VERSION "dbc-export 1 2026.26.6.5"

NS_ :

BS_:

BU_: APP APS BMS CC CMP CMPD CP DAS DI DIF DIR EPBL EPBR EVSE FC GTW HCML HCMR HVP ICR PCS PCS2 PLG PM PMF PMR PTC SCCM SCM SCS SDCR TAS UMC V2G VC VCBATT VCBATT0 VCBATT1 VCBATT2 VCFRONT VCFRONT1 VCFRONT2 VCLEFT VCRIGHT VCSEAT2L VCSEAT2R VCSEC

BO_ 1351 VCFRONT2_alertLog: 8 VCFRONT2
 SG_ VCFRONT2_alertID M : 0|10@1+ (1,0) [0|1023] "" Vector__XXX
 SG_ VCFRONT2_alertState : 15|1@1+ (1,0) [0|1] "" Vector__XXX
 SG_ VCFRONT2_a001_InternalWatchdog m1 : 16|1@1+ (1,0) [0|1] "" Vector__XXX
 SG_ VCFRONT2_a015_NVMMMemOverflow m15 : 16|1@1+ (1,0) [0|1] "" Vector__XXX
 SG_ VCFRONT2_a015_NVMMFilesystemErro m15 : 17|1@1+ (1,0) [0|1] "" Vector__XXX
 SG_ VCFRONT2_a015_NVMMRecordIDError m15 : 18|1@1+ (1,0) [0|1] "" Vector__XXX
 SG_ VCFRONT2_a059_voltageDrop m59 : 16|12@1+ (0.005443676,0) [0|22.29185322] "V" Vector__XXX
 SG_ VCFRONT2_a059_resistanceEstimate m59 : 28|12@1+ (0.00244,0) [0|9.9918] "Ohms" Vector__XXX
 SG_ VCFRONT2_a059_current m59 : 40|12@1+ (0.05,0) [0|204.75] "A" Vector__XXX
 SG_ VCFRONT2_a063_switchChannel m63 : 16|8@1+ (1,0) [0|255] "" Vector__XXX
 SG_ VCFRONT2_a063_switchType m63 : 24|8@1+ (1,0) [0|255] "" Vector__XXX
 SG_ VCFRONT2_a063_ADCVoltage m63 : 32|8@1+ (0.025,0) [0|6.375] "V" Vector__XXX
 SG_ VCFRONT2_a063_disconnected m63 : 40|1@1+ (1,0) [0|1] "" Vector__XXX
 SG_ VCFRONT2_a063_indeterminate m63 : 41|1@1+ (1,0) [0|1] "" Vector__XXX
 SG_ VCFRONT2_a063_stuckActive m63 : 42|1@1+ (1,0) [0|1] "" Vector__XXX
 SG_ VCFRONT2_a063_faulted m63 : 43|1@1+ (1,0) [0|1] "" Vector__XXX
 SG_ VCFRONT2_a091_FRONTIPC_faultsAnd m91 : 16|1@1+ (1,0) [0|1] "" Vector__XXX
 SG_ VCFRONT2_a091_FRONTIPC_state m91 : 17|1@1+ (1,0) [0|1] "" Vector__XXX
 SG_ VCFRONT2_a096_FRONTIPC_status m96 : 16|1@1+ (1,0) [0|1] "" Vector__XXX
 SG_ VCFRONT2_a098_FRONTIPC_temperatu m98 : 16|1@1+ (1,0) [0|1] "" Vector__XXX
 SG_ VCFRONT2_a098_FRONTIPC_thermalCo m98 : 17|1@1+ (1,0) [0|1] "" Vector__XXX
 SG_ VCFRONT2_a106_BATTIPC_dcdcRailSt m106 : 16|1@1+ (1,0) [0|1] "" Vector__XXX
 SG_ VCFRONT2_a106_BATTIPC_dcdcStatus m106 : 17|1@1+ (1,0) [0|1] "" Vector__XXX
 SG_ VCFRONT2_a106_VEH_dcdcStatus m106 : 18|1@1+ (1,0) [0|1] "" Vector__XXX
 SG_ VCFRONT2_a106_VEH_thermalControl m106 : 19|1@1+ (1,0) [0|1] "" Vector__XXX
 SG_ VCFRONT2_a106_VEH_dcdcRailStatus m106 : 20|1@1+ (1,0) [0|1] "" Vector__XXX
 SG_ VCFRONT2_a106_CH_dcdcRailStatus m106 : 21|1@1+ (1,0) [0|1] "" Vector__XXX
 SG_ VCFRONT2_a106_CH_alertMatrix m106 : 22|1@1+ (1,0) [0|1] "" Vector__XXX
 SG_ VCFRONT2_a106_FRONTIPC_thermalCo m106 : 23|1@1+ (1,0) [0|1] "" Vector__XXX
 SG_ VCFRONT2_a106_FRONTIPC_dcdcRailS m106 : 24|1@1+ (1,0) [0|1] "" Vector__XXX
 SG_ VCFRONT2_a106_FRONTIPC_dcdcStatu m106 : 25|1@1+ (1,0) [0|1] "" Vector__XXX
 SG_ VCFRONT2_a108_FRONTIPC_status m108 : 16|1@1+ (1,0) [0|1] "" Vector__XXX
 SG_ VCFRONT2_a108_FRONTIPC_temperatu m108 : 17|1@1+ (1,0) [0|1] "" Vector__XXX
 SG_ VCFRONT2_a108_FRONTIPC_thermalCo m108 : 18|1@1+ (1,0) [0|1] "" Vector__XXX
 SG_ VCFRONT2_a108_FRONTIPC_motorStat m108 : 19|1@1+ (1,0) [0|1] "" Vector__XXX
 SG_ VCFRONT2_a120_BATTIPC_speed m120 : 16|1@1+ (1,0) [0|1] "" Vector__XXX
 SG_ VCFRONT2_a120_FRONTIPC_speed m120 : 17|1@1+ (1,0) [0|1] "" Vector__XXX
 SG_ VCFRONT2_a120_FRONTIPC_systemSta m120 : 18|1@1+ (1,0) [0|1] "" Vector__XXX
 SG_ VCFRONT2_a120_BATTIPC_systemStat m120 : 19|1@1+ (1,0) [0|1] "" Vector__XXX
 SG_ VCFRONT2_a120_FRONTIPC_systemPow m120 : 20|1@1+ (1,0) [0|1] "" Vector__XXX
 SG_ VCFRONT2_a120_FRONTIPC_autonomyH m120 : 21|1@1+ (1,0) [0|1] "" Vector__XXX
 SG_ VCFRONT2_a120_BATTIPC_chassisCon m120 : 22|1@1+ (1,0) [0|1] "" Vector__XXX
 SG_ VCFRONT2_a120_FRONTIPC_chassisCo m120 : 23|1@1+ (1,0) [0|1] "" Vector__XXX
 SG_ VCFRONT2_a120_FRONTIPC_odometerS m120 : 24|1@1+ (1,0) [0|1] "" Vector__XXX
 SG_ VCFRONT2_a124_FRONTIPC_status m124 : 16|1@1+ (1,0) [0|1] "" Vector__XXX
 SG_ VCFRONT2_a124_BATTIPC_status m124 : 17|1@1+ (1,0) [0|1] "" Vector__XXX
 SG_ VCFRONT2_a125_FRONTIPC_leftStalk m125 : 16|1@1+ (1,0) [0|1] "" Vector__XXX
 SG_ VCFRONT2_a125_FRONTIPC_steerAngl m125 : 17|1@1+ (1,0) [0|1] "" Vector__XXX
 SG_ VCFRONT2_a125_FRONTIPC_info m125 : 18|1@1+ (1,0) [0|1] "" Vector__XXX
 SG_ VCFRONT2_a126_FRONTIPC_sysStatus m126 : 16|1@1+ (1,0) [0|1] "" Vector__XXX
 SG_ VCFRONT2_a126_BATTIPC_sysStatus m126 : 17|1@1+ (1,0) [0|1] "" Vector__XXX
 SG_ VCFRONT2_a126_FRONTIPC_status m126 : 18|1@1+ (1,0) [0|1] "" Vector__XXX
 SG_ VCFRONT2_a126_BATTIPC_status m126 : 19|1@1+ (1,0) [0|1] "" Vector__XXX
 SG_ VCFRONT2_a131_FRONTIPC_power m131 : 16|1@1+ (1,0) [0|1] "" Vector__XXX
 SG_ VCFRONT2_a131_BATTIPC_power m131 : 17|1@1+ (1,0) [0|1] "" Vector__XXX
 SG_ VCFRONT2_a133_BATTIPC_primaryAct m133 : 16|1@1+ (1,0) [0|1] "" Vector__XXX
 SG_ VCFRONT2_a133_FRONTIPC_secondary m133 : 17|1@1+ (1,0) [0|1] "" Vector__XXX
 SG_ VCFRONT2_a142_driverState m142 : 16|4@1+ (1,0) [0|15] "" Vector__XXX
 SG_ VCFRONT2_a142_driverThermWarn m142 : 20|1@1+ (1,0) [0|1] "" Vector__XXX
 SG_ VCFRONT2_a142_driverThermShutdow m142 : 21|1@1+ (1,0) [0|1] "" Vector__XXX
 SG_ VCFRONT2_a142_undervoltage m142 : 22|1@1+ (1,0) [0|1] "" Vector__XXX
 SG_ VCFRONT2_a142_chargePumpUndervol m142 : 23|1@1+ (1,0) [0|1] "" Vector__XXX
 SG_ VCFRONT2_a142_isCoilOpenX m142 : 24|1@1+ (1,0) [0|1] "" Vector__XXX
 SG_ VCFRONT2_a142_isCoilOpenY m142 : 25|1@1+ (1,0) [0|1] "" Vector__XXX
 SG_ VCFRONT2_a142_isCoilShortXPGnd m142 : 26|1@1+ (1,0) [0|1] "" Vector__XXX
 SG_ VCFRONT2_a142_isCoilShortXPVbb m142 : 27|1@1+ (1,0) [0|1] "" Vector__XXX
 SG_ VCFRONT2_a142_isCoilShortXNGnd m142 : 28|1@1+ (1,0) [0|1] "" Vector__XXX
 SG_ VCFRONT2_a142_isCoilShortXNVbb m142 : 29|1@1+ (1,0) [0|1] "" Vector__XXX
 SG_ VCFRONT2_a142_isCoilShortYPGnd m142 : 30|1@1+ (1,0) [0|1] "" Vector__XXX
 SG_ VCFRONT2_a142_isCoilShortYPVbb m142 : 31|1@1+ (1,0) [0|1] "" Vector__XXX
 SG_ VCFRONT2_a142_isCoilShortYNGnd m142 : 32|1@1+ (1,0) [0|1] "" Vector__XXX
 SG_ VCFRONT2_a142_isCoilShortYNVbb m142 : 33|1@1+ (1,0) [0|1] "" Vector__XXX
 SG_ VCFRONT2_a142_driverHasCommError m142 : 34|1@1+ (1,0) [0|1] "" Vector__XXX
 SG_ VCFRONT2_a144_FRONTIPC_status m144 : 16|1@1+ (1,0) [0|1] "" Vector__XXX
 SG_ VCFRONT2_a144_BATTIPC_status m144 : 17|1@1+ (1,0) [0|1] "" Vector__XXX
 SG_ VCFRONT2_a150_RPMActual m150 : 16|10@1+ (10,0) [0|10230] "RPM" Vector__XXX
 SG_ VCFRONT2_a150_RPMTarget m150 : 26|10@1+ (10,0) [0|10230] "RPM" Vector__XXX
 SG_ VCFRONT2_a159_stall m159 : 16|1@1+ (1,0) [0|1] "" Vector__XXX
 SG_ VCFRONT2_a159_angleActual m159 : 17|10@1+ (0.25,-70) [-70|185.75] "deg" Vector__XXX
 SG_ VCFRONT2_a159_angleTarget m159 : 27|10@1+ (0.25,-10) [-10|245.75] "deg" Vector__XXX
 SG_ VCFRONT2_a171_VCFRONT m171 : 16|1@1+ (1,0) [0|1] "" Vector__XXX
 SG_ VCFRONT2_a171_VCRIGHT m171 : 17|1@1+ (1,0) [0|1] "" Vector__XXX
 SG_ VCFRONT2_a171_VCLEFT m171 : 18|1@1+ (1,0) [0|1] "" Vector__XXX
 SG_ VCFRONT2_a171_VCBATT m171 : 19|1@1+ (1,0) [0|1] "" Vector__XXX
 SG_ VCFRONT2_a171_BMS m171 : 20|1@1+ (1,0) [0|1] "" Vector__XXX
 SG_ VCFRONT2_a171_HVP m171 : 21|1@1+ (1,0) [0|1] "" Vector__XXX
 SG_ VCFRONT2_a171_GTW m171 : 22|1@1+ (1,0) [0|1] "" Vector__XXX
 SG_ VCFRONT2_a171_CP m171 : 23|1@1+ (1,0) [0|1] "" Vector__XXX
 SG_ VCFRONT2_a171_PCS m171 : 24|1@1+ (1,0) [0|1] "" Vector__XXX
 SG_ VCFRONT2_a171_PCSCPU2 m171 : 25|1@1+ (1,0) [0|1] "" Vector__XXX
 SG_ VCFRONT2_a171_DI m171 : 26|1@1+ (1,0) [0|1] "" Vector__XXX
 SG_ VCFRONT2_a171_DIS m171 : 27|1@1+ (1,0) [0|1] "" Vector__XXX
 SG_ VCFRONT2_a171_PM m171 : 28|1@1+ (1,0) [0|1] "" Vector__XXX
 SG_ VCFRONT2_a171_PMS m171 : 29|1@1+ (1,0) [0|1] "" Vector__XXX
 SG_ VCFRONT2_a171_EPBR m171 : 30|1@1+ (1,0) [0|1] "" Vector__XXX
 SG_ VCFRONT2_a171_EPBL m171 : 31|1@1+ (1,0) [0|1] "" Vector__XXX
 SG_ VCFRONT2_a171_IBST m171 : 32|1@1+ (1,0) [0|1] "" Vector__XXX
 SG_ VCFRONT2_a171_IBSTCAL m171 : 33|1@1+ (1,0) [0|1] "" Vector__XXX
 SG_ VCFRONT2_a171_ESP m171 : 34|1@1+ (1,0) [0|1] "" Vector__XXX
 SG_ VCFRONT2_a171_ESPCAL m171 : 35|1@1+ (1,0) [0|1] "" Vector__XXX
 SG_ VCFRONT2_a171_OPC m171 : 36|1@1+ (1,0) [0|1] "" Vector__XXX
 SG_ VCFRONT2_a171_OPCS m171 : 37|1@1+ (1,0) [0|1] "" Vector__XXX
 SG_ VCFRONT2_a171_SCCM m171 : 38|1@1+ (1,0) [0|1] "" Vector__XXX
 SG_ VCFRONT2_a171_LVBMS m171 : 39|1@1+ (1,0) [0|1] "" Vector__XXX
 SG_ VCFRONT2_a171_IDB m171 : 40|1@1+ (1,0) [0|1] "" Vector__XXX
 SG_ VCFRONT2_a171_IDB1 m171 : 41|1@1+ (1,0) [0|1] "" Vector__XXX
 SG_ VCFRONT2_a171_IDBCAL m171 : 42|1@1+ (1,0) [0|1] "" Vector__XXX
 SG_ VCFRONT2_a171_RCU m171 : 43|1@1+ (1,0) [0|1] "" Vector__XXX
 SG_ VCFRONT2_a171_RCUCAL m171 : 44|1@1+ (1,0) [0|1] "" Vector__XXX
 SG_ VCFRONT2_a171_DPB m171 : 45|1@1+ (1,0) [0|1] "" Vector__XXX
 SG_ VCFRONT2_a171_DPBCAL m171 : 46|1@1+ (1,0) [0|1] "" Vector__XXX
 SG_ VCFRONT2_a171_serviceMode m171 : 47|1@1+ (1,0) [0|1] "" Vector__XXX
 SG_ VCFRONT2_a172_ECUMismatchBits m172 : 16|47@1+ (1,0) [0|140737488355327] "" Vector__XXX
 SG_ VCFRONT2_a172_serviceMode m172 : 63|1@1+ (1,0) [0|1] "" Vector__XXX
 SG_ VCFRONT2_a173_ECUMismatchBits m173 : 16|47@1+ (1,0) [0|140737488355327] "" Vector__XXX
 SG_ VCFRONT2_a173_serviceMode m173 : 63|1@1+ (1,0) [0|1] "" Vector__XXX
 SG_ VCFRONT2_a176_vehicleState m176 : 16|5@1+ (1,0) [0|31] "" Vector__XXX
 SG_ VCFRONT2_a186_noDriveChgCableCon m186 : 16|1@1+ (1,0) [0|1] "" Vector__XXX
 SG_ VCFRONT2_a187_vehBusRetryCount m187 : 16|9@1+ (1,0) [0|511] "" Vector__XXX
 SG_ VCFRONT2_a187_partyBusRetryCount m187 : 25|9@1+ (1,0) [0|511] "" Vector__XXX
 SG_ VCFRONT2_a187_hvsBusRetryCount m187 : 34|9@1+ (1,0) [0|511] "" Vector__XXX
 SG_ VCFRONT2_a187_ethBusRetryCount m187 : 43|9@1+ (1,0) [0|511] "" Vector__XXX
 SG_ VCFRONT2_a187_chBusRetryCount m187 : 52|9@1+ (1,0) [0|511] "" Vector__XXX
 SG_ VCFRONT2_a195_LVVoltage m195 : 16|12@1+ (0.005443676,0) [0|22.29185322] "V" Vector__XXX
 SG_ VCFRONT2_a195_serviceMode m195 : 28|1@1+ (1,0) [0|1] "" Vector__XXX
 SG_ VCFRONT2_a195_frunkOpen m195 : 29|1@1+ (1,0) [0|1] "" Vector__XXX
 SG_ VCFRONT2_a210_valveUnderTravel m210 : 16|1@1+ (1,0) [0|1] "" Vector__XXX
 SG_ VCFRONT2_a210_valveOverTravel m210 : 17|1@1+ (1,0) [0|1] "" Vector__XXX
 SG_ VCFRONT2_a210_valveNoTravel m210 : 18|1@1+ (1,0) [0|1] "" Vector__XXX
 SG_ VCFRONT2_a214_motorFaulted m214 : 16|1@1+ (1,0) [0|1] "" Vector__XXX
 SG_ VCFRONT2_a214_motorLocked m214 : 17|1@1+ (1,0) [0|1] "" Vector__XXX
 SG_ VCFRONT2_a214_ecuReset m214 : 18|1@1+ (1,0) [0|1] "" Vector__XXX
 SG_ VCFRONT2_a214_fetTempIrrational m214 : 19|1@1+ (1,0) [0|1] "" Vector__XXX
 SG_ VCFRONT2_a214_motorControlError m214 : 20|1@1+ (1,0) [0|1] "" Vector__XXX
 SG_ VCFRONT2_a214_underVoltage m214 : 21|1@1+ (1,0) [0|1] "" Vector__XXX
 SG_ VCFRONT2_a214_overVoltage m214 : 22|1@1+ (1,0) [0|1] "" Vector__XXX
 SG_ VCFRONT2_a214_hardwareOvercurren m214 : 23|1@1+ (1,0) [0|1] "" Vector__XXX
 SG_ VCFRONT2_a214_motorOpenPhase m214 : 24|1@1+ (1,0) [0|1] "" Vector__XXX
 SG_ VCFRONT2_a214_motorSoftOpenPhase m214 : 25|1@1+ (1,0) [0|1] "" Vector__XXX
 SG_ VCFRONT2_a214_motorOvertemp m214 : 26|1@1+ (1,0) [0|1] "" Vector__XXX
 SG_ VCFRONT2_a214_dcOvercurrent m214 : 27|1@1+ (1,0) [0|1] "" Vector__XXX
 SG_ VCFRONT2_a214_motorStalled m214 : 28|1@1+ (1,0) [0|1] "" Vector__XXX
 SG_ VCFRONT2_a214_selfTestFailed m214 : 29|1@1+ (1,0) [0|1] "" Vector__XXX
 SG_ VCFRONT2_a214_selfTestResult m214 : 32|3@1+ (1,0) [0|7] "" Vector__XXX
 SG_ VCFRONT2_a214_linChecksumError m214 : 35|1@1+ (1,0) [0|1] "" Vector__XXX
 SG_ VCFRONT2_a214_linFramingError m214 : 36|1@1+ (1,0) [0|1] "" Vector__XXX
 SG_ VCFRONT2_a214_phaseShorted m214 : 37|1@1+ (1,0) [0|1] "" Vector__XXX
 SG_ VCFRONT2_a214_busVoltageIrration m214 : 38|1@1+ (1,0) [0|1] "" Vector__XXX
 SG_ VCFRONT2_a214_dcCurrentIrrationa m214 : 39|1@1+ (1,0) [0|1] "" Vector__XXX
 SG_ VCFRONT2_a214_motorSpeedIrration m214 : 40|1@1+ (1,0) [0|1] "" Vector__XXX
 SG_ VCFRONT2_a214_supplyVoltageIrrat m214 : 41|1@1+ (1,0) [0|1] "" Vector__XXX
 SG_ VCFRONT2_a214_motorPhaseCurrentI m214 : 42|1@1+ (1,0) [0|1] "" Vector__XXX
 SG_ VCFRONT2_a214_chipOvertemp m214 : 43|1@1+ (1,0) [0|1] "" Vector__XXX
 SG_ VCFRONT2_a214_motorSpeedTooHigh m214 : 44|1@1+ (1,0) [0|1] "" Vector__XXX
 SG_ VCFRONT2_a214_phaseOvercurrent m214 : 45|1@1+ (1,0) [0|1] "" Vector__XXX
 SG_ VCFRONT2_a214_vddaOvercurrent m214 : 46|1@1+ (1,0) [0|1] "" Vector__XXX
 SG_ VCFRONT2_a214_busVoltageUnhealth m214 : 47|1@1+ (1,0) [0|1] "" Vector__XXX
 SG_ VCFRONT2_a214_hsVdsOvervoltage m214 : 48|1@1+ (1,0) [0|1] "" Vector__XXX
 SG_ VCFRONT2_a214_hsVdsOvervoltageMa m214 : 49|3@1+ (1,0) [0|7] "" Vector__XXX
 SG_ VCFRONT2_a214_lsVdsOvervoltage m214 : 52|1@1+ (1,0) [0|1] "" Vector__XXX
 SG_ VCFRONT2_a214_lsVdsOvervoltageMa m214 : 53|3@1+ (1,0) [0|7] "" Vector__XXX
 SG_ VCFRONT2_a214_payloadBitsNotSet m214 : 56|1@1+ (1,0) [0|1] "" Vector__XXX
 SG_ VCFRONT2_a217_motorFaulted m217 : 16|1@1+ (1,0) [0|1] "" Vector__XXX
 SG_ VCFRONT2_a217_motorLocked m217 : 17|1@1+ (1,0) [0|1] "" Vector__XXX
 SG_ VCFRONT2_a217_ecuReset m217 : 18|1@1+ (1,0) [0|1] "" Vector__XXX
 SG_ VCFRONT2_a217_fetTempIrrational m217 : 19|1@1+ (1,0) [0|1] "" Vector__XXX
 SG_ VCFRONT2_a217_motorControlError m217 : 20|1@1+ (1,0) [0|1] "" Vector__XXX
 SG_ VCFRONT2_a217_underVoltage m217 : 21|1@1+ (1,0) [0|1] "" Vector__XXX
 SG_ VCFRONT2_a217_overVoltage m217 : 22|1@1+ (1,0) [0|1] "" Vector__XXX
 SG_ VCFRONT2_a217_hardwareOvercurren m217 : 23|1@1+ (1,0) [0|1] "" Vector__XXX
 SG_ VCFRONT2_a217_motorOpenPhase m217 : 24|1@1+ (1,0) [0|1] "" Vector__XXX
 SG_ VCFRONT2_a217_motorSoftOpenPhase m217 : 25|1@1+ (1,0) [0|1] "" Vector__XXX
 SG_ VCFRONT2_a217_motorOvertemp m217 : 26|1@1+ (1,0) [0|1] "" Vector__XXX
 SG_ VCFRONT2_a217_dcOvercurrent m217 : 27|1@1+ (1,0) [0|1] "" Vector__XXX
 SG_ VCFRONT2_a217_motorStalled m217 : 28|1@1+ (1,0) [0|1] "" Vector__XXX
 SG_ VCFRONT2_a217_selfTestFailed m217 : 29|1@1+ (1,0) [0|1] "" Vector__XXX
 SG_ VCFRONT2_a217_selfTestResult m217 : 32|3@1+ (1,0) [0|7] "" Vector__XXX
 SG_ VCFRONT2_a217_linChecksumError m217 : 35|1@1+ (1,0) [0|1] "" Vector__XXX
 SG_ VCFRONT2_a217_linFramingError m217 : 36|1@1+ (1,0) [0|1] "" Vector__XXX
 SG_ VCFRONT2_a217_phaseShorted m217 : 37|1@1+ (1,0) [0|1] "" Vector__XXX
 SG_ VCFRONT2_a217_busVoltageIrration m217 : 38|1@1+ (1,0) [0|1] "" Vector__XXX
 SG_ VCFRONT2_a217_dcCurrentIrrationa m217 : 39|1@1+ (1,0) [0|1] "" Vector__XXX
 SG_ VCFRONT2_a217_motorSpeedIrration m217 : 40|1@1+ (1,0) [0|1] "" Vector__XXX
 SG_ VCFRONT2_a217_supplyVoltageIrrat m217 : 41|1@1+ (1,0) [0|1] "" Vector__XXX
 SG_ VCFRONT2_a217_motorPhaseCurrentI m217 : 42|1@1+ (1,0) [0|1] "" Vector__XXX
 SG_ VCFRONT2_a217_chipOvertemp m217 : 43|1@1+ (1,0) [0|1] "" Vector__XXX
 SG_ VCFRONT2_a217_motorSpeedTooHigh m217 : 44|1@1+ (1,0) [0|1] "" Vector__XXX
 SG_ VCFRONT2_a217_phaseOvercurrent m217 : 45|1@1+ (1,0) [0|1] "" Vector__XXX
 SG_ VCFRONT2_a217_vddaOvercurrent m217 : 46|1@1+ (1,0) [0|1] "" Vector__XXX
 SG_ VCFRONT2_a217_busVoltageUnhealth m217 : 47|1@1+ (1,0) [0|1] "" Vector__XXX
 SG_ VCFRONT2_a217_hsVdsOvervoltage m217 : 48|1@1+ (1,0) [0|1] "" Vector__XXX
 SG_ VCFRONT2_a217_hsVdsOvervoltageMa m217 : 49|3@1+ (1,0) [0|7] "" Vector__XXX
 SG_ VCFRONT2_a217_lsVdsOvervoltage m217 : 52|1@1+ (1,0) [0|1] "" Vector__XXX
 SG_ VCFRONT2_a217_lsVdsOvervoltageMa m217 : 53|3@1+ (1,0) [0|7] "" Vector__XXX
 SG_ VCFRONT2_a217_payloadBitsNotSet m217 : 56|1@1+ (1,0) [0|1] "" Vector__XXX
 SG_ VCFRONT2_a235_ptSensorTemp m235 : 16|11@1+ (0.125,-40) [-40|215.875] "degC" Vector__XXX
 SG_ VCFRONT2_a236_batSensorTemp m236 : 16|11@1+ (0.125,-40) [-40|215.875] "degC" Vector__XXX
 SG_ VCFRONT2_a247_solenoidISense m247 : 16|8@1- (0.01,0) [-1.28|1.27] "A" Vector__XXX
 SG_ VCFRONT2_a249_tempCoolantBatInle m249 : 16|10@1+ (0.125,-40) [-40|87.875] "degC" Vector__XXX
 SG_ VCFRONT2_a249_tempCoolantPTInlet m249 : 26|11@1+ (0.125,-40) [-40|215.875] "degC" Vector__XXX
 SG_ VCFRONT2_a254_RPMActual m254 : 16|10@1+ (10,0) [0|10230] "RPM" Vector__XXX
 SG_ VCFRONT2_a254_RPMTarget m254 : 26|10@1+ (10,0) [0|10230] "RPM" Vector__XXX
 SG_ VCFRONT2_a283_thmlFanDisabled m283 : 16|1@1+ (1,0) [0|1] "" Vector__XXX
 SG_ VCFRONT2_a283_thmlFanLimited m283 : 17|1@1+ (1,0) [0|1] "" Vector__XXX
 SG_ VCFRONT2_a283_thmlFanDemand m283 : 24|7@1+ (1,0) [0|127] "%" Vector__XXX
 SG_ VCFRONT2_a283_thmlFanDemandLimit m283 : 32|7@1+ (1,0) [0|127] "%" Vector__XXX
 SG_ VCFRONT2_a283_thmlFanPhaseI m283 : 40|7@1+ (0.25,5) [5|36.75] "A" Vector__XXX
 SG_ VCFRONT2_a283_thmlFanPhaseILimit m283 : 48|7@1+ (0.25,5) [5|36.75] "A" Vector__XXX
 SG_ VCFRONT2_a284_driverState m284 : 16|4@1+ (1,0) [0|15] "" Vector__XXX
 SG_ VCFRONT2_a284_driverThermWarn m284 : 20|1@1+ (1,0) [0|1] "" Vector__XXX
 SG_ VCFRONT2_a284_driverThermShutdow m284 : 21|1@1+ (1,0) [0|1] "" Vector__XXX
 SG_ VCFRONT2_a284_undervoltage m284 : 22|1@1+ (1,0) [0|1] "" Vector__XXX
 SG_ VCFRONT2_a284_chargePumpUndervol m284 : 23|1@1+ (1,0) [0|1] "" Vector__XXX
 SG_ VCFRONT2_a284_isCoilOpenX m284 : 24|1@1+ (1,0) [0|1] "" Vector__XXX
 SG_ VCFRONT2_a284_isCoilOpenY m284 : 25|1@1+ (1,0) [0|1] "" Vector__XXX
 SG_ VCFRONT2_a284_isCoilShortXPGnd m284 : 26|1@1+ (1,0) [0|1] "" Vector__XXX
 SG_ VCFRONT2_a284_isCoilShortXPVbb m284 : 27|1@1+ (1,0) [0|1] "" Vector__XXX
 SG_ VCFRONT2_a284_isCoilShortXNGnd m284 : 28|1@1+ (1,0) [0|1] "" Vector__XXX
 SG_ VCFRONT2_a284_isCoilShortXNVbb m284 : 29|1@1+ (1,0) [0|1] "" Vector__XXX
 SG_ VCFRONT2_a284_isCoilShortYPGnd m284 : 30|1@1+ (1,0) [0|1] "" Vector__XXX
 SG_ VCFRONT2_a284_isCoilShortYPVbb m284 : 31|1@1+ (1,0) [0|1] "" Vector__XXX
 SG_ VCFRONT2_a284_isCoilShortYNGnd m284 : 32|1@1+ (1,0) [0|1] "" Vector__XXX
 SG_ VCFRONT2_a284_isCoilShortYNVbb m284 : 33|1@1+ (1,0) [0|1] "" Vector__XXX
 SG_ VCFRONT2_a284_driverHasCommError m284 : 34|1@1+ (1,0) [0|1] "" Vector__XXX
 SG_ VCFRONT2_a285_driverState m285 : 16|4@1+ (1,0) [0|15] "" Vector__XXX
 SG_ VCFRONT2_a285_driverThermWarn m285 : 20|1@1+ (1,0) [0|1] "" Vector__XXX
 SG_ VCFRONT2_a285_driverThermShutdow m285 : 21|1@1+ (1,0) [0|1] "" Vector__XXX
 SG_ VCFRONT2_a285_undervoltage m285 : 22|1@1+ (1,0) [0|1] "" Vector__XXX
 SG_ VCFRONT2_a285_chargePumpUndervol m285 : 23|1@1+ (1,0) [0|1] "" Vector__XXX
 SG_ VCFRONT2_a285_isCoilOpenX m285 : 24|1@1+ (1,0) [0|1] "" Vector__XXX
 SG_ VCFRONT2_a285_isCoilOpenY m285 : 25|1@1+ (1,0) [0|1] "" Vector__XXX
 SG_ VCFRONT2_a285_isCoilShortXPGnd m285 : 26|1@1+ (1,0) [0|1] "" Vector__XXX
 SG_ VCFRONT2_a285_isCoilShortXPVbb m285 : 27|1@1+ (1,0) [0|1] "" Vector__XXX
 SG_ VCFRONT2_a285_isCoilShortXNGnd m285 : 28|1@1+ (1,0) [0|1] "" Vector__XXX
 SG_ VCFRONT2_a285_isCoilShortXNVbb m285 : 29|1@1+ (1,0) [0|1] "" Vector__XXX
 SG_ VCFRONT2_a285_isCoilShortYPGnd m285 : 30|1@1+ (1,0) [0|1] "" Vector__XXX
 SG_ VCFRONT2_a285_isCoilShortYPVbb m285 : 31|1@1+ (1,0) [0|1] "" Vector__XXX
 SG_ VCFRONT2_a285_isCoilShortYNGnd m285 : 32|1@1+ (1,0) [0|1] "" Vector__XXX
 SG_ VCFRONT2_a285_isCoilShortYNVbb m285 : 33|1@1+ (1,0) [0|1] "" Vector__XXX
 SG_ VCFRONT2_a285_driverHasCommError m285 : 34|1@1+ (1,0) [0|1] "" Vector__XXX
 SG_ VCFRONT2_a286_driverState m286 : 16|4@1+ (1,0) [0|15] "" Vector__XXX
 SG_ VCFRONT2_a286_driverThermWarn m286 : 20|1@1+ (1,0) [0|1] "" Vector__XXX
 SG_ VCFRONT2_a286_driverThermShutdow m286 : 21|1@1+ (1,0) [0|1] "" Vector__XXX
 SG_ VCFRONT2_a286_undervoltage m286 : 22|1@1+ (1,0) [0|1] "" Vector__XXX
 SG_ VCFRONT2_a286_chargePumpUndervol m286 : 23|1@1+ (1,0) [0|1] "" Vector__XXX
 SG_ VCFRONT2_a286_isCoilOpenX m286 : 24|1@1+ (1,0) [0|1] "" Vector__XXX
 SG_ VCFRONT2_a286_isCoilOpenY m286 : 25|1@1+ (1,0) [0|1] "" Vector__XXX
 SG_ VCFRONT2_a286_isCoilShortXPGnd m286 : 26|1@1+ (1,0) [0|1] "" Vector__XXX
 SG_ VCFRONT2_a286_isCoilShortXPVbb m286 : 27|1@1+ (1,0) [0|1] "" Vector__XXX
 SG_ VCFRONT2_a286_isCoilShortXNGnd m286 : 28|1@1+ (1,0) [0|1] "" Vector__XXX
 SG_ VCFRONT2_a286_isCoilShortXNVbb m286 : 29|1@1+ (1,0) [0|1] "" Vector__XXX
 SG_ VCFRONT2_a286_isCoilShortYPGnd m286 : 30|1@1+ (1,0) [0|1] "" Vector__XXX
 SG_ VCFRONT2_a286_isCoilShortYPVbb m286 : 31|1@1+ (1,0) [0|1] "" Vector__XXX
 SG_ VCFRONT2_a286_isCoilShortYNGnd m286 : 32|1@1+ (1,0) [0|1] "" Vector__XXX
 SG_ VCFRONT2_a286_isCoilShortYNVbb m286 : 33|1@1+ (1,0) [0|1] "" Vector__XXX
 SG_ VCFRONT2_a286_driverHasCommError m286 : 34|1@1+ (1,0) [0|1] "" Vector__XXX
 SG_ VCFRONT2_a287_driverState m287 : 16|4@1+ (1,0) [0|15] "" Vector__XXX
 SG_ VCFRONT2_a287_driverThermWarn m287 : 20|1@1+ (1,0) [0|1] "" Vector__XXX
 SG_ VCFRONT2_a287_driverThermShutdow m287 : 21|1@1+ (1,0) [0|1] "" Vector__XXX
 SG_ VCFRONT2_a287_undervoltage m287 : 22|1@1+ (1,0) [0|1] "" Vector__XXX
 SG_ VCFRONT2_a287_chargePumpUndervol m287 : 23|1@1+ (1,0) [0|1] "" Vector__XXX
 SG_ VCFRONT2_a287_isCoilOpenX m287 : 24|1@1+ (1,0) [0|1] "" Vector__XXX
 SG_ VCFRONT2_a287_isCoilOpenY m287 : 25|1@1+ (1,0) [0|1] "" Vector__XXX
 SG_ VCFRONT2_a287_isCoilShortXPGnd m287 : 26|1@1+ (1,0) [0|1] "" Vector__XXX
 SG_ VCFRONT2_a287_isCoilShortXPVbb m287 : 27|1@1+ (1,0) [0|1] "" Vector__XXX
 SG_ VCFRONT2_a287_isCoilShortXNGnd m287 : 28|1@1+ (1,0) [0|1] "" Vector__XXX
 SG_ VCFRONT2_a287_isCoilShortXNVbb m287 : 29|1@1+ (1,0) [0|1] "" Vector__XXX
 SG_ VCFRONT2_a287_isCoilShortYPGnd m287 : 30|1@1+ (1,0) [0|1] "" Vector__XXX
 SG_ VCFRONT2_a287_isCoilShortYPVbb m287 : 31|1@1+ (1,0) [0|1] "" Vector__XXX
 SG_ VCFRONT2_a287_isCoilShortYNGnd m287 : 32|1@1+ (1,0) [0|1] "" Vector__XXX
 SG_ VCFRONT2_a287_isCoilShortYNVbb m287 : 33|1@1+ (1,0) [0|1] "" Vector__XXX
 SG_ VCFRONT2_a287_driverHasCommError m287 : 34|1@1+ (1,0) [0|1] "" Vector__XXX
 SG_ VCFRONT2_a288_driverState m288 : 16|4@1+ (1,0) [0|15] "" Vector__XXX
 SG_ VCFRONT2_a288_driverThermWarn m288 : 20|1@1+ (1,0) [0|1] "" Vector__XXX
 SG_ VCFRONT2_a288_driverThermShutdow m288 : 21|1@1+ (1,0) [0|1] "" Vector__XXX
 SG_ VCFRONT2_a288_undervoltage m288 : 22|1@1+ (1,0) [0|1] "" Vector__XXX
 SG_ VCFRONT2_a288_chargePumpUndervol m288 : 23|1@1+ (1,0) [0|1] "" Vector__XXX
 SG_ VCFRONT2_a288_isCoilOpenX m288 : 24|1@1+ (1,0) [0|1] "" Vector__XXX
 SG_ VCFRONT2_a288_isCoilOpenY m288 : 25|1@1+ (1,0) [0|1] "" Vector__XXX
 SG_ VCFRONT2_a288_isCoilShortXPGnd m288 : 26|1@1+ (1,0) [0|1] "" Vector__XXX
 SG_ VCFRONT2_a288_isCoilShortXPVbb m288 : 27|1@1+ (1,0) [0|1] "" Vector__XXX
 SG_ VCFRONT2_a288_isCoilShortXNGnd m288 : 28|1@1+ (1,0) [0|1] "" Vector__XXX
 SG_ VCFRONT2_a288_isCoilShortXNVbb m288 : 29|1@1+ (1,0) [0|1] "" Vector__XXX
 SG_ VCFRONT2_a288_isCoilShortYPGnd m288 : 30|1@1+ (1,0) [0|1] "" Vector__XXX
 SG_ VCFRONT2_a288_isCoilShortYPVbb m288 : 31|1@1+ (1,0) [0|1] "" Vector__XXX
 SG_ VCFRONT2_a288_isCoilShortYNGnd m288 : 32|1@1+ (1,0) [0|1] "" Vector__XXX
 SG_ VCFRONT2_a288_isCoilShortYNVbb m288 : 33|1@1+ (1,0) [0|1] "" Vector__XXX
 SG_ VCFRONT2_a288_driverHasCommError m288 : 34|1@1+ (1,0) [0|1] "" Vector__XXX
 SG_ VCFRONT2_a289_driverState m289 : 16|4@1+ (1,0) [0|15] "" Vector__XXX
 SG_ VCFRONT2_a289_driverThermWarn m289 : 20|1@1+ (1,0) [0|1] "" Vector__XXX
 SG_ VCFRONT2_a289_driverThermShutdow m289 : 21|1@1+ (1,0) [0|1] "" Vector__XXX
 SG_ VCFRONT2_a289_undervoltage m289 : 22|1@1+ (1,0) [0|1] "" Vector__XXX
 SG_ VCFRONT2_a289_chargePumpUndervol m289 : 23|1@1+ (1,0) [0|1] "" Vector__XXX
 SG_ VCFRONT2_a289_isCoilOpenX m289 : 24|1@1+ (1,0) [0|1] "" Vector__XXX
 SG_ VCFRONT2_a289_isCoilOpenY m289 : 25|1@1+ (1,0) [0|1] "" Vector__XXX
 SG_ VCFRONT2_a289_isCoilShortXPGnd m289 : 26|1@1+ (1,0) [0|1] "" Vector__XXX
 SG_ VCFRONT2_a289_isCoilShortXPVbb m289 : 27|1@1+ (1,0) [0|1] "" Vector__XXX
 SG_ VCFRONT2_a289_isCoilShortXNGnd m289 : 28|1@1+ (1,0) [0|1] "" Vector__XXX
 SG_ VCFRONT2_a289_isCoilShortXNVbb m289 : 29|1@1+ (1,0) [0|1] "" Vector__XXX
 SG_ VCFRONT2_a289_isCoilShortYPGnd m289 : 30|1@1+ (1,0) [0|1] "" Vector__XXX
 SG_ VCFRONT2_a289_isCoilShortYPVbb m289 : 31|1@1+ (1,0) [0|1] "" Vector__XXX
 SG_ VCFRONT2_a289_isCoilShortYNGnd m289 : 32|1@1+ (1,0) [0|1] "" Vector__XXX
 SG_ VCFRONT2_a289_isCoilShortYNVbb m289 : 33|1@1+ (1,0) [0|1] "" Vector__XXX
 SG_ VCFRONT2_a289_driverHasCommError m289 : 34|1@1+ (1,0) [0|1] "" Vector__XXX
 SG_ VCFRONT2_a302_LINFrameStatus m302 : 16|3@1+ (1,0) [0|7] "" Vector__XXX
 SG_ VCFRONT2_a355_fluidNotFilled m355 : 16|1@1+ (1,0) [0|1] "" Vector__XXX
 SG_ VCFRONT2_a355_systemNotCommissio m355 : 17|1@1+ (1,0) [0|1] "" Vector__XXX
 SG_ VCFRONT2_a355_serviceLockout m355 : 18|1@1+ (1,0) [0|1] "" Vector__XXX
 SG_ VCFRONT2_a355_factoryGated m355 : 19|1@1+ (1,0) [0|1] "" Vector__XXX
 SG_ VCFRONT2_a356_fluidNotFilled m356 : 16|1@1+ (1,0) [0|1] "" Vector__XXX
 SG_ VCFRONT2_a356_systemNotCommissio m356 : 17|1@1+ (1,0) [0|1] "" Vector__XXX
 SG_ VCFRONT2_a356_serviceLockout m356 : 18|1@1+ (1,0) [0|1] "" Vector__XXX
 SG_ VCFRONT2_a356_factoryGated m356 : 19|1@1+ (1,0) [0|1] "" Vector__XXX
 SG_ VCFRONT2_a356_refCommissionStatu m356 : 20|1@1+ (1,0) [0|1] "" Vector__XXX
 SG_ VCFRONT2_a360_vehicleLoadShedAct m360 : 16|1@1+ (1,0) [0|1] "" Vector__XXX
 SG_ VCFRONT2_a360_notEnoughPowerForS m360 : 17|1@1+ (1,0) [0|1] "" Vector__XXX
 SG_ VCFRONT2_a367_bmsSoc m367 : 16|8@1+ (0.5,0) [0|127.5] "%" Vector__XXX
 SG_ VCFRONT2_a368_bmsRequestRemoved m368 : 16|1@1+ (1,0) [0|1] "" Vector__XXX
 SG_ VCFRONT2_a368_enteringState m368 : 17|3@1+ (1,0) [0|7] "" Vector__XXX
 SG_ VCFRONT2_a368_exitingState m368 : 20|3@1+ (1,0) [0|7] "" Vector__XXX
 SG_ VCFRONT2_a368_bmsSoc m368 : 24|8@1+ (0.5,0) [0|127.5] "%" Vector__XXX
 SG_ VCFRONT2_a368_systemFaulted m368 : 32|1@1+ (1,0) [0|1] "" Vector__XXX
 SG_ VCFRONT2_a368_coolantTempSensors m368 : 33|1@1+ (1,0) [0|1] "" Vector__XXX
 SG_ VCFRONT2_a368_coolantValveFaulte m368 : 34|1@1+ (1,0) [0|1] "" Vector__XXX
 SG_ VCFRONT2_a368_louverFaulted m368 : 35|1@1+ (1,0) [0|1] "" Vector__XXX
 SG_ VCFRONT2_a368_fansFaulted m368 : 36|1@1+ (1,0) [0|1] "" Vector__XXX
 SG_ VCFRONT2_a368_coolantNotFilled m368 : 37|1@1+ (1,0) [0|1] "" Vector__XXX
 SG_ VCFRONT2_a368_coolantPumpsFaulte m368 : 38|1@1+ (1,0) [0|1] "" Vector__XXX
 SG_ VCFRONT2_a368_preconditionsNotMe m368 : 39|1@1+ (1,0) [0|1] "" Vector__XXX
 SG_ VCFRONT2_a368_belowSocMin m368 : 40|1@1+ (1,0) [0|1] "" Vector__XXX
 SG_ VCFRONT2_a369_powerGenerationLim m369 : 16|1@1+ (1,0) [0|1] "" Vector__XXX
 SG_ VCFRONT2_a369_heatRejectionLimit m369 : 17|1@1+ (1,0) [0|1] "" Vector__XXX
 SG_ VCFRONT2_a369_bmsSoc m369 : 24|8@1+ (0.5,0) [0|127.5] "%" Vector__XXX
 SG_ VCFRONT2_a369_wasteHeatPower m369 : 32|7@1+ (100,0) [0|12700] "W" Vector__XXX
 SG_ VCFRONT2_a374_lccInletSolenoidIS m374 : 16|8@1- (0.01,0) [-1.28|1.27] "A" Vector__XXX
 SG_ VCFRONT2_a377_wiperStuckOutOfPar m377 : 16|1@1+ (1,0) [0|1] "" Vector__XXX
 SG_ VCFRONT2_a377_wiperStuckInPark m377 : 17|1@1+ (1,0) [0|1] "" Vector__XXX
 SG_ VCFRONT2_a397_discharge m397 : 16|1@1+ (1,0) [0|1] "" Vector__XXX
 SG_ VCFRONT2_a397_suction m397 : 17|1@1+ (1,0) [0|1] "" Vector__XXX
 SG_ VCFRONT2_a397_liquid m397 : 18|1@1+ (1,0) [0|1] "" Vector__XXX
 SG_ VCFRONT2_a397_offsetError m397 : 19|10@1- (0.2,0) [-102.4|102.2] "C" Vector__XXX
 SG_ VCFRONT2_a397_runTimeOffSetDetec m397 : 29|1@1+ (1,0) [0|1] "" Vector__XXX
 SG_ VCFRONT2_a409_brushlessMotorConf m409 : 16|1@1+ (1,0) [0|1] "" Vector__XXX
 SG_ VCFRONT2_a446_compFaultRefrigera m446 : 16|1@1+ (1,0) [0|1] "" Vector__XXX
 SG_ VCFRONT2_a446_compFaultTdHigh m446 : 17|1@1+ (1,0) [0|1] "" Vector__XXX
 SG_ VCFRONT2_a446_compFaultPdLow m446 : 18|1@1+ (1,0) [0|1] "" Vector__XXX
 SG_ VCFRONT2_a446_compFaultPdHigh m446 : 19|1@1+ (1,0) [0|1] "" Vector__XXX
 SG_ VCFRONT2_a446_compFaultPsLow m446 : 20|1@1+ (1,0) [0|1] "" Vector__XXX
 SG_ VCFRONT2_a446_compStandbyLowAmbi m446 : 21|1@1+ (1,0) [0|1] "" Vector__XXX
 SG_ VCFRONT2_a446_compStandbyLowDisc m446 : 22|1@1+ (1,0) [0|1] "" Vector__XXX
 SG_ VCFRONT2_a446_compStandbyHVNotRe m446 : 23|1@1+ (1,0) [0|1] "" Vector__XXX
 SG_ VCFRONT2_a446_compStandbyCommuni m446 : 24|1@1+ (1,0) [0|1] "" Vector__XXX
 SG_ VCFRONT2_a446_compStandbySelfNot m446 : 25|1@1+ (1,0) [0|1] "" Vector__XXX
 SG_ VCFRONT2_a446_compStandbyRefrigN m446 : 26|1@1+ (1,0) [0|1] "" Vector__XXX
 SG_ VCFRONT2_a446_compStandbyCoastDo m446 : 27|1@1+ (1,0) [0|1] "" Vector__XXX
 SG_ VCFRONT2_a446_compStandbyMultipl m446 : 28|1@1+ (1,0) [0|1] "" Vector__XXX
 SG_ VCFRONT2_a446_compStandbyShowroo m446 : 29|1@1+ (1,0) [0|1] "" Vector__XXX
 SG_ VCFRONT2_a446_compStandbyMu_0001 m446 : 30|1@1+ (1,0) [0|1] "" Vector__XXX
 SG_ VCFRONT2_a446_hpCabinLoadType m446 : 31|2@1+ (1,0) [0|3] "" Vector__XXX
 SG_ VCFRONT2_a446_hpBatteryLoadType m446 : 33|2@1+ (1,0) [0|3] "" Vector__XXX
 SG_ VCFRONT2_a446_usingModeledPs m446 : 35|1@1+ (1,0) [0|1] "" Vector__XXX
 SG_ VCFRONT2_a446_usingModeledPd m446 : 36|1@1+ (1,0) [0|1] "" Vector__XXX
 SG_ VCFRONT2_a446_usingModeledPl m446 : 37|1@1+ (1,0) [0|1] "" Vector__XXX
 SG_ VCFRONT2_a446_usingModeledTs m446 : 38|1@1+ (1,0) [0|1] "" Vector__XXX
 SG_ VCFRONT2_a446_usingModeledTd m446 : 39|1@1+ (1,0) [0|1] "" Vector__XXX
 SG_ VCFRONT2_a446_usingModeledTl m446 : 40|1@1+ (1,0) [0|1] "" Vector__XXX
 SG_ VCFRONT2_a446_sensorHasOffsetTd m446 : 41|1@1+ (1,0) [0|1] "" Vector__XXX
 SG_ VCFRONT2_a446_sensorHasOffsetPd m446 : 42|1@1+ (1,0) [0|1] "" Vector__XXX
 SG_ VCFRONT2_a446_sensorDroopPd m446 : 43|1@1+ (1,0) [0|1] "" Vector__XXX
 SG_ VCFRONT2_a446_sensorHasOffsetTl m446 : 44|1@1+ (1,0) [0|1] "" Vector__XXX
 SG_ VCFRONT2_a446_sensorIntermi_0002 m446 : 45|1@1+ (1,0) [0|1] "" Vector__XXX
 SG_ VCFRONT2_a446_sensorIntermittent m446 : 46|1@1+ (1,0) [0|1] "" Vector__XXX
 SG_ VCFRONT2_a446_sensorIntermi_0001 m446 : 47|1@1+ (1,0) [0|1] "" Vector__XXX
 SG_ VCFRONT2_a446_sensorIntermi_0005 m446 : 48|1@1+ (1,0) [0|1] "" Vector__XXX
 SG_ VCFRONT2_a446_sensorIntermi_0003 m446 : 49|1@1+ (1,0) [0|1] "" Vector__XXX
 SG_ VCFRONT2_a446_sensorIntermi_0004 m446 : 50|1@1+ (1,0) [0|1] "" Vector__XXX
 SG_ VCFRONT2_a446_highSuctionSuperhe m446 : 51|1@1+ (1,0) [0|1] "" Vector__XXX
 SG_ VCFRONT2_a446_evapLowPsCutout m446 : 52|1@1+ (1,0) [0|1] "" Vector__XXX
 SG_ VCFRONT2_a446_batteryOverTemp m446 : 53|1@1+ (1,0) [0|1] "" Vector__XXX
 SG_ VCFRONT2_a446_hvacSystemFault m446 : 54|1@1+ (1,0) [0|1] "" Vector__XXX
 SG_ VCFRONT2_a446_coolantSysLockedOu m446 : 55|1@1+ (1,0) [0|1] "" Vector__XXX
 SG_ VCFRONT2_a446_refSysLockedOut m446 : 56|1@1+ (1,0) [0|1] "" Vector__XXX
 SG_ VCFRONT2_a446_chillerEXVNotReady m446 : 57|1@1+ (1,0) [0|1] "" Vector__XXX
 SG_ VCFRONT2_a446_CCLEXVNotReady m446 : 58|1@1+ (1,0) [0|1] "" Vector__XXX
 SG_ VCFRONT2_a446_CCREXVNotReady m446 : 59|1@1+ (1,0) [0|1] "" Vector__XXX
 SG_ VCFRONT2_a446_LCCEXVNotReady m446 : 60|1@1+ (1,0) [0|1] "" Vector__XXX
 SG_ VCFRONT2_a446_evapEXVNotReady m446 : 61|1@1+ (1,0) [0|1] "" Vector__XXX
 SG_ VCFRONT2_a446_recircEXVNotReady m446 : 62|1@1+ (1,0) [0|1] "" Vector__XXX
 SG_ VCFRONT2_a446_checkA447Alert m446 : 63|1@1+ (1,0) [0|1] "" Vector__XXX
 SG_ VCFRONT2_a447_caseHVACUnavailabl m447 : 16|1@1+ (1,0) [0|1] "" Vector__XXX
 SG_ VCFRONT2_a447_heatPumpHVACUnavai m447 : 17|1@1+ (1,0) [0|1] "" Vector__XXX
 SG_ VCFRONT2_a447_activeLouverCompro m447 : 18|1@1+ (1,0) [0|1] "" Vector__XXX
 SG_ VCFRONT2_a447_coolantValveCompro m447 : 19|1@1+ (1,0) [0|1] "" Vector__XXX
 SG_ VCFRONT2_a447_ambientSourcingCom m447 : 20|1@1+ (1,0) [0|1] "" Vector__XXX
 SG_ VCFRONT2_a447_scavengeLoopCompro m447 : 21|1@1+ (1,0) [0|1] "" Vector__XXX
 SG_ VCFRONT2_a447_coolantSystemCompr m447 : 22|1@1+ (1,0) [0|1] "" Vector__XXX
 SG_ VCFRONT2_a447_hvBattActiveDischg m447 : 23|1@1+ (1,0) [0|1] "" Vector__XXX
 SG_ VCFRONT2_a447_hvBatteryDischargi m447 : 24|1@1+ (1,0) [0|1] "" Vector__XXX
 SG_ VCFRONT2_a447_lccSolenoidComprom m447 : 25|1@1+ (1,0) [0|1] "" Vector__XXX
 SG_ VCFRONT2_a447_refrigerantSystemC m447 : 26|1@1+ (1,0) [0|1] "" Vector__XXX
 SG_ VCFRONT2_a447_powertrainThermalF m447 : 27|1@1+ (1,0) [0|1] "" Vector__XXX
 SG_ VCFRONT2_a447_refrigDischargePre m447 : 28|1@1+ (1,0) [0|1] "" Vector__XXX
 SG_ VCFRONT2_a447_refrigeDischargeTe m447 : 29|1@1+ (1,0) [0|1] "" Vector__XXX
 SG_ VCFRONT2_a447_refrigSuctionPress m447 : 30|1@1+ (1,0) [0|1] "" Vector__XXX
 SG_ VCFRONT2_a447_refrigSuctionTempC m447 : 31|1@1+ (1,0) [0|1] "" Vector__XXX
 SG_ VCFRONT2_a447_refrigLiquidPressC m447 : 32|1@1+ (1,0) [0|1] "" Vector__XXX
 SG_ VCFRONT2_a447_refrigLiquidTempCo m447 : 33|1@1+ (1,0) [0|1] "" Vector__XXX
 SG_ VCFRONT2_a459_coolantFillActive m459 : 16|1@1+ (1,0) [0|1] "" Vector__XXX
 SG_ VCFRONT2_a459_refrigerantFillAct m459 : 17|1@1+ (1,0) [0|1] "" Vector__XXX
 SG_ VCFRONT2_a464_flowIndex m464 : 16|8@1+ (1,0) [0|255] "-" Vector__XXX
 SG_ VCFRONT2_a464_flowIndexFiltered m464 : 24|8@1+ (1,0) [0|255] "-" Vector__XXX
 SG_ VCFRONT2_a464_subcool m464 : 32|7@1+ (0.4,-10) [-10|40.8] "degC" Vector__XXX
 SG_ VCFRONT2_a464_subcoolFiltered m464 : 40|7@1+ (0.4,-10) [-10|40.8] "degC" Vector__XXX
 SG_ VCFRONT2_a465_flowIndex m465 : 16|8@1+ (1,0) [0|255] "-" Vector__XXX
 SG_ VCFRONT2_a465_flowIndexFiltered m465 : 24|8@1+ (1,0) [0|255] "-" Vector__XXX
 SG_ VCFRONT2_a465_subcool m465 : 32|7@1+ (0.4,-10) [-10|40.8] "degC" Vector__XXX
 SG_ VCFRONT2_a465_subcoolFiltered m465 : 40|7@1+ (0.4,-10) [-10|40.8] "degC" Vector__XXX
 SG_ VCFRONT2_a465_flaggedAtSteadySta m465 : 47|1@1+ (1,0) [0|1] "" Vector__XXX
 SG_ VCFRONT2_a465_flaggedAtUnsteadyS m465 : 48|1@1+ (1,0) [0|1] "" Vector__XXX
 SG_ VCFRONT2_a466_flowIndex m466 : 16|8@1+ (1,0) [0|255] "-" Vector__XXX
 SG_ VCFRONT2_a466_flowIndexFiltered m466 : 24|8@1+ (1,0) [0|255] "-" Vector__XXX
 SG_ VCFRONT2_a466_subcool m466 : 32|7@1+ (0.4,-10) [-10|40.8] "degC" Vector__XXX
 SG_ VCFRONT2_a466_subcoolFiltered m466 : 40|7@1+ (0.4,-10) [-10|40.8] "degC" Vector__XXX
 SG_ VCFRONT2_a467_powerIndexFiltered m467 : 16|7@1+ (1,0) [0|127] "-" Vector__XXX
 SG_ VCFRONT2_a470_pressureLiquid m470 : 16|8@1+ (0.2,0) [0|51] "bar" Vector__XXX
 SG_ VCFRONT2_a470_pressureDischarge m470 : 24|8@1+ (0.2,0) [0|51] "bar" Vector__XXX
 SG_ VCFRONT2_a490_coolantPumpType m490 : 16|3@1+ (1,0) [0|7] "" Vector__XXX
 SG_ VCFRONT2_a511_PCSEFuseCurrent m511 : 16|16@1- (0.1,0) [-3276.8|3276.7] "A" Vector__XXX
 SG_ VCFRONT2_a511_DCDCMaxOutputCurre m511 : 32|16@1- (0.1,0) [-3276.8|3276.7] "A" Vector__XXX
 SG_ VCFRONT2_a511_hvState m511 : 48|3@1+ (1,0) [0|7] "" Vector__XXX
 SG_ VCFRONT2_a511_DCDCOutputIsLimite m511 : 51|1@1+ (1,0) [0|1] "" Vector__XXX
 SG_ VCFRONT2_a511_PCSSignalsAreValid m511 : 52|1@1+ (1,0) [0|1] "" Vector__XXX
 SG_ VCFRONT2_a511_factoryGated m511 : 53|1@1+ (1,0) [0|1] "" Vector__XXX
 SG_ VCFRONT2_a511_vehicleIsUpdating m511 : 54|1@1+ (1,0) [0|1] "" Vector__XXX
 SG_ VCFRONT2_a511_serviceMode m511 : 55|1@1+ (1,0) [0|1] "" Vector__XXX
 SG_ VCFRONT2_a511_frunkOpen m511 : 56|1@1+ (1,0) [0|1] "" Vector__XXX
 SG_ VCFRONT2_a531_powerIndexFiltered m531 : 16|7@1+ (1,0) [0|127] "-" Vector__XXX
 SG_ VCFRONT2_a560_highSHCOP1 m560 : 16|1@1+ (1,0) [0|1] "" Vector__XXX
 SG_ VCFRONT2_a560_highSHBattConditio m560 : 17|1@1+ (1,0) [0|1] "" Vector__XXX
 SG_ VCFRONT2_a560_highSHCabinReheatC m560 : 18|1@1+ (1,0) [0|1] "" Vector__XXX
 SG_ VCFRONT2_a560_highSHCabinReheatH m560 : 19|1@1+ (1,0) [0|1] "" Vector__XXX
 SG_ VCFRONT2_a560_highSHCabinCooling m560 : 20|1@1+ (1,0) [0|1] "" Vector__XXX
 SG_ VCFRONT2_a560_highSHCabinHeating m560 : 21|1@1+ (1,0) [0|1] "" Vector__XXX
 SG_ VCFRONT2_a560_highSHCatchAll m560 : 22|1@1+ (1,0) [0|1] "" Vector__XXX
 SG_ VCFRONT2_a615_FRONTIPC_switchSta m615 : 16|1@1+ (1,0) [0|1] "" Vector__XXX
 SG_ VCFRONT2_a616_FRONTIPC_switchSta m616 : 16|1@1+ (1,0) [0|1] "" Vector__XXX
 SG_ VCFRONT2_a667_hcmRegionAndSide m667 : 16|3@1+ (1,0) [1|7] "" Vector__XXX
 SG_ VCFRONT2_a667_country m667 : 24|16@1+ (1,0) [0|65535] "" Vector__XXX
 SG_ VCFRONT2_a667_homologationRegion m667 : 40|2@1+ (1,0) [0|3] "" Vector__XXX
 SG_ VCFRONT2_a667_isRightHandDrive m667 : 42|1@1+ (1,0) [0|1] "" Vector__XXX
 SG_ VCFRONT2_a697_isGlobalHeadlamps m697 : 16|1@1+ (1,0) [0|1] "" Vector__XXX
 SG_ VCFRONT2_a697_isVirtualPitchSens m697 : 17|1@1+ (1,0) [0|1] "" Vector__XXX
 SG_ VCFRONT2_a697_calibratedVertical m697 : 18|10@1+ (1,0) [0|1022] "Steps" Vector__XXX
 SG_ VCFRONT2_a697_calibratedHorizont m697 : 28|10@1+ (1,0) [0|1022] "Steps" Vector__XXX

BO_ 834 VCFRONT2_alertMatrix: 8 VCFRONT2
 SG_ VCFRONT2_matrixIndex M : 0|4@1+ (1,0) [0|15] "" Vector__XXX
 SG_ VCFRONT2_a001_WatchdogReset m0 : 4|1@1+ (1,0) [0|1] "" Vector__XXX
 SG_ VCFRONT2_a002_PowerLossReset m0 : 5|1@1+ (1,0) [0|1] "" Vector__XXX
 SG_ VCFRONT2_a003_SWAssertion m0 : 6|1@1+ (1,0) [0|1] "" Vector__XXX
 SG_ VCFRONT2_a004_adaptiveHeadlights m0 : 7|1@1+ (1,0) [0|1] "" Vector__XXX
 SG_ VCFRONT2_a005_CANTXError m0 : 8|1@1+ (1,0) [0|1] "" Vector__XXX
 SG_ VCFRONT2_a006_CANTX_cyclicError m0 : 9|1@1+ (1,0) [0|1] "" Vector__XXX
 SG_ VCFRONT2_a008_adaptiveHeadlights m0 : 11|1@1+ (1,0) [0|1] "" Vector__XXX
 SG_ VCFRONT2_a009_LCCPurgeAttempted m0 : 12|1@1+ (1,0) [0|1] "" Vector__XXX
 SG_ VCFRONT2_a012_CPUReset m0 : 15|1@1+ (1,0) [0|1] "" Vector__XXX
 SG_ VCFRONT2_a013_AlertManagerFault m0 : 16|1@1+ (1,0) [0|1] "" Vector__XXX
 SG_ VCFRONT2_a015_NVMMError m0 : 18|1@1+ (1,0) [0|1] "" Vector__XXX
 SG_ VCFRONT2_a016_NVMMRecordError m0 : 19|1@1+ (1,0) [0|1] "" Vector__XXX
 SG_ VCFRONT2_a017_NVMMStatusDbg m0 : 20|1@1+ (1,0) [0|1] "" Vector__XXX
 SG_ VCFRONT2_a018_HardFault m0 : 21|1@1+ (1,0) [0|1] "" Vector__XXX
 SG_ VCFRONT2_a019_BusFault m0 : 22|1@1+ (1,0) [0|1] "" Vector__XXX
 SG_ VCFRONT2_a021_TaskSchedulerError m0 : 24|1@1+ (1,0) [0|1] "" Vector__XXX
 SG_ VCFRONT2_a022_TaskInitError m0 : 25|1@1+ (1,0) [0|1] "" Vector__XXX
 SG_ VCFRONT2_a028_UsageFault m0 : 31|1@1+ (1,0) [0|1] "" Vector__XXX
 SG_ VCFRONT2_a029_CoreDump m0 : 32|1@1+ (1,0) [0|1] "" Vector__XXX
 SG_ VCFRONT2_a030_ECULogUploadReques m0 : 33|1@1+ (1,0) [0|1] "" Vector__XXX
 SG_ VCFRONT2_a031_UDSActive m0 : 34|1@1+ (1,0) [0|1] "" Vector__XXX
 SG_ VCFRONT2_a036_UnknownIrq m0 : 39|1@1+ (1,0) [0|1] "" Vector__XXX
 SG_ VCFRONT2_a037_MemManageFault m0 : 40|1@1+ (1,0) [0|1] "" Vector__XXX
 SG_ VCFRONT2_a038_ProtFaultInfo m0 : 41|1@1+ (1,0) [0|1] "" Vector__XXX
 SG_ VCFRONT2_a039_ProtFaultAddress m0 : 42|1@1+ (1,0) [0|1] "" Vector__XXX
 SG_ VCFRONT2_a040_Backtrace m0 : 43|1@1+ (1,0) [0|1] "" Vector__XXX
 SG_ VCFRONT2_a041_HighCPULoad m0 : 44|1@1+ (1,0) [0|1] "" Vector__XXX
 SG_ VCFRONT2_a042_HighStackUsage m0 : 45|1@1+ (1,0) [0|1] "" Vector__XXX
 SG_ VCFRONT2_a043_Task1msError m0 : 46|1@1+ (1,0) [0|1] "" Vector__XXX
 SG_ VCFRONT2_a044_Task10msError m0 : 47|1@1+ (1,0) [0|1] "" Vector__XXX
 SG_ VCFRONT2_a045_Task100msError m0 : 48|1@1+ (1,0) [0|1] "" Vector__XXX
 SG_ VCFRONT2_a046_Task1000msError m0 : 49|1@1+ (1,0) [0|1] "" Vector__XXX
 SG_ VCFRONT2_a053_wiperCommErrorUser m0 : 56|1@1+ (1,0) [0|1] "" Vector__XXX
 SG_ VCFRONT2_a054_compressorLowFlowU m0 : 57|1@1+ (1,0) [0|1] "" Vector__XXX
 SG_ VCFRONT2_a058_inputRHighSyncDebu m0 : 61|1@1+ (1,0) [0|1] "" Vector__XXX
 SG_ VCFRONT2_a059_inputResistanceHig m0 : 62|1@1+ (1,0) [0|1] "" Vector__XXX
 SG_ VCFRONT2_a060_engineeringBuild m0 : 63|1@1+ (1,0) [0|1] "" Vector__XXX
 SG_ VCFRONT2_a061_XCPConnected m1 : 4|1@1+ (1,0) [0|1] "" Vector__XXX
 SG_ VCFRONT2_a062_XCPWasConnected m1 : 5|1@1+ (1,0) [0|1] "" Vector__XXX
 SG_ VCFRONT2_a063_SwitchFault m1 : 6|1@1+ (1,0) [0|1] "" Vector__XXX
 SG_ VCFRONT2_a064_busSleepReqTimeout m1 : 7|1@1+ (1,0) [0|1] "" Vector__XXX
 SG_ VCFRONT2_a077_VCBATT0_MIA m1 : 20|1@1+ (1,0) [0|1] "" Vector__XXX
 SG_ VCFRONT2_a078_VCBATT1_MIA m1 : 21|1@1+ (1,0) [0|1] "" Vector__XXX
 SG_ VCFRONT2_a079_VCBATT2_MIA m1 : 22|1@1+ (1,0) [0|1] "" Vector__XXX
 SG_ VCFRONT2_a080_VCFRONT0_MIA m1 : 23|1@1+ (1,0) [0|1] "" Vector__XXX
 SG_ VCFRONT2_a081_VCFRONT1_MIA m1 : 24|1@1+ (1,0) [0|1] "" Vector__XXX
 SG_ VCFRONT2_a082_VCFRONT2_MIA m1 : 25|1@1+ (1,0) [0|1] "" Vector__XXX
 SG_ VCFRONT2_a086_VCBATT_MIA m1 : 29|1@1+ (1,0) [0|1] "" Vector__XXX
 SG_ VCFRONT2_a090_APS_MIA m1 : 33|1@1+ (1,0) [0|1] "" Vector__XXX
 SG_ VCFRONT2_a091_CMPD_MIA m1 : 34|1@1+ (1,0) [0|1] "" Vector__XXX
 SG_ VCFRONT2_a096_OCS1P_MIA m1 : 39|1@1+ (1,0) [0|1] "" Vector__XXX
 SG_ VCFRONT2_a098_DIR_MIA m1 : 41|1@1+ (1,0) [0|1] "" Vector__XXX
 SG_ VCFRONT2_a100_CANbus_MIA m1 : 43|1@1+ (1,0) [0|1] "" Vector__XXX
 SG_ VCFRONT2_a103_CP_MIA m1 : 46|1@1+ (1,0) [0|1] "" Vector__XXX
 SG_ VCFRONT2_a104_DAS_MIA m1 : 47|1@1+ (1,0) [0|1] "" Vector__XXX
 SG_ VCFRONT2_a105_TAS_MIA m1 : 48|1@1+ (1,0) [0|1] "" Vector__XXX
 SG_ VCFRONT2_a106_PCS_MIA m1 : 49|1@1+ (1,0) [0|1] "" Vector__XXX
 SG_ VCFRONT2_a107_BMS_MIA m1 : 50|1@1+ (1,0) [0|1] "" Vector__XXX
 SG_ VCFRONT2_a108_DIF_MIA m1 : 51|1@1+ (1,0) [0|1] "" Vector__XXX
 SG_ VCFRONT2_a109_RCM_MIA m1 : 52|1@1+ (1,0) [0|1] "" Vector__XXX
 SG_ VCFRONT2_a110_GTW_MIA m1 : 53|1@1+ (1,0) [0|1] "" Vector__XXX
 SG_ VCFRONT2_a111_EPBR_MIA m1 : 54|1@1+ (1,0) [0|1] "" Vector__XXX
 SG_ VCFRONT2_a112_EPBL_MIA m1 : 55|1@1+ (1,0) [0|1] "" Vector__XXX
 SG_ VCFRONT2_a113_UI_MIA m1 : 56|1@1+ (1,0) [0|1] "" Vector__XXX
 SG_ VCFRONT2_a114_ESP_MIA m1 : 57|1@1+ (1,0) [0|1] "" Vector__XXX
 SG_ VCFRONT2_a115_VCSEC_MIA m1 : 58|1@1+ (1,0) [0|1] "" Vector__XXX
 SG_ VCFRONT2_a116_VCRIGHT_MIA m1 : 59|1@1+ (1,0) [0|1] "" Vector__XXX
 SG_ VCFRONT2_a117_VCLEFT_MIA m1 : 60|1@1+ (1,0) [0|1] "" Vector__XXX
 SG_ VCFRONT2_a118_VCFRONT_MIA m1 : 61|1@1+ (1,0) [0|1] "" Vector__XXX
 SG_ VCFRONT2_a119_SCCM_MIA m1 : 62|1@1+ (1,0) [0|1] "" Vector__XXX
 SG_ VCFRONT2_a120_DI_DRIVE_MIA m1 : 63|1@1+ (1,0) [0|1] "" Vector__XXX
 SG_ VCFRONT2_a122_ICR_MIA m2 : 5|1@1+ (1,0) [0|1] "" Vector__XXX
 SG_ VCFRONT2_a123_VC_SECONDARY_LIGHT m2 : 6|1@1+ (1,0) [0|1] "" Vector__XXX
 SG_ VCFRONT2_a124_BB_MIA m2 : 7|1@1+ (1,0) [0|1] "" Vector__XXX
 SG_ VCFRONT2_a125_SCCM_MIA m2 : 8|1@1+ (1,0) [0|1] "" Vector__XXX
 SG_ VCFRONT2_a126_EPAS3P_MIA m2 : 9|1@1+ (1,0) [0|1] "" Vector__XXX
 SG_ VCFRONT2_a131_PCSCOMMON_MIA m2 : 14|1@1+ (1,0) [0|1] "" Vector__XXX
 SG_ VCFRONT2_a133_BRAKE_MIA m2 : 16|1@1+ (1,0) [0|1] "" Vector__XXX
 SG_ VCFRONT2_a135_coolantLevelLow m2 : 18|1@1+ (1,0) [0|1] "" Vector__XXX
 SG_ VCFRONT2_a136_refrigDischTempSns m2 : 19|1@1+ (1,0) [0|1] "" Vector__XXX
 SG_ VCFRONT2_a137_refrigDischPresSns m2 : 20|1@1+ (1,0) [0|1] "" Vector__XXX
 SG_ VCFRONT2_a138_refrigSuctTempSns m2 : 21|1@1+ (1,0) [0|1] "" Vector__XXX
 SG_ VCFRONT2_a139_refrigSuctPresSns m2 : 22|1@1+ (1,0) [0|1] "" Vector__XXX
 SG_ VCFRONT2_a140_coolantTempPtSns m2 : 23|1@1+ (1,0) [0|1] "" Vector__XXX
 SG_ VCFRONT2_a141_coolantTempBatSns m2 : 24|1@1+ (1,0) [0|1] "" Vector__XXX
 SG_ VCFRONT2_a142_exvMotorFault m2 : 25|1@1+ (1,0) [0|1] "" Vector__XXX
 SG_ VCFRONT2_a143_powerLossDuringSle m2 : 26|1@1+ (1,0) [0|1] "" Vector__XXX
 SG_ VCFRONT2_a144_EPAS3S_MIA m2 : 27|1@1+ (1,0) [0|1] "" Vector__XXX
 SG_ VCFRONT2_a150_pumpBatLowRPMCBang m2 : 33|1@1+ (1,0) [0|1] "" Vector__XXX
 SG_ VCFRONT2_a153_userPresenceDispla m2 : 36|1@1+ (1,0) [0|1] "" Vector__XXX
 SG_ VCFRONT2_a155_autopilotDriveNotA m2 : 38|1@1+ (1,0) [0|1] "" Vector__XXX
 SG_ VCFRONT2_a159_coolantValveFault m2 : 42|1@1+ (1,0) [0|1] "" Vector__XXX
 SG_ VCFRONT2_a160_compressorInhibite m2 : 43|1@1+ (1,0) [0|1] "" Vector__XXX
 SG_ VCFRONT2_a161_compressorSelfFaul m2 : 44|1@1+ (1,0) [0|1] "" Vector__XXX
 SG_ VCFRONT2_a162_compressorInhibite m2 : 45|1@1+ (1,0) [0|1] "" Vector__XXX
 SG_ VCFRONT2_a163_compressorDisabled m2 : 46|1@1+ (1,0) [0|1] "" Vector__XXX
 SG_ VCFRONT2_a167_leftHCMMIA m2 : 50|1@1+ (1,0) [0|1] "" Vector__XXX
 SG_ VCFRONT2_a171_driveBlckdByMsmtch m2 : 54|1@1+ (1,0) [0|1] "" Vector__XXX
 SG_ VCFRONT2_a172_wsteHtBlckdByMsmtc m2 : 55|1@1+ (1,0) [0|1] "" Vector__XXX
 SG_ VCFRONT2_a173_HVBlckdByMsmtch m2 : 56|1@1+ (1,0) [0|1] "" Vector__XXX
 SG_ VCFRONT2_a174_driveNotAuthed m2 : 57|1@1+ (1,0) [0|1] "" Vector__XXX
 SG_ VCFRONT2_a176_vehicleInSelfTest m2 : 59|1@1+ (1,0) [0|1] "" Vector__XXX
 SG_ VCFRONT2_a178_compLiquidPumpOut m2 : 61|1@1+ (1,0) [0|1] "" Vector__XXX
 SG_ VCFRONT2_a184_cabinCoolingPerfor m3 : 7|1@1+ (1,0) [0|1] "" Vector__XXX
 SG_ VCFRONT2_a186_noDriveChgCableCon m3 : 9|1@1+ (1,0) [0|1] "" Vector__XXX
 SG_ VCFRONT2_a187_busesNotSleeping m3 : 10|1@1+ (1,0) [0|1] "" Vector__XXX
 SG_ VCFRONT2_a188_sleepFailed m3 : 11|1@1+ (1,0) [0|1] "" Vector__XXX
 SG_ VCFRONT2_a195_drveBlckdVltgeTooH m3 : 18|1@1+ (1,0) [0|1] "" Vector__XXX
 SG_ VCFRONT2_a210_coolantValveCalib m3 : 33|1@1+ (1,0) [0|1] "" Vector__XXX
 SG_ VCFRONT2_a214_ptPumpCompromised m3 : 37|1@1+ (1,0) [0|1] "" Vector__XXX
 SG_ VCFRONT2_a215_ptPumpMIA m3 : 38|1@1+ (1,0) [0|1] "" Vector__XXX
 SG_ VCFRONT2_a217_battPumpCompromise m3 : 40|1@1+ (1,0) [0|1] "" Vector__XXX
 SG_ VCFRONT2_a218_socMonitorDetected m3 : 41|1@1+ (1,0) [0|1] "" Vector__XXX
 SG_ VCFRONT2_a225_driveBlckdByShowro m3 : 48|1@1+ (1,0) [0|1] "" Vector__XXX
 SG_ VCFRONT2_a226_battPumpMIA m3 : 49|1@1+ (1,0) [0|1] "" Vector__XXX
 SG_ VCFRONT2_a232_lowSideControllerH m3 : 55|1@1+ (1,0) [0|1] "" Vector__XXX
 SG_ VCFRONT2_a235_ptTempSnsIrrationa m3 : 58|1@1+ (1,0) [0|1] "" Vector__XXX
 SG_ VCFRONT2_a236_batTempSnsIrration m3 : 59|1@1+ (1,0) [0|1] "" Vector__XXX
 SG_ VCFRONT2_a240_lowSideCompromised m3 : 63|1@1+ (1,0) [0|1] "" Vector__XXX
 SG_ VCFRONT2_a247_evapSolenoidFault m4 : 10|1@1+ (1,0) [0|1] "" Vector__XXX
 SG_ VCFRONT2_a249_coolantValveBadMod m4 : 12|1@1+ (1,0) [0|1] "" Vector__XXX
 SG_ VCFRONT2_a250_headlampsNotAimed m4 : 13|1@1+ (1,0) [0|1] "" Vector__XXX
 SG_ VCFRONT2_a251_UIWakeupTrigger m4 : 14|1@1+ (1,0) [0|1] "" Vector__XXX
 SG_ VCFRONT2_a254_pumpBatStopped m4 : 17|1@1+ (1,0) [0|1] "" Vector__XXX
 SG_ VCFRONT2_a273_wiperFrictionModel m4 : 36|1@1+ (1,0) [0|1] "" Vector__XXX
 SG_ VCFRONT2_a279_refrigLiquidTempSn m4 : 42|1@1+ (1,0) [0|1] "" Vector__XXX
 SG_ VCFRONT2_a280_refrigLiquidPresSn m4 : 43|1@1+ (1,0) [0|1] "" Vector__XXX
 SG_ VCFRONT2_a281_alcoholInterlockBl m4 : 44|1@1+ (1,0) [0|1] "" Vector__XXX
 SG_ VCFRONT2_a282_coolantLevelSensor m4 : 45|1@1+ (1,0) [0|1] "" Vector__XXX
 SG_ VCFRONT2_a283_thmlFanLimitedByCu m4 : 46|1@1+ (1,0) [0|1] "" Vector__XXX
 SG_ VCFRONT2_a284_chillerExvFault m4 : 47|1@1+ (1,0) [0|1] "" Vector__XXX
 SG_ VCFRONT2_a285_evaporatorExvFault m4 : 48|1@1+ (1,0) [0|1] "" Vector__XXX
 SG_ VCFRONT2_a286_recircExvFault m4 : 49|1@1+ (1,0) [0|1] "" Vector__XXX
 SG_ VCFRONT2_a287_lccExvFault m4 : 50|1@1+ (1,0) [0|1] "" Vector__XXX
 SG_ VCFRONT2_a288_ccLeftExvFault m4 : 51|1@1+ (1,0) [0|1] "" Vector__XXX
 SG_ VCFRONT2_a289_ccRightExvFault m4 : 52|1@1+ (1,0) [0|1] "" Vector__XXX
 SG_ VCFRONT2_a294_leftSideRepeaterLi m4 : 57|1@1+ (1,0) [0|1] "" Vector__XXX
 SG_ VCFRONT2_a298_radiatorLowAirFlow m4 : 61|1@1+ (1,0) [0|1] "" Vector__XXX
 SG_ VCFRONT2_a301_wipersFactoryDisab m5 : 4|1@1+ (1,0) [0|1] "" Vector__XXX
 SG_ VCFRONT2_a302_wiperCommError m5 : 5|1@1+ (1,0) [0|1] "" Vector__XXX
 SG_ VCFRONT2_a355_coolantSysLockout m5 : 58|1@1+ (1,0) [0|1] "" Vector__XXX
 SG_ VCFRONT2_a356_refrigSysLockout m5 : 59|1@1+ (1,0) [0|1] "" Vector__XXX
 SG_ VCFRONT2_a360_ungracefulAccPlusE m5 : 63|1@1+ (1,0) [0|1] "" Vector__XXX
 SG_ VCFRONT2_a365_burnInRoutineEnter m6 : 8|1@1+ (1,0) [0|1] "" Vector__XXX
 SG_ VCFRONT2_a366_burnInRoutineExite m6 : 9|1@1+ (1,0) [0|1] "" Vector__XXX
 SG_ VCFRONT2_a367_dischargeRoutineEn m6 : 10|1@1+ (1,0) [0|1] "" Vector__XXX
 SG_ VCFRONT2_a368_dischargeRoutineEx m6 : 11|1@1+ (1,0) [0|1] "" Vector__XXX
 SG_ VCFRONT2_a369_reducedPowerDischa m6 : 12|1@1+ (1,0) [0|1] "" Vector__XXX
 SG_ VCFRONT2_a374_lccInletSolenoidFa m6 : 17|1@1+ (1,0) [0|1] "" Vector__XXX
 SG_ VCFRONT2_a377_wiperParkFault m6 : 20|1@1+ (1,0) [0|1] "" Vector__XXX
 SG_ VCFRONT2_a378_wiperECUDebug m6 : 21|1@1+ (1,0) [0|1] "" Vector__XXX
 SG_ VCFRONT2_a380_chillerExvWarning m6 : 23|1@1+ (1,0) [0|1] "" Vector__XXX
 SG_ VCFRONT2_a381_evaporatorExvWarni m6 : 24|1@1+ (1,0) [0|1] "" Vector__XXX
 SG_ VCFRONT2_a382_recircExvWarning m6 : 25|1@1+ (1,0) [0|1] "" Vector__XXX
 SG_ VCFRONT2_a383_lccExvWarning m6 : 26|1@1+ (1,0) [0|1] "" Vector__XXX
 SG_ VCFRONT2_a384_ccLeftExvWarning m6 : 27|1@1+ (1,0) [0|1] "" Vector__XXX
 SG_ VCFRONT2_a385_ccRightExvWarning m6 : 28|1@1+ (1,0) [0|1] "" Vector__XXX
 SG_ VCFRONT2_a386_exvMotorWarning m6 : 29|1@1+ (1,0) [0|1] "" Vector__XXX
 SG_ VCFRONT2_a393_ambientTempNetwork m6 : 36|1@1+ (1,0) [0|1] "" Vector__XXX
 SG_ VCFRONT2_a394_pressureSensorChec m6 : 37|1@1+ (1,0) [0|1] "" Vector__XXX
 SG_ VCFRONT2_a395_pressureSensorChec m6 : 38|1@1+ (1,0) [0|1] "" Vector__XXX
 SG_ VCFRONT2_a396_coolantLevelLowUse m6 : 39|1@1+ (1,0) [0|1] "" Vector__XXX
 SG_ VCFRONT2_a397_temperatureSensorC m6 : 40|1@1+ (1,0) [0|1] "" Vector__XXX
 SG_ VCFRONT2_a398_tempSensorCheckInc m6 : 41|1@1+ (1,0) [0|1] "" Vector__XXX
 SG_ VCFRONT2_a409_invalidConfigurati m6 : 52|1@1+ (1,0) [0|1] "" Vector__XXX
 SG_ VCFRONT2_a420_holidayParty m6 : 63|1@1+ (1,0) [0|1] "" Vector__XXX
 SG_ VCFRONT2_a421_leftHeadlampUartCo m7 : 4|1@1+ (1,0) [0|1] "" Vector__XXX
 SG_ VCFRONT2_a423_rtosSleepFailed m7 : 6|1@1+ (1,0) [0|1] "" Vector__XXX
 SG_ VCFRONT2_a446_cabinHVACUnavailab m7 : 29|1@1+ (1,0) [0|1] "" Vector__XXX
 SG_ VCFRONT2_a447_cabinHVACUnavailab m7 : 30|1@1+ (1,0) [0|1] "" Vector__XXX
 SG_ VCFRONT2_a451_refrigerantNotComm m7 : 34|1@1+ (1,0) [0|1] "" Vector__XXX
 SG_ VCFRONT2_a452_dischargePresSensI m7 : 35|1@1+ (1,0) [0|1] "" Vector__XXX
 SG_ VCFRONT2_a453_dischargeTempSensI m7 : 36|1@1+ (1,0) [0|1] "" Vector__XXX
 SG_ VCFRONT2_a454_suctionPresSensInt m7 : 37|1@1+ (1,0) [0|1] "" Vector__XXX
 SG_ VCFRONT2_a455_suctionTempSensInt m7 : 38|1@1+ (1,0) [0|1] "" Vector__XXX
 SG_ VCFRONT2_a456_liquidPresSensInte m7 : 39|1@1+ (1,0) [0|1] "" Vector__XXX
 SG_ VCFRONT2_a457_liquidTempSensInte m7 : 40|1@1+ (1,0) [0|1] "" Vector__XXX
 SG_ VCFRONT2_a458_grosslyLowRefriger m7 : 41|1@1+ (1,0) [0|1] "" Vector__XXX
 SG_ VCFRONT2_a459_thermalFillAndDriv m7 : 42|1@1+ (1,0) [0|1] "" Vector__XXX
 SG_ VCFRONT2_a460_hardIsentropicTdFa m7 : 43|1@1+ (1,0) [0|1] "" Vector__XXX
 SG_ VCFRONT2_a464_highFlowIndexHighS m7 : 47|1@1+ (1,0) [0|1] "" Vector__XXX
 SG_ VCFRONT2_a465_lowFlowIndexHighSu m7 : 48|1@1+ (1,0) [0|1] "" Vector__XXX
 SG_ VCFRONT2_a466_highFlowIndexLowSu m7 : 49|1@1+ (1,0) [0|1] "" Vector__XXX
 SG_ VCFRONT2_a467_lowPowerIndexFlagg m7 : 50|1@1+ (1,0) [0|1] "" Vector__XXX
 SG_ VCFRONT2_a468_highPowerIndexFlag m7 : 51|1@1+ (1,0) [0|1] "" Vector__XXX
 SG_ VCFRONT2_a469_prvPopDetected m7 : 52|1@1+ (1,0) [0|1] "" Vector__XXX
 SG_ VCFRONT2_a470_implausiblePdPlDet m7 : 53|1@1+ (1,0) [0|1] "" Vector__XXX
 SG_ VCFRONT2_a471_hcm5Debug m7 : 54|1@1+ (1,0) [0|1] "" Vector__XXX
 SG_ VCFRONT2_a474_leftHeadlampIntern m7 : 57|1@1+ (1,0) [0|1] "" Vector__XXX
 SG_ VCFRONT2_a489_ValveStuckFlagged m8 : 12|1@1+ (1,0) [0|1] "" Vector__XXX
 SG_ VCFRONT2_a490_coolantPumpsNotIde m8 : 13|1@1+ (1,0) [0|1] "" Vector__XXX
 SG_ VCFRONT2_a499_loadShedPumpFlowRe m8 : 22|1@1+ (1,0) [0|1] "" Vector__XXX
 SG_ VCFRONT2_a504_airInRefrigerantDe m8 : 27|1@1+ (1,0) [0|1] "" Vector__XXX
 SG_ VCFRONT2_a506_invalidRefrigerant m8 : 29|1@1+ (1,0) [0|1] "" Vector__XXX
 SG_ VCFRONT2_a507_leftHeadlampAiming m8 : 30|1@1+ (1,0) [0|1] "" Vector__XXX
 SG_ VCFRONT2_a511_DCDCSaturationLoad m8 : 34|1@1+ (1,0) [0|1] "" Vector__XXX
 SG_ VCFRONT2_a519_leftHeadlampIntern m8 : 42|1@1+ (1,0) [0|1] "" Vector__XXX
 SG_ VCFRONT2_a531_lowPowerIndexFlagg m8 : 54|1@1+ (1,0) [0|1] "" Vector__XXX
 SG_ VCFRONT2_a534_chillerExvCalibIni m8 : 57|1@1+ (1,0) [0|1] "" Vector__XXX
 SG_ VCFRONT2_a535_evapExvCalibInitDe m8 : 58|1@1+ (1,0) [0|1] "" Vector__XXX
 SG_ VCFRONT2_a536_recircExvCalibInit m8 : 59|1@1+ (1,0) [0|1] "" Vector__XXX
 SG_ VCFRONT2_a537_lccExvCalibInitDeb m8 : 60|1@1+ (1,0) [0|1] "" Vector__XXX
 SG_ VCFRONT2_a538_cclExvCalibInitDeb m8 : 61|1@1+ (1,0) [0|1] "" Vector__XXX
 SG_ VCFRONT2_a539_ccrExvCalibInitDeb m8 : 62|1@1+ (1,0) [0|1] "" Vector__XXX
 SG_ VCFRONT2_a540_radiatorSteamDetec m8 : 63|1@1+ (1,0) [0|1] "" Vector__XXX
 SG_ VCFRONT2_a542_refrigerantReclaim m9 : 5|1@1+ (1,0) [0|1] "" Vector__XXX
 SG_ VCFRONT2_a543_compressorLowFlowD m9 : 6|1@1+ (1,0) [0|1] "" Vector__XXX
 SG_ VCFRONT2_a546_leftLowOrHighBeamL m9 : 9|1@1+ (1,0) [0|1] "" Vector__XXX
 SG_ VCFRONT2_a549_leftHeadlampIntern m9 : 12|1@1+ (1,0) [0|1] "" Vector__XXX
 SG_ VCFRONT2_a560_compressorHighSupe m9 : 23|1@1+ (1,0) [0|1] "" Vector__XXX
 SG_ VCFRONT2_a563_chargePortDoorOpen m9 : 26|1@1+ (1,0) [0|1] "" Vector__XXX
 SG_ VCFRONT2_a564_leftHeadlampAiming m9 : 27|1@1+ (1,0) [0|1] "" Vector__XXX
 SG_ VCFRONT2_a565_userPresenceDispla m9 : 28|1@1+ (1,0) [0|1] "" Vector__XXX
 SG_ VCFRONT2_a566_leftFrontTurnLight m9 : 29|1@1+ (1,0) [0|1] "" Vector__XXX
 SG_ VCFRONT2_a568_leftDaytimeRunning m9 : 31|1@1+ (1,0) [0|1] "" Vector__XXX
 SG_ VCFRONT2_a570_headlampsAdaptedTo m9 : 33|1@1+ (1,0) [0|1] "" Vector__XXX
 SG_ VCFRONT2_a571_headlampsAdaptedTo m9 : 34|1@1+ (1,0) [0|1] "" Vector__XXX
 SG_ VCFRONT2_a572_hvacCompressorEFus m9 : 35|1@1+ (1,0) [0|1] "" Vector__XXX
 SG_ VCFRONT2_a578_vbusFusedLowCurren m9 : 41|1@1+ (1,0) [0|1] "" Vector__XXX
 SG_ VCFRONT2_a585_bothHeadlampsInter m9 : 48|1@1+ (1,0) [0|1] "" Vector__XXX
 SG_ VCFRONT2_a601_autopilotAirPurgeL m10 : 4|1@1+ (1,0) [0|1] "" Vector__XXX
 SG_ VCFRONT2_a602_unknownTurnIndicat m10 : 5|1@1+ (1,0) [0|1] "" Vector__XXX
 SG_ VCFRONT2_a603_unexpectedTurnIndi m10 : 6|1@1+ (1,0) [0|1] "" Vector__XXX
 SG_ VCFRONT2_a604_turnIndicatorConfi m10 : 7|1@1+ (1,0) [0|1] "" Vector__XXX
 SG_ VCFRONT2_a606_chillerBattHeating m10 : 9|1@1+ (1,0) [0|1] "" Vector__XXX
 SG_ VCFRONT2_a610_driveEntryDelayed m10 : 13|1@1+ (1,0) [0|1] "" Vector__XXX
 SG_ VCFRONT2_a611_poorRadiatorHeatRe m10 : 14|1@1+ (1,0) [0|1] "" Vector__XXX
 SG_ VCFRONT2_a612_selfTestsBlockingD m10 : 15|1@1+ (1,0) [0|1] "" Vector__XXX
 SG_ VCFRONT2_a614_coolantSysDriverle m10 : 17|1@1+ (1,0) [0|1] "" Vector__XXX
 SG_ VCFRONT2_a615_VCSEAT2L_MIA m10 : 18|1@1+ (1,0) [0|1] "" Vector__XXX
 SG_ VCFRONT2_a616_VCSEAT2R_MIA m10 : 19|1@1+ (1,0) [0|1] "" Vector__XXX
 SG_ VCFRONT2_a617_APP_MIA m10 : 20|1@1+ (1,0) [0|1] "" Vector__XXX
 SG_ VCFRONT2_a618_cabinCoolingCapaci m10 : 21|1@1+ (1,0) [0|1] "" Vector__XXX
 SG_ VCFRONT2_a620_pumpAirLock m10 : 23|1@1+ (1,0) [0|1] "" Vector__XXX
 SG_ VCFRONT2_a621_coolantAirPurgeInc m10 : 24|1@1+ (1,0) [0|1] "" Vector__XXX
 SG_ VCFRONT2_a622_pumpDetectsLowCool m10 : 25|1@1+ (1,0) [0|1] "" Vector__XXX
 SG_ VCFRONT2_a625_leftHeadlampIntern m10 : 28|1@1+ (1,0) [0|1] "" Vector__XXX
 SG_ VCFRONT2_a630_leftHeadlampFactor m10 : 33|1@1+ (1,0) [0|1] "" Vector__XXX
 SG_ VCFRONT2_d636_ptCoolantPumpDetec m10 : 39|1@1+ (1,0) [0|1] "" Vector__XXX
 SG_ VCFRONT2_d637_battCoolantPumpDet m10 : 40|1@1+ (1,0) [0|1] "" Vector__XXX
 SG_ VCFRONT2_d638_ptCoolantTempSenso m10 : 41|1@1+ (1,0) [0|1] "" Vector__XXX
 SG_ VCFRONT2_d639_batteryCoolantTemp m10 : 42|1@1+ (1,0) [0|1] "" Vector__XXX
 SG_ VCFRONT2_d640_firmwareVersionMis m10 : 43|1@1+ (1,0) [0|1] "" Vector__XXX
 SG_ VCFRONT2_d641_ptCoolantPumpCircu m10 : 44|1@1+ (1,0) [0|1] "" Vector__XXX
 SG_ VCFRONT2_d642_batteryCoolantPump m10 : 45|1@1+ (1,0) [0|1] "" Vector__XXX
 SG_ VCFRONT2_d647_louverCommLost m10 : 50|1@1+ (1,0) [0|1] "" Vector__XXX
 SG_ VCFRONT2_d648_louverBlocked m10 : 51|1@1+ (1,0) [0|1] "" Vector__XXX
 SG_ VCFRONT2_d650_lowCoolantLevel m10 : 53|1@1+ (1,0) [0|1] "" Vector__XXX
 SG_ VCFRONT2_d651_ptCoolantPumpStall m10 : 54|1@1+ (1,0) [0|1] "" Vector__XXX
 SG_ VCFRONT2_d652_ptCoolantPumpCircu m10 : 55|1@1+ (1,0) [0|1] "" Vector__XXX
 SG_ VCFRONT2_d653_ptCoolantPumpCommL m10 : 56|1@1+ (1,0) [0|1] "" Vector__XXX
 SG_ VCFRONT2_d654_batteryCoolantPump m10 : 57|1@1+ (1,0) [0|1] "" Vector__XXX
 SG_ VCFRONT2_d655_batteryCoolantPump m10 : 58|1@1+ (1,0) [0|1] "" Vector__XXX
 SG_ VCFRONT2_d656_batteryCoolantPump m10 : 59|1@1+ (1,0) [0|1] "" Vector__XXX
 SG_ VCFRONT2_d657_radiatorFanOperati m10 : 60|1@1+ (1,0) [0|1] "" Vector__XXX
 SG_ VCFRONT2_d658_radiatorFanCircuit m10 : 61|1@1+ (1,0) [0|1] "" Vector__XXX
 SG_ VCFRONT2_d659_radiatorFanCommLos m10 : 62|1@1+ (1,0) [0|1] "" Vector__XXX
 SG_ VCFRONT2_d660_coolantValveCircui m10 : 63|1@1+ (1,0) [0|1] "" Vector__XXX
 SG_ VCFRONT2_a661_mculessLeftHeadlam m11 : 4|1@1+ (1,0) [0|1] "" Vector__XXX
 SG_ VCFRONT2_a662_driveExitBlockedIn m11 : 5|1@1+ (1,0) [0|1] "" Vector__XXX
 SG_ VCFRONT2_a663_leftHeadlampUartWa m11 : 6|1@1+ (1,0) [0|1] "" Vector__XXX
 SG_ VCFRONT2_a665_leftHeadlampRetryI m11 : 8|1@1+ (1,0) [0|1] "" Vector__XXX
 SG_ VCFRONT2_a667_leftHeadlampRegion m11 : 10|1@1+ (1,0) [0|1] "" Vector__XXX
 SG_ VCFRONT2_a669_thermalHVPowerBudg m11 : 12|1@1+ (1,0) [0|1] "" Vector__XXX
 SG_ VCFRONT2_a697_leftHeadlampNotAim m11 : 40|1@1+ (1,0) [0|1] "" Vector__XXX
 SG_ VCFRONT2_a702_dynamicHeadlightLe m11 : 45|1@1+ (1,0) [0|1] "" Vector__XXX

BO_ 1583 VCFRONT2_udsResponse: 8 VCFRONT2
 SG_ VCFRONT2_udsResponseData : 7|64@0+ (1,0) [0|1.84467440737e+19] "" Vector__XXX

BO_ 609 VCFRONT_12VBatteryStatus: 8 VCFRONT
 SG_ VCFRONT_12VBatteryStatusIndex M : 0|3@1+ (1,0) [0|7] "" Vector__XXX
 SG_ VCFRONT_good12VforUpdate : 46|1@1+ (1,0) [0|1] "" Vector__XXX
 SG_ VCFRONT_LVLoadRequest : 47|1@1+ (1,0) [0|1] "" Vector__XXX
 SG_ VCFRONT_12VBatteryStatusCounter : 52|4@1+ (1,0) [0|15] "" Vector__XXX
 SG_ VCFRONT_12VBatteryStatusChecksum : 56|8@1+ (1,0) [0|255] "" Vector__XXX
 SG_ VCFRONT_batterySupportRequest m1 : 3|1@1+ (1,0) [0|1] "" Vector__XXX
 SG_ VCFRONT_batterySMState m1 : 4|4@1+ (1,0) [0|15] "" Vector__XXX
 SG_ VCFRONT_eFuseRecoveryStateDBG m1 : 8|3@1+ (1,0) [0|7] "" Vector__XXX
 SG_ VCFRONT_batteryLINScheduleDBG m1 : 11|3@1+ (1,0) [0|6] "" Vector__XXX
 SG_ VCFRONT_resistanceEstimationTest m1 : 14|2@1+ (1,0) [0|3] "" Vector__XXX
 SG_ VCFRONT_IBSCurrent m1 : 16|16@1- (0.005,0) [-163.84|163.835] "A" Vector__XXX
 SG_ VCFRONT_IBSVoltage m1 : 32|14@1+ (0.005443676,0) [0|65.535] "V" Vector__XXX
 SG_ VCFRONT_reverseBatteryFault m1 : 48|1@1+ (1,0) [0|1] "" Vector__XXX
 SG_ VCFRONT_LVBatterySupported m1 : 49|1@1+ (1,0) [0|1] "" Vector__XXX
 SG_ VCFRONT_LVBatteryCannotSupportVe m1 : 50|1@1+ (1,0) [0|1] "" Vector__XXX
 SG_ VCFRONT_goodTemp12VforUpdate m1 : 51|1@1+ (1,0) [0|1] "" Vector__XXX
 SG_ VCFRONT_12VBatteryTargetVoltage m2 : 3|13@1+ (0.01,0) [0|65.535] "V" Vector__XXX
 SG_ VCFRONT_IBSTemperature m2 : 16|11@1+ (0.1,-24) [-24|124] "degC" Vector__XXX
 SG_ VCFRONT_currentSensorMismatchLea m2 : 27|7@1+ (2,0) [0|254] "PCT" Vector__XXX
 SG_ VCFRONT_LVBatteryEnergyRemaining m2 : 37|7@1+ (1,0) [0|127] "%" Vector__XXX
 SG_ VCFRONT_LVBatteryStatusForDrive m2 : 44|2@1+ (1,0) [0|3] "" Vector__XXX
 SG_ VCFRONT_LVBatteryType m2 : 48|3@1+ (1,0) [0|7] "" Vector__XXX
 SG_ VCFRONT_resistanceEstimationNeed m2 : 51|1@1+ (1,0) [0|1] "" Vector__XXX
 SG_ VCFRONT_IBSVoltageFiltered m3 : 3|14@1+ (0.005443676,0) [0|65.535] "V" Vector__XXX
 SG_ VCFRONT_LVBMS_LVBusVoltageSource m3 : 17|2@1+ (1,0) [0|3] "" Vector__XXX
 SG_ VCFRONT_LVBMS_LVPackCurrentSourc m3 : 19|2@1+ (1,0) [0|3] "" Vector__XXX
 SG_ VCFRONT_LVBatterySupportRqrdTrig m3 : 24|14@1+ (1,0) [0|16383] "" Vector__XXX
 SG_ VCFRONT_goodForPCSPowerCycleLeak m3 : 40|5@1+ (0.0005,0) [0|0.0155] "Ah" Vector__XXX
 SG_ VCFRONT_LVBusControlsFutile m3 : 45|1@1+ (1,0) [0|1] "" Vector__XXX
 SG_ VCFRONT_resistanceEstimatio_0001 m3 : 48|1@1+ (1,0) [0|1] "" Vector__XXX
 SG_ VCFRONT_resistanceEstimatio_0002 m3 : 49|1@1+ (1,0) [0|1] "" Vector__XXX
 SG_ VCFRONT_goodLVChargeForUpdate m3 : 50|1@1+ (1,0) [0|1] "" Vector__XXX
 SG_ VCFRONT_opportunisticDCRTestNeed m3 : 51|1@1+ (1,0) [0|1] "" Vector__XXX
 SG_ VCFRONT_voltageProfile m4 : 3|2@1+ (1,0) [0|3] "" Vector__XXX
 SG_ VCFRONT_IBSAmpHours m4 : 5|14@1- (0.005,0) [-40.96|40.955] "Ah" Vector__XXX
 SG_ VCFRONT_IBSVoltageRawDBG m4 : 19|14@1+ (0.005443676,0) [0|65.535] "V" Vector__XXX
 SG_ VCFRONT_LVBatteryLINCommsDetecte m4 : 33|1@1+ (1,0) [0|1] "" Vector__XXX
 SG_ VCFRONT_voltageSensorMismatchLea m4 : 34|7@1+ (2,0) [0|254] "PCT" Vector__XXX
 SG_ VCFRONT_LVBusControlMode m4 : 41|4@1+ (1,0) [0|15] "" Vector__XXX
 SG_ VCFRONT_resistanceEstimationExte m4 : 45|1@1+ (1,0) [0|1] "" Vector__XXX
 SG_ VCFRONT_LVBatteryFctryLimOverrid m4 : 50|1@1+ (1,0) [0|1] "" Vector__XXX
 SG_ VCFRONT_LVBatterySPICommsDetecte m4 : 51|1@1+ (1,0) [0|1] "" Vector__XXX
 SG_ VCFRONT_targetCurrent m5 : 3|11@1+ (0.125,-127) [0|120] "A" Vector__XXX
 SG_ VCFRONT_PCSMia m5 : 14|1@1+ (1,0) [0|1] "" Vector__XXX
 SG_ VCFRONT_chargeNeeded m5 : 15|1@1+ (1,0) [0|1] "" Vector__XXX
 SG_ VCFRONT_voltageControlLoopIntegr m5 : 16|14@1+ (0.006,0) [0|65.535] "V" Vector__XXX
 SG_ VCFRONT_currentControlLoopIntegr m5 : 30|14@1+ (0.006,0) [0|65.535] "V" Vector__XXX

BO_ 1847 VCFRONT_LVBMS_info: 7 VCFRONT
 SG_ VCFRONT_LVBMS_InfoIndex M : 0|8@1+ (1,0) [0|255] "" Vector__XXX
 SG_ VCFRONT_LVBMS_PcbaId m0 : 8|16@1+ (1,0) [0|65535] "" Vector__XXX
 SG_ VCFRONT_LVBMS_AssemblyId m0 : 24|16@1+ (1,0) [0|65535] "" Vector__XXX
 SG_ VCFRONT_LVBMS_SubUsageId m0 : 40|16@1+ (1,0) [0|65534] "" Vector__XXX
 SG_ VCFRONT_LVBMS_UsageId m1 : 8|16@1+ (1,0) [0|65535] "" Vector__XXX
 SG_ VCFRONT_LVBMS_AppCRC m1 : 24|32@1+ (1,0) [0|4294967295] "" Vector__XXX
 SG_ VCFRONT_LVBMS_FWBuildType m3 : 8|8@1+ (1,0) [0|255] "" Vector__XXX

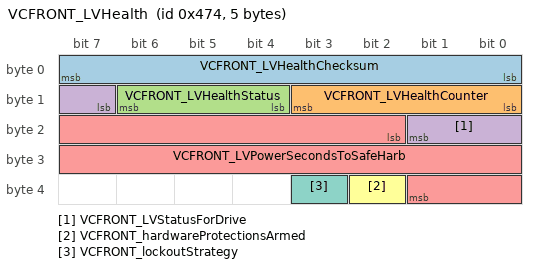
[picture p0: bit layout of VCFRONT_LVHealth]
BO_ 1140 VCFRONT_LVHealth: 5 VCFRONT
 SG_ VCFRONT_LVHealthChecksum : 0|8@1+ (1,0) [0|255] "" Vector__XXX
 SG_ VCFRONT_LVHealthCounter : 8|4@1+ (1,0) [0|15] "" Vector__XXX
 SG_ VCFRONT_LVHealthStatus : 12|3@1+ (1,0) [0|7] "" Vector__XXX
 SG_ VCFRONT_LVStatusForDrive : 15|3@1+ (1,0) [0|7] "" Vector__XXX
 SG_ VCFRONT_LVPowerSecondsToSafeHarb : 18|16@1+ (1,0) [0|65535] "" Vector__XXX
 SG_ VCFRONT_hardwareProtectionsArmed : 34|1@1+ (1,0) [0|1] "" Vector__XXX
 SG_ VCFRONT_lockoutStrategy : 35|1@1+ (1,0) [0|1] "" Vector__XXX

BO_ 1173 VCFRONT_LVHealthDebug: 6 VCFRONT
 SG_ VCFRONT_LVHealthDebugIndex M : 0|4@1+ (1,0) [0|15] "" Vector__XXX
 SG_ VCFRONT_LVHEALTH_placeholder m0 : 8|1@1+ (1,0) [0|1] "" Vector__XXX
 SG_ VCFRONT_LVHEALTH_activeDecelEner m0 : 9|1@1+ (1,0) [0|1] "" Vector__XXX
 SG_ VCFRONT_LVHEALTH_criticalPullove m0 : 10|1@1+ (1,0) [0|1] "" Vector__XXX
 SG_ VCFRONT_LVHEALTH_revBattEFuseOff m0 : 11|1@1+ (1,0) [0|1] "" Vector__XXX
 SG_ VCFRONT_LVHEALTH_LVBMBEFuseOpen m0 : 12|1@1+ (1,0) [0|1] "" Vector__XXX
 SG_ VCFRONT_LVHEALTH_lvBatteryCommsM m0 : 13|1@1+ (1,0) [0|1] "" Vector__XXX
 SG_ VCFRONT_LVHEALTH_pcsEFuseOff m0 : 14|1@1+ (1,0) [0|1] "" Vector__XXX
 SG_ VCFRONT_LVHEALTH_pcsNotActive m0 : 15|1@1+ (1,0) [0|1] "" Vector__XXX
 SG_ VCFRONT_LVHEALTH_pcsMIA m0 : 16|1@1+ (1,0) [0|1] "" Vector__XXX
 SG_ VCFRONT_LVHEALTH_IBSMIA m0 : 17|1@1+ (1,0) [0|1] "" Vector__XXX
 SG_ VCFRONT_LVHEALTH_LVBatteryElecDi m0 : 18|1@1+ (1,0) [0|1] "" Vector__XXX
 SG_ VCFRONT_LVHEALTH_LVBatteryE_0001 m0 : 19|1@1+ (1,0) [0|1] "" Vector__XXX
 SG_ VCFRONT_LVHEALTH_pcsOpenCircuit m0 : 20|1@1+ (1,0) [0|1] "" Vector__XXX
 SG_ VCFRONT_LVHEALTH_activeDecelPowe m0 : 21|1@1+ (1,0) [0|1] "" Vector__XXX
 SG_ VCFRONT_LVHEALTH_lvBatteryCapabi m0 : 22|1@1+ (1,0) [0|1] "" Vector__XXX
 SG_ VCFRONT_LVHEALTH_lvBatteryConfig m0 : 23|1@1+ (1,0) [0|1] "" Vector__XXX
 SG_ VCFRONT_LVHEALTH_lvBatteryImpeda m0 : 24|1@1+ (1,0) [0|1] "" Vector__XXX
 SG_ VCFRONT_LVHEALTH_lvBatteryExtend m0 : 25|1@1+ (1,0) [0|1] "" Vector__XXX

BO_TX_BU_ 1351 : VCFRONT2;
BO_TX_BU_ 834 : VCFRONT2;
BO_TX_BU_ 1583 : VCFRONT2;
BO_TX_BU_ 609 : VCFRONT;
BO_TX_BU_ 1847 : VCFRONT;
BO_TX_BU_ 1140 : VCFRONT;
BO_TX_BU_ 1173 : VCFRONT;
CM_ BO_ 1351 "VCFRONT2 ECU message: alert log; frame length from the layout, not yet observed on a vehicle bus";
CM_ SG_ 1351 VCFRONT2_alertID "VCFRONT2 ECU: alert ID";
CM_ SG_ 1351 VCFRONT2_alertState "VCFRONT2 ECU: alert state";
CM_ SG_ 1351 VCFRONT2_a001_InternalWatchdog "VCFRONT2 ECU: a001 internal watchdog";
CM_ SG_ 1351 VCFRONT2_a015_NVMMMemOverflow "VCFRONT2 ECU: a015 NVMM mem overflow";
CM_ SG_ 1351 VCFRONT2_a015_NVMMFilesystemErro "VCFRONT2 ECU: a015 NVMM filesystem error";
CM_ SG_ 1351 VCFRONT2_a015_NVMMRecordIDError "VCFRONT2 ECU: a015 NVMM record ID error";
CM_ SG_ 1351 VCFRONT2_a059_voltageDrop "VCFRONT2 ECU: a059 voltage drop";
CM_ SG_ 1351 VCFRONT2_a059_resistanceEstimate "VCFRONT2 ECU: a059 resistance estimate";
CM_ SG_ 1351 VCFRONT2_a059_current "VCFRONT2 ECU: a059 current";
CM_ SG_ 1351 VCFRONT2_a063_switchChannel "VCFRONT2 ECU: a063 switch channel";
CM_ SG_ 1351 VCFRONT2_a063_switchType "VCFRONT2 ECU: a063 switch type";
CM_ SG_ 1351 VCFRONT2_a063_ADCVoltage "VCFRONT2 ECU: a063 ADC voltage";
CM_ SG_ 1351 VCFRONT2_a063_disconnected "VCFRONT2 ECU: a063 disconnected";
CM_ SG_ 1351 VCFRONT2_a063_indeterminate "VCFRONT2 ECU: a063 indeterminate";
CM_ SG_ 1351 VCFRONT2_a063_stuckActive "VCFRONT2 ECU: a063 stuck active";
CM_ SG_ 1351 VCFRONT2_a063_faulted "VCFRONT2 ECU: a063 faulted";
CM_ SG_ 1351 VCFRONT2_a091_FRONTIPC_faultsAnd "VCFRONT2 ECU: a091 FRONTIPC faults and extras";
CM_ SG_ 1351 VCFRONT2_a091_FRONTIPC_state "VCFRONT2 ECU: a091 FRONTIPC state";
CM_ SG_ 1351 VCFRONT2_a096_FRONTIPC_status "VCFRONT2 ECU: a096 FRONTIPC status";
CM_ SG_ 1351 VCFRONT2_a098_FRONTIPC_temperatu "VCFRONT2 ECU: a098 FRONTIPC temperature";
CM_ SG_ 1351 VCFRONT2_a098_FRONTIPC_thermalCo "VCFRONT2 ECU: a098 FRONTIPC thermal control";
CM_ SG_ 1351 VCFRONT2_a106_BATTIPC_dcdcRailSt "VCFRONT2 ECU: a106 BATTIPC dcdc rail status";
CM_ SG_ 1351 VCFRONT2_a106_BATTIPC_dcdcStatus "VCFRONT2 ECU: a106 BATTIPC dcdc status";
CM_ SG_ 1351 VCFRONT2_a106_VEH_dcdcStatus "VCFRONT2 ECU: a106 VEH dcdc status";
CM_ SG_ 1351 VCFRONT2_a106_VEH_thermalControl "VCFRONT2 ECU: a106 VEH thermal control";
CM_ SG_ 1351 VCFRONT2_a106_VEH_dcdcRailStatus "VCFRONT2 ECU: a106 VEH dcdc rail status";
CM_ SG_ 1351 VCFRONT2_a106_CH_dcdcRailStatus "VCFRONT2 ECU: a106 CH dcdc rail status";
CM_ SG_ 1351 VCFRONT2_a106_CH_alertMatrix "VCFRONT2 ECU: a106 CH alert matrix";
CM_ SG_ 1351 VCFRONT2_a106_FRONTIPC_thermalCo "VCFRONT2 ECU: a106 FRONTIPC thermal control";
CM_ SG_ 1351 VCFRONT2_a106_FRONTIPC_dcdcRailS "VCFRONT2 ECU: a106 FRONTIPC dcdc rail status";
CM_ SG_ 1351 VCFRONT2_a106_FRONTIPC_dcdcStatu "VCFRONT2 ECU: a106 FRONTIPC dcdc status";
CM_ SG_ 1351 VCFRONT2_a108_FRONTIPC_status "VCFRONT2 ECU: a108 FRONTIPC status";
CM_ SG_ 1351 VCFRONT2_a108_FRONTIPC_temperatu "VCFRONT2 ECU: a108 FRONTIPC temperature";
CM_ SG_ 1351 VCFRONT2_a108_FRONTIPC_thermalCo "VCFRONT2 ECU: a108 FRONTIPC thermal control";
CM_ SG_ 1351 VCFRONT2_a108_FRONTIPC_motorStat "VCFRONT2 ECU: a108 FRONTIPC motor status";
CM_ SG_ 1351 VCFRONT2_a120_BATTIPC_speed "VCFRONT2 ECU: a120 BATTIPC speed";
CM_ SG_ 1351 VCFRONT2_a120_FRONTIPC_speed "VCFRONT2 ECU: a120 FRONTIPC speed";
CM_ SG_ 1351 VCFRONT2_a120_FRONTIPC_systemSta "VCFRONT2 ECU: a120 FRONTIPC system status";
CM_ SG_ 1351 VCFRONT2_a120_BATTIPC_systemStat "VCFRONT2 ECU: a120 BATTIPC system status";
CM_ SG_ 1351 VCFRONT2_a120_FRONTIPC_systemPow "VCFRONT2 ECU: a120 FRONTIPC system power";
CM_ SG_ 1351 VCFRONT2_a120_FRONTIPC_autonomyH "VCFRONT2 ECU: a120 FRONTIPC autonomy health";
CM_ SG_ 1351 VCFRONT2_a120_BATTIPC_chassisCon "VCFRONT2 ECU: a120 BATTIPC chassis control2";
CM_ SG_ 1351 VCFRONT2_a120_FRONTIPC_chassisCo "VCFRONT2 ECU: a120 FRONTIPC chassis control2";
CM_ SG_ 1351 VCFRONT2_a120_FRONTIPC_odometerS "VCFRONT2 ECU: a120 FRONTIPC odometer status";
CM_ SG_ 1351 VCFRONT2_a124_FRONTIPC_status "VCFRONT2 ECU: a124 FRONTIPC status";
CM_ SG_ 1351 VCFRONT2_a124_BATTIPC_status "VCFRONT2 ECU: a124 BATTIPC status";
CM_ SG_ 1351 VCFRONT2_a125_FRONTIPC_leftStalk "VCFRONT2 ECU: a125 FRONTIPC left stalk";
CM_ SG_ 1351 VCFRONT2_a125_FRONTIPC_steerAngl "VCFRONT2 ECU: a125 FRONTIPC steer angle";
CM_ SG_ 1351 VCFRONT2_a125_FRONTIPC_info "VCFRONT2 ECU: a125 FRONTIPC info";
CM_ SG_ 1351 VCFRONT2_a126_FRONTIPC_sysStatus "VCFRONT2 ECU: a126 FRONTIPC sys status";
CM_ SG_ 1351 VCFRONT2_a126_BATTIPC_sysStatus "VCFRONT2 ECU: a126 BATTIPC sys status";
CM_ SG_ 1351 VCFRONT2_a126_FRONTIPC_status "VCFRONT2 ECU: a126 FRONTIPC status";
CM_ SG_ 1351 VCFRONT2_a126_BATTIPC_status "VCFRONT2 ECU: a126 BATTIPC status";
CM_ SG_ 1351 VCFRONT2_a131_FRONTIPC_power "VCFRONT2 ECU: a131 FRONTIPC power";
CM_ SG_ 1351 VCFRONT2_a131_BATTIPC_power "VCFRONT2 ECU: a131 BATTIPC power";
CM_ SG_ 1351 VCFRONT2_a133_BATTIPC_primaryAct "VCFRONT2 ECU: a133 BATTIPC primary actuator";
CM_ SG_ 1351 VCFRONT2_a133_FRONTIPC_secondary "VCFRONT2 ECU: a133 FRONTIPC secondary actuator";
CM_ SG_ 1351 VCFRONT2_a142_driverState "VCFRONT2 ECU: a142 driver state";
CM_ SG_ 1351 VCFRONT2_a142_driverThermWarn "VCFRONT2 ECU: a142 driver therm warn";
CM_ SG_ 1351 VCFRONT2_a142_driverThermShutdow "VCFRONT2 ECU: a142 driver therm shutdown";
CM_ SG_ 1351 VCFRONT2_a142_undervoltage "VCFRONT2 ECU: a142 undervoltage";
CM_ SG_ 1351 VCFRONT2_a142_chargePumpUndervol "VCFRONT2 ECU: a142 charge pump undervoltage";
CM_ SG_ 1351 VCFRONT2_a142_isCoilOpenX "VCFRONT2 ECU: a142 is coil open x";
CM_ SG_ 1351 VCFRONT2_a142_isCoilOpenY "VCFRONT2 ECU: a142 is coil open y";
CM_ SG_ 1351 VCFRONT2_a142_isCoilShortXPGnd "VCFRONT2 ECU: a142 is coil short XP gnd";
CM_ SG_ 1351 VCFRONT2_a142_isCoilShortXPVbb "VCFRONT2 ECU: a142 is coil short XP vbb";
CM_ SG_ 1351 VCFRONT2_a142_isCoilShortXNGnd "VCFRONT2 ECU: a142 is coil short XN gnd";
CM_ SG_ 1351 VCFRONT2_a142_isCoilShortXNVbb "VCFRONT2 ECU: a142 is coil short XN vbb";
CM_ SG_ 1351 VCFRONT2_a142_isCoilShortYPGnd "VCFRONT2 ECU: a142 is coil short YP gnd";
CM_ SG_ 1351 VCFRONT2_a142_isCoilShortYPVbb "VCFRONT2 ECU: a142 is coil short YP vbb";
CM_ SG_ 1351 VCFRONT2_a142_isCoilShortYNGnd "VCFRONT2 ECU: a142 is coil short YN gnd";
CM_ SG_ 1351 VCFRONT2_a142_isCoilShortYNVbb "VCFRONT2 ECU: a142 is coil short YN vbb";
CM_ SG_ 1351 VCFRONT2_a142_driverHasCommError "VCFRONT2 ECU: a142 driver has comm error";
CM_ SG_ 1351 VCFRONT2_a144_FRONTIPC_status "VCFRONT2 ECU: a144 FRONTIPC status";
CM_ SG_ 1351 VCFRONT2_a144_BATTIPC_status "VCFRONT2 ECU: a144 BATTIPC status";
CM_ SG_ 1351 VCFRONT2_a150_RPMActual "VCFRONT2 ECU: a150 RPM actual";
CM_ SG_ 1351 VCFRONT2_a150_RPMTarget "VCFRONT2 ECU: a150 RPM target";
CM_ SG_ 1351 VCFRONT2_a159_stall "VCFRONT2 ECU: a159 stall";
CM_ SG_ 1351 VCFRONT2_a159_angleActual "VCFRONT2 ECU: a159 angle actual";
CM_ SG_ 1351 VCFRONT2_a159_angleTarget "VCFRONT2 ECU: a159 angle target";
CM_ SG_ 1351 VCFRONT2_a171_VCFRONT "VCFRONT2 ECU: a171 VCFRONT";
CM_ SG_ 1351 VCFRONT2_a171_VCRIGHT "VCFRONT2 ECU: a171 VCRIGHT";
CM_ SG_ 1351 VCFRONT2_a171_VCLEFT "VCFRONT2 ECU: a171 VCLEFT";
CM_ SG_ 1351 VCFRONT2_a171_VCBATT "VCFRONT2 ECU: a171 VCBATT";
CM_ SG_ 1351 VCFRONT2_a171_BMS "VCFRONT2 ECU: a171 BMS";
CM_ SG_ 1351 VCFRONT2_a171_HVP "VCFRONT2 ECU: a171 HVP";
CM_ SG_ 1351 VCFRONT2_a171_GTW "VCFRONT2 ECU: a171 GTW";
CM_ SG_ 1351 VCFRONT2_a171_CP "VCFRONT2 ECU: a171 CP";
CM_ SG_ 1351 VCFRONT2_a171_PCS "VCFRONT2 ECU: a171 PCS";
CM_ SG_ 1351 VCFRONT2_a171_PCSCPU2 "VCFRONT2 ECU: a171 PCSCPU2";
CM_ SG_ 1351 VCFRONT2_a171_DI "VCFRONT2 ECU: a171 DI";
CM_ SG_ 1351 VCFRONT2_a171_DIS "VCFRONT2 ECU: a171 DIS";
CM_ SG_ 1351 VCFRONT2_a171_PM "VCFRONT2 ECU: a171 PM";
CM_ SG_ 1351 VCFRONT2_a171_PMS "VCFRONT2 ECU: a171 PMS";
CM_ SG_ 1351 VCFRONT2_a171_EPBR "VCFRONT2 ECU: a171 EPBR";
CM_ SG_ 1351 VCFRONT2_a171_EPBL "VCFRONT2 ECU: a171 EPBL";
CM_ SG_ 1351 VCFRONT2_a171_IBST "VCFRONT2 ECU: a171 IBST";
CM_ SG_ 1351 VCFRONT2_a171_IBSTCAL "VCFRONT2 ECU: a171 IBSTCAL";
CM_ SG_ 1351 VCFRONT2_a171_ESP "VCFRONT2 ECU: a171 ESP";
CM_ SG_ 1351 VCFRONT2_a171_ESPCAL "VCFRONT2 ECU: a171 ESPCAL";
CM_ SG_ 1351 VCFRONT2_a171_OPC "VCFRONT2 ECU: a171 OPC";
CM_ SG_ 1351 VCFRONT2_a171_OPCS "VCFRONT2 ECU: a171 OPCS";
CM_ SG_ 1351 VCFRONT2_a171_SCCM "VCFRONT2 ECU: a171 SCCM";
CM_ SG_ 1351 VCFRONT2_a171_LVBMS "VCFRONT2 ECU: a171 LVBMS";
CM_ SG_ 1351 VCFRONT2_a171_IDB "VCFRONT2 ECU: a171 IDB";
CM_ SG_ 1351 VCFRONT2_a171_IDB1 "VCFRONT2 ECU: a171 IDB1";
CM_ SG_ 1351 VCFRONT2_a171_IDBCAL "VCFRONT2 ECU: a171 IDBCAL";
CM_ SG_ 1351 VCFRONT2_a171_RCU "VCFRONT2 ECU: a171 RCU";
CM_ SG_ 1351 VCFRONT2_a171_RCUCAL "VCFRONT2 ECU: a171 RCUCAL";
CM_ SG_ 1351 VCFRONT2_a171_DPB "VCFRONT2 ECU: a171 DPB";
CM_ SG_ 1351 VCFRONT2_a171_DPBCAL "VCFRONT2 ECU: a171 DPBCAL";
CM_ SG_ 1351 VCFRONT2_a171_serviceMode "Signal reported by VCFRONT2 ECU";
CM_ SG_ 1351 VCFRONT2_a172_ECUMismatchBits "VCFRONT2 ECU: a172 ECU mismatch bits";
CM_ SG_ 1351 VCFRONT2_a172_serviceMode "Signal reported by VCFRONT2 ECU";
CM_ SG_ 1351 VCFRONT2_a173_ECUMismatchBits "VCFRONT2 ECU: a173 ECU mismatch bits";
CM_ SG_ 1351 VCFRONT2_a173_serviceMode "Signal reported by VCFRONT2 ECU";
CM_ SG_ 1351 VCFRONT2_a176_vehicleState "VCFRONT2 ECU: a176 vehicle state";
CM_ SG_ 1351 VCFRONT2_a186_noDriveChgCableCon "VCFRONT2 ECU: a186 no drive chg cable con x";
CM_ SG_ 1351 VCFRONT2_a187_vehBusRetryCount "VCFRONT2 ECU: a187 veh bus retry count";
CM_ SG_ 1351 VCFRONT2_a187_partyBusRetryCount "VCFRONT2 ECU: a187 party bus retry count";
CM_ SG_ 1351 VCFRONT2_a187_hvsBusRetryCount "VCFRONT2 ECU: a187 hvs bus retry count";
CM_ SG_ 1351 VCFRONT2_a187_ethBusRetryCount "VCFRONT2 ECU: a187 eth bus retry count";
CM_ SG_ 1351 VCFRONT2_a187_chBusRetryCount "VCFRONT2 ECU: a187 ch bus retry count";
CM_ SG_ 1351 VCFRONT2_a195_LVVoltage "VCFRONT2 ECU: a195 LV voltage";
CM_ SG_ 1351 VCFRONT2_a195_serviceMode "Signal reported by VCFRONT2 ECU";
CM_ SG_ 1351 VCFRONT2_a195_frunkOpen "VCFRONT2 ECU: a195 frunk open";
CM_ SG_ 1351 VCFRONT2_a210_valveUnderTravel "VCFRONT2 ECU: a210 valve under travel";
CM_ SG_ 1351 VCFRONT2_a210_valveOverTravel "VCFRONT2 ECU: a210 valve over travel";
CM_ SG_ 1351 VCFRONT2_a210_valveNoTravel "VCFRONT2 ECU: a210 valve no travel";
CM_ SG_ 1351 VCFRONT2_a214_motorFaulted "VCFRONT2 ECU: a214 motor faulted";
CM_ SG_ 1351 VCFRONT2_a214_motorLocked "VCFRONT2 ECU: a214 motor locked";
CM_ SG_ 1351 VCFRONT2_a214_ecuReset "VCFRONT2 ECU: a214 ecu reset";
CM_ SG_ 1351 VCFRONT2_a214_fetTempIrrational "VCFRONT2 ECU: a214 fet temp irrational";
CM_ SG_ 1351 VCFRONT2_a214_motorControlError "VCFRONT2 ECU: a214 motor control error";
CM_ SG_ 1351 VCFRONT2_a214_underVoltage "VCFRONT2 ECU: a214 under voltage";
CM_ SG_ 1351 VCFRONT2_a214_overVoltage "VCFRONT2 ECU: a214 over voltage";
CM_ SG_ 1351 VCFRONT2_a214_hardwareOvercurren "VCFRONT2 ECU: a214 hardware overcurrent";
CM_ SG_ 1351 VCFRONT2_a214_motorOpenPhase "VCFRONT2 ECU: a214 motor open phase";
CM_ SG_ 1351 VCFRONT2_a214_motorSoftOpenPhase "VCFRONT2 ECU: a214 motor soft open phase";
CM_ SG_ 1351 VCFRONT2_a214_motorOvertemp "VCFRONT2 ECU: a214 motor overtemp";
CM_ SG_ 1351 VCFRONT2_a214_dcOvercurrent "VCFRONT2 ECU: a214 dc overcurrent";
CM_ SG_ 1351 VCFRONT2_a214_motorStalled "VCFRONT2 ECU: a214 motor stalled";
CM_ SG_ 1351 VCFRONT2_a214_selfTestFailed "VCFRONT2 ECU: a214 self test failed";
CM_ SG_ 1351 VCFRONT2_a214_selfTestResult "VCFRONT2 ECU: a214 self test result";
CM_ SG_ 1351 VCFRONT2_a214_linChecksumError "VCFRONT2 ECU: a214 lin checksum error";
CM_ SG_ 1351 VCFRONT2_a214_linFramingError "VCFRONT2 ECU: a214 lin framing error";
CM_ SG_ 1351 VCFRONT2_a214_phaseShorted "VCFRONT2 ECU: a214 phase shorted";
CM_ SG_ 1351 VCFRONT2_a214_busVoltageIrration "VCFRONT2 ECU: a214 bus voltage irrational";
CM_ SG_ 1351 VCFRONT2_a214_dcCurrentIrrationa "VCFRONT2 ECU: a214 dc current irrational";
CM_ SG_ 1351 VCFRONT2_a214_motorSpeedIrration "VCFRONT2 ECU: a214 motor speed irrational";
CM_ SG_ 1351 VCFRONT2_a214_supplyVoltageIrrat "VCFRONT2 ECU: a214 supply voltage irrational";
CM_ SG_ 1351 VCFRONT2_a214_motorPhaseCurrentI "VCFRONT2 ECU: a214 motor phase current irrational";
CM_ SG_ 1351 VCFRONT2_a214_chipOvertemp "VCFRONT2 ECU: a214 chip overtemp";
CM_ SG_ 1351 VCFRONT2_a214_motorSpeedTooHigh "VCFRONT2 ECU: a214 motor speed too high";
CM_ SG_ 1351 VCFRONT2_a214_phaseOvercurrent "VCFRONT2 ECU: a214 phase overcurrent";
CM_ SG_ 1351 VCFRONT2_a214_vddaOvercurrent "VCFRONT2 ECU: a214 vdda overcurrent";
CM_ SG_ 1351 VCFRONT2_a214_busVoltageUnhealth "VCFRONT2 ECU: a214 bus voltage unhealthy";
CM_ SG_ 1351 VCFRONT2_a214_hsVdsOvervoltage "VCFRONT2 ECU: a214 hs vds overvoltage";
CM_ SG_ 1351 VCFRONT2_a214_hsVdsOvervoltageMa "VCFRONT2 ECU: a214 hs vds overvoltage mask";
CM_ SG_ 1351 VCFRONT2_a214_lsVdsOvervoltage "VCFRONT2 ECU: a214 ls vds overvoltage";
CM_ SG_ 1351 VCFRONT2_a214_lsVdsOvervoltageMa "VCFRONT2 ECU: a214 ls vds overvoltage mask";
CM_ SG_ 1351 VCFRONT2_a214_payloadBitsNotSet "VCFRONT2 ECU: a214 payload bits not set";
CM_ SG_ 1351 VCFRONT2_a217_motorFaulted "VCFRONT2 ECU: a217 motor faulted";
CM_ SG_ 1351 VCFRONT2_a217_motorLocked "VCFRONT2 ECU: a217 motor locked";
CM_ SG_ 1351 VCFRONT2_a217_ecuReset "VCFRONT2 ECU: a217 ecu reset";
CM_ SG_ 1351 VCFRONT2_a217_fetTempIrrational "VCFRONT2 ECU: a217 fet temp irrational";
CM_ SG_ 1351 VCFRONT2_a217_motorControlError "VCFRONT2 ECU: a217 motor control error";
CM_ SG_ 1351 VCFRONT2_a217_underVoltage "VCFRONT2 ECU: a217 under voltage";
CM_ SG_ 1351 VCFRONT2_a217_overVoltage "VCFRONT2 ECU: a217 over voltage";
CM_ SG_ 1351 VCFRONT2_a217_hardwareOvercurren "VCFRONT2 ECU: a217 hardware overcurrent";
CM_ SG_ 1351 VCFRONT2_a217_motorOpenPhase "VCFRONT2 ECU: a217 motor open phase";
CM_ SG_ 1351 VCFRONT2_a217_motorSoftOpenPhase "VCFRONT2 ECU: a217 motor soft open phase";
CM_ SG_ 1351 VCFRONT2_a217_motorOvertemp "VCFRONT2 ECU: a217 motor overtemp";
CM_ SG_ 1351 VCFRONT2_a217_dcOvercurrent "VCFRONT2 ECU: a217 dc overcurrent";
CM_ SG_ 1351 VCFRONT2_a217_motorStalled "VCFRONT2 ECU: a217 motor stalled";
CM_ SG_ 1351 VCFRONT2_a217_selfTestFailed "VCFRONT2 ECU: a217 self test failed";
CM_ SG_ 1351 VCFRONT2_a217_selfTestResult "VCFRONT2 ECU: a217 self test result";
CM_ SG_ 1351 VCFRONT2_a217_linChecksumError "VCFRONT2 ECU: a217 lin checksum error";
CM_ SG_ 1351 VCFRONT2_a217_linFramingError "VCFRONT2 ECU: a217 lin framing error";
CM_ SG_ 1351 VCFRONT2_a217_phaseShorted "VCFRONT2 ECU: a217 phase shorted";
CM_ SG_ 1351 VCFRONT2_a217_busVoltageIrration "VCFRONT2 ECU: a217 bus voltage irrational";
CM_ SG_ 1351 VCFRONT2_a217_dcCurrentIrrationa "VCFRONT2 ECU: a217 dc current irrational";
CM_ SG_ 1351 VCFRONT2_a217_motorSpeedIrration "VCFRONT2 ECU: a217 motor speed irrational";
CM_ SG_ 1351 VCFRONT2_a217_supplyVoltageIrrat "VCFRONT2 ECU: a217 supply voltage irrational";
CM_ SG_ 1351 VCFRONT2_a217_motorPhaseCurrentI "VCFRONT2 ECU: a217 motor phase current irrational";
CM_ SG_ 1351 VCFRONT2_a217_chipOvertemp "VCFRONT2 ECU: a217 chip overtemp";
CM_ SG_ 1351 VCFRONT2_a217_motorSpeedTooHigh "VCFRONT2 ECU: a217 motor speed too high";
CM_ SG_ 1351 VCFRONT2_a217_phaseOvercurrent "VCFRONT2 ECU: a217 phase overcurrent";
CM_ SG_ 1351 VCFRONT2_a217_vddaOvercurrent "VCFRONT2 ECU: a217 vdda overcurrent";
CM_ SG_ 1351 VCFRONT2_a217_busVoltageUnhealth "VCFRONT2 ECU: a217 bus voltage unhealthy";
CM_ SG_ 1351 VCFRONT2_a217_hsVdsOvervoltage "VCFRONT2 ECU: a217 hs vds overvoltage";
CM_ SG_ 1351 VCFRONT2_a217_hsVdsOvervoltageMa "VCFRONT2 ECU: a217 hs vds overvoltage mask";
CM_ SG_ 1351 VCFRONT2_a217_lsVdsOvervoltage "VCFRONT2 ECU: a217 ls vds overvoltage";
CM_ SG_ 1351 VCFRONT2_a217_lsVdsOvervoltageMa "VCFRONT2 ECU: a217 ls vds overvoltage mask";
CM_ SG_ 1351 VCFRONT2_a217_payloadBitsNotSet "VCFRONT2 ECU: a217 payload bits not set";
CM_ SG_ 1351 VCFRONT2_a235_ptSensorTemp "VCFRONT2 ECU: a235 pt sensor temp";
CM_ SG_ 1351 VCFRONT2_a236_batSensorTemp "VCFRONT2 ECU: a236 bat sensor temp";
CM_ SG_ 1351 VCFRONT2_a247_solenoidISense "VCFRONT2 ECU: a247 solenoid i sense";
CM_ SG_ 1351 VCFRONT2_a249_tempCoolantBatInle "VCFRONT2 ECU: a249 temp coolant bat inlet";
CM_ SG_ 1351 VCFRONT2_a249_tempCoolantPTInlet "VCFRONT2 ECU: a249 temp coolant PT inlet";
CM_ SG_ 1351 VCFRONT2_a254_RPMActual "VCFRONT2 ECU: a254 RPM actual";
CM_ SG_ 1351 VCFRONT2_a254_RPMTarget "VCFRONT2 ECU: a254 RPM target";
CM_ SG_ 1351 VCFRONT2_a283_thmlFanDisabled "VCFRONT2 ECU: a283 thml fan disabled";
CM_ SG_ 1351 VCFRONT2_a283_thmlFanLimited "VCFRONT2 ECU: a283 thml fan limited";
CM_ SG_ 1351 VCFRONT2_a283_thmlFanDemand "VCFRONT2 ECU: a283 thml fan demand";
CM_ SG_ 1351 VCFRONT2_a283_thmlFanDemandLimit "VCFRONT2 ECU: a283 thml fan demand limit";
CM_ SG_ 1351 VCFRONT2_a283_thmlFanPhaseI "VCFRONT2 ECU: a283 thml fan phase i";
CM_ SG_ 1351 VCFRONT2_a283_thmlFanPhaseILimit "VCFRONT2 ECU: a283 thml fan phase i limit";
CM_ SG_ 1351 VCFRONT2_a284_driverState "VCFRONT2 ECU: a284 driver state";
CM_ SG_ 1351 VCFRONT2_a284_driverThermWarn "VCFRONT2 ECU: a284 driver therm warn";
CM_ SG_ 1351 VCFRONT2_a284_driverThermShutdow "VCFRONT2 ECU: a284 driver therm shutdown";
CM_ SG_ 1351 VCFRONT2_a284_undervoltage "VCFRONT2 ECU: a284 undervoltage";
CM_ SG_ 1351 VCFRONT2_a284_chargePumpUndervol "VCFRONT2 ECU: a284 charge pump undervoltage";
CM_ SG_ 1351 VCFRONT2_a284_isCoilOpenX "VCFRONT2 ECU: a284 is coil open x";
CM_ SG_ 1351 VCFRONT2_a284_isCoilOpenY "VCFRONT2 ECU: a284 is coil open y";
CM_ SG_ 1351 VCFRONT2_a284_isCoilShortXPGnd "VCFRONT2 ECU: a284 is coil short XP gnd";
CM_ SG_ 1351 VCFRONT2_a284_isCoilShortXPVbb "VCFRONT2 ECU: a284 is coil short XP vbb";
CM_ SG_ 1351 VCFRONT2_a284_isCoilShortXNGnd "VCFRONT2 ECU: a284 is coil short XN gnd";
CM_ SG_ 1351 VCFRONT2_a284_isCoilShortXNVbb "VCFRONT2 ECU: a284 is coil short XN vbb";
CM_ SG_ 1351 VCFRONT2_a284_isCoilShortYPGnd "VCFRONT2 ECU: a284 is coil short YP gnd";
CM_ SG_ 1351 VCFRONT2_a284_isCoilShortYPVbb "VCFRONT2 ECU: a284 is coil short YP vbb";
CM_ SG_ 1351 VCFRONT2_a284_isCoilShortYNGnd "VCFRONT2 ECU: a284 is coil short YN gnd";
CM_ SG_ 1351 VCFRONT2_a284_isCoilShortYNVbb "VCFRONT2 ECU: a284 is coil short YN vbb";
CM_ SG_ 1351 VCFRONT2_a284_driverHasCommError "VCFRONT2 ECU: a284 driver has comm error";
CM_ SG_ 1351 VCFRONT2_a285_driverState "VCFRONT2 ECU: a285 driver state";
CM_ SG_ 1351 VCFRONT2_a285_driverThermWarn "VCFRONT2 ECU: a285 driver therm warn";
CM_ SG_ 1351 VCFRONT2_a285_driverThermShutdow "VCFRONT2 ECU: a285 driver therm shutdown";
CM_ SG_ 1351 VCFRONT2_a285_undervoltage "VCFRONT2 ECU: a285 undervoltage";
CM_ SG_ 1351 VCFRONT2_a285_chargePumpUndervol "VCFRONT2 ECU: a285 charge pump undervoltage";
CM_ SG_ 1351 VCFRONT2_a285_isCoilOpenX "VCFRONT2 ECU: a285 is coil open x";
CM_ SG_ 1351 VCFRONT2_a285_isCoilOpenY "VCFRONT2 ECU: a285 is coil open y";
CM_ SG_ 1351 VCFRONT2_a285_isCoilShortXPGnd "VCFRONT2 ECU: a285 is coil short XP gnd";
CM_ SG_ 1351 VCFRONT2_a285_isCoilShortXPVbb "VCFRONT2 ECU: a285 is coil short XP vbb";
CM_ SG_ 1351 VCFRONT2_a285_isCoilShortXNGnd "VCFRONT2 ECU: a285 is coil short XN gnd";
CM_ SG_ 1351 VCFRONT2_a285_isCoilShortXNVbb "VCFRONT2 ECU: a285 is coil short XN vbb";
CM_ SG_ 1351 VCFRONT2_a285_isCoilShortYPGnd "VCFRONT2 ECU: a285 is coil short YP gnd";
CM_ SG_ 1351 VCFRONT2_a285_isCoilShortYPVbb "VCFRONT2 ECU: a285 is coil short YP vbb";
CM_ SG_ 1351 VCFRONT2_a285_isCoilShortYNGnd "VCFRONT2 ECU: a285 is coil short YN gnd";
CM_ SG_ 1351 VCFRONT2_a285_isCoilShortYNVbb "VCFRONT2 ECU: a285 is coil short YN vbb";
CM_ SG_ 1351 VCFRONT2_a285_driverHasCommError "VCFRONT2 ECU: a285 driver has comm error";
CM_ SG_ 1351 VCFRONT2_a286_driverState "VCFRONT2 ECU: a286 driver state";
CM_ SG_ 1351 VCFRONT2_a286_driverThermWarn "VCFRONT2 ECU: a286 driver therm warn";
CM_ SG_ 1351 VCFRONT2_a286_driverThermShutdow "VCFRONT2 ECU: a286 driver therm shutdown";
CM_ SG_ 1351 VCFRONT2_a286_undervoltage "VCFRONT2 ECU: a286 undervoltage";
CM_ SG_ 1351 VCFRONT2_a286_chargePumpUndervol "VCFRONT2 ECU: a286 charge pump undervoltage";
CM_ SG_ 1351 VCFRONT2_a286_isCoilOpenX "VCFRONT2 ECU: a286 is coil open x";
CM_ SG_ 1351 VCFRONT2_a286_isCoilOpenY "VCFRONT2 ECU: a286 is coil open y";
CM_ SG_ 1351 VCFRONT2_a286_isCoilShortXPGnd "VCFRONT2 ECU: a286 is coil short XP gnd";
CM_ SG_ 1351 VCFRONT2_a286_isCoilShortXPVbb "VCFRONT2 ECU: a286 is coil short XP vbb";
CM_ SG_ 1351 VCFRONT2_a286_isCoilShortXNGnd "VCFRONT2 ECU: a286 is coil short XN gnd";
CM_ SG_ 1351 VCFRONT2_a286_isCoilShortXNVbb "VCFRONT2 ECU: a286 is coil short XN vbb";
CM_ SG_ 1351 VCFRONT2_a286_isCoilShortYPGnd "VCFRONT2 ECU: a286 is coil short YP gnd";
CM_ SG_ 1351 VCFRONT2_a286_isCoilShortYPVbb "VCFRONT2 ECU: a286 is coil short YP vbb";
CM_ SG_ 1351 VCFRONT2_a286_isCoilShortYNGnd "VCFRONT2 ECU: a286 is coil short YN gnd";
CM_ SG_ 1351 VCFRONT2_a286_isCoilShortYNVbb "VCFRONT2 ECU: a286 is coil short YN vbb";
CM_ SG_ 1351 VCFRONT2_a286_driverHasCommError "VCFRONT2 ECU: a286 driver has comm error";
CM_ SG_ 1351 VCFRONT2_a287_driverState "VCFRONT2 ECU: a287 driver state";
CM_ SG_ 1351 VCFRONT2_a287_driverThermWarn "VCFRONT2 ECU: a287 driver therm warn";
CM_ SG_ 1351 VCFRONT2_a287_driverThermShutdow "VCFRONT2 ECU: a287 driver therm shutdown";
CM_ SG_ 1351 VCFRONT2_a287_undervoltage "VCFRONT2 ECU: a287 undervoltage";
CM_ SG_ 1351 VCFRONT2_a287_chargePumpUndervol "VCFRONT2 ECU: a287 charge pump undervoltage";
CM_ SG_ 1351 VCFRONT2_a287_isCoilOpenX "VCFRONT2 ECU: a287 is coil open x";
CM_ SG_ 1351 VCFRONT2_a287_isCoilOpenY "VCFRONT2 ECU: a287 is coil open y";
CM_ SG_ 1351 VCFRONT2_a287_isCoilShortXPGnd "VCFRONT2 ECU: a287 is coil short XP gnd";
CM_ SG_ 1351 VCFRONT2_a287_isCoilShortXPVbb "VCFRONT2 ECU: a287 is coil short XP vbb";
CM_ SG_ 1351 VCFRONT2_a287_isCoilShortXNGnd "VCFRONT2 ECU: a287 is coil short XN gnd";
CM_ SG_ 1351 VCFRONT2_a287_isCoilShortXNVbb "VCFRONT2 ECU: a287 is coil short XN vbb";
CM_ SG_ 1351 VCFRONT2_a287_isCoilShortYPGnd "VCFRONT2 ECU: a287 is coil short YP gnd";
CM_ SG_ 1351 VCFRONT2_a287_isCoilShortYPVbb "VCFRONT2 ECU: a287 is coil short YP vbb";
CM_ SG_ 1351 VCFRONT2_a287_isCoilShortYNGnd "VCFRONT2 ECU: a287 is coil short YN gnd";
CM_ SG_ 1351 VCFRONT2_a287_isCoilShortYNVbb "VCFRONT2 ECU: a287 is coil short YN vbb";
CM_ SG_ 1351 VCFRONT2_a287_driverHasCommError "VCFRONT2 ECU: a287 driver has comm error";
CM_ SG_ 1351 VCFRONT2_a288_driverState "VCFRONT2 ECU: a288 driver state";
CM_ SG_ 1351 VCFRONT2_a288_driverThermWarn "VCFRONT2 ECU: a288 driver therm warn";
CM_ SG_ 1351 VCFRONT2_a288_driverThermShutdow "VCFRONT2 ECU: a288 driver therm shutdown";
CM_ SG_ 1351 VCFRONT2_a288_undervoltage "VCFRONT2 ECU: a288 undervoltage";
CM_ SG_ 1351 VCFRONT2_a288_chargePumpUndervol "VCFRONT2 ECU: a288 charge pump undervoltage";
CM_ SG_ 1351 VCFRONT2_a288_isCoilOpenX "VCFRONT2 ECU: a288 is coil open x";
CM_ SG_ 1351 VCFRONT2_a288_isCoilOpenY "VCFRONT2 ECU: a288 is coil open y";
CM_ SG_ 1351 VCFRONT2_a288_isCoilShortXPGnd "VCFRONT2 ECU: a288 is coil short XP gnd";
CM_ SG_ 1351 VCFRONT2_a288_isCoilShortXPVbb "VCFRONT2 ECU: a288 is coil short XP vbb";
CM_ SG_ 1351 VCFRONT2_a288_isCoilShortXNGnd "VCFRONT2 ECU: a288 is coil short XN gnd";
CM_ SG_ 1351 VCFRONT2_a288_isCoilShortXNVbb "VCFRONT2 ECU: a288 is coil short XN vbb";
CM_ SG_ 1351 VCFRONT2_a288_isCoilShortYPGnd "VCFRONT2 ECU: a288 is coil short YP gnd";
CM_ SG_ 1351 VCFRONT2_a288_isCoilShortYPVbb "VCFRONT2 ECU: a288 is coil short YP vbb";
CM_ SG_ 1351 VCFRONT2_a288_isCoilShortYNGnd "VCFRONT2 ECU: a288 is coil short YN gnd";
CM_ SG_ 1351 VCFRONT2_a288_isCoilShortYNVbb "VCFRONT2 ECU: a288 is coil short YN vbb";
CM_ SG_ 1351 VCFRONT2_a288_driverHasCommError "VCFRONT2 ECU: a288 driver has comm error";
CM_ SG_ 1351 VCFRONT2_a289_driverState "VCFRONT2 ECU: a289 driver state";
CM_ SG_ 1351 VCFRONT2_a289_driverThermWarn "VCFRONT2 ECU: a289 driver therm warn";
CM_ SG_ 1351 VCFRONT2_a289_driverThermShutdow "VCFRONT2 ECU: a289 driver therm shutdown";
CM_ SG_ 1351 VCFRONT2_a289_undervoltage "VCFRONT2 ECU: a289 undervoltage";
CM_ SG_ 1351 VCFRONT2_a289_chargePumpUndervol "VCFRONT2 ECU: a289 charge pump undervoltage";
CM_ SG_ 1351 VCFRONT2_a289_isCoilOpenX "VCFRONT2 ECU: a289 is coil open x";
CM_ SG_ 1351 VCFRONT2_a289_isCoilOpenY "VCFRONT2 ECU: a289 is coil open y";
CM_ SG_ 1351 VCFRONT2_a289_isCoilShortXPGnd "VCFRONT2 ECU: a289 is coil short XP gnd";
CM_ SG_ 1351 VCFRONT2_a289_isCoilShortXPVbb "VCFRONT2 ECU: a289 is coil short XP vbb";
CM_ SG_ 1351 VCFRONT2_a289_isCoilShortXNGnd "VCFRONT2 ECU: a289 is coil short XN gnd";
CM_ SG_ 1351 VCFRONT2_a289_isCoilShortXNVbb "VCFRONT2 ECU: a289 is coil short XN vbb";
CM_ SG_ 1351 VCFRONT2_a289_isCoilShortYPGnd "VCFRONT2 ECU: a289 is coil short YP gnd";
CM_ SG_ 1351 VCFRONT2_a289_isCoilShortYPVbb "VCFRONT2 ECU: a289 is coil short YP vbb";
CM_ SG_ 1351 VCFRONT2_a289_isCoilShortYNGnd "VCFRONT2 ECU: a289 is coil short YN gnd";
CM_ SG_ 1351 VCFRONT2_a289_isCoilShortYNVbb "VCFRONT2 ECU: a289 is coil short YN vbb";
CM_ SG_ 1351 VCFRONT2_a289_driverHasCommError "VCFRONT2 ECU: a289 driver has comm error";
CM_ SG_ 1351 VCFRONT2_a302_LINFrameStatus "VCFRONT2 ECU: a302 LIN frame status";
CM_ SG_ 1351 VCFRONT2_a355_fluidNotFilled "VCFRONT2 ECU: a355 fluid not filled";
CM_ SG_ 1351 VCFRONT2_a355_systemNotCommissio "VCFRONT2 ECU: a355 system not commissioned";
CM_ SG_ 1351 VCFRONT2_a355_serviceLockout "VCFRONT2 ECU: a355 service lockout";
CM_ SG_ 1351 VCFRONT2_a355_factoryGated "VCFRONT2 ECU: a355 factory gated";
CM_ SG_ 1351 VCFRONT2_a356_fluidNotFilled "VCFRONT2 ECU: a356 fluid not filled";
CM_ SG_ 1351 VCFRONT2_a356_systemNotCommissio "VCFRONT2 ECU: a356 system not commissioned";
CM_ SG_ 1351 VCFRONT2_a356_serviceLockout "VCFRONT2 ECU: a356 service lockout";
CM_ SG_ 1351 VCFRONT2_a356_factoryGated "VCFRONT2 ECU: a356 factory gated";
CM_ SG_ 1351 VCFRONT2_a356_refCommissionStatu "VCFRONT2 ECU: a356 ref commission status";
CM_ SG_ 1351 VCFRONT2_a360_vehicleLoadShedAct "VCFRONT2 ECU: a360 vehicle load shed active";
CM_ SG_ 1351 VCFRONT2_a360_notEnoughPowerForS "VCFRONT2 ECU: a360 not enough power for support";
CM_ SG_ 1351 VCFRONT2_a367_bmsSoc "VCFRONT2 ECU: a367 bms soc";
CM_ SG_ 1351 VCFRONT2_a368_bmsRequestRemoved "VCFRONT2 ECU: a368 bms request removed";
CM_ SG_ 1351 VCFRONT2_a368_enteringState "VCFRONT2 ECU: a368 entering state";
CM_ SG_ 1351 VCFRONT2_a368_exitingState "VCFRONT2 ECU: a368 exiting state";
CM_ SG_ 1351 VCFRONT2_a368_bmsSoc "VCFRONT2 ECU: a368 bms soc";
CM_ SG_ 1351 VCFRONT2_a368_systemFaulted "VCFRONT2 ECU: a368 system faulted";
CM_ SG_ 1351 VCFRONT2_a368_coolantTempSensors "VCFRONT2 ECU: a368 coolant temp sensors faulted";
CM_ SG_ 1351 VCFRONT2_a368_coolantValveFaulte "VCFRONT2 ECU: a368 coolant valve faulted";
CM_ SG_ 1351 VCFRONT2_a368_louverFaulted "VCFRONT2 ECU: a368 louver faulted";
CM_ SG_ 1351 VCFRONT2_a368_fansFaulted "VCFRONT2 ECU: a368 fans faulted";
CM_ SG_ 1351 VCFRONT2_a368_coolantNotFilled "VCFRONT2 ECU: a368 coolant not filled";
CM_ SG_ 1351 VCFRONT2_a368_coolantPumpsFaulte "VCFRONT2 ECU: a368 coolant pumps faulted";
CM_ SG_ 1351 VCFRONT2_a368_preconditionsNotMe "VCFRONT2 ECU: a368 preconditions not met";
CM_ SG_ 1351 VCFRONT2_a368_belowSocMin "VCFRONT2 ECU: a368 below soc min";
CM_ SG_ 1351 VCFRONT2_a369_powerGenerationLim "VCFRONT2 ECU: a369 power generation limited";
CM_ SG_ 1351 VCFRONT2_a369_heatRejectionLimit "VCFRONT2 ECU: a369 heat rejection limited";
CM_ SG_ 1351 VCFRONT2_a369_bmsSoc "VCFRONT2 ECU: a369 bms soc";
CM_ SG_ 1351 VCFRONT2_a369_wasteHeatPower "VCFRONT2 ECU: a369 waste heat power";
CM_ SG_ 1351 VCFRONT2_a374_lccInletSolenoidIS "VCFRONT2 ECU: a374 lcc inlet solenoid i sense";
CM_ SG_ 1351 VCFRONT2_a377_wiperStuckOutOfPar "VCFRONT2 ECU: a377 wiper stuck out of park";
CM_ SG_ 1351 VCFRONT2_a377_wiperStuckInPark "VCFRONT2 ECU: a377 wiper stuck in park";
CM_ SG_ 1351 VCFRONT2_a397_discharge "VCFRONT2 ECU: a397 discharge";
CM_ SG_ 1351 VCFRONT2_a397_suction "VCFRONT2 ECU: a397 suction";
CM_ SG_ 1351 VCFRONT2_a397_liquid "VCFRONT2 ECU: a397 liquid";
CM_ SG_ 1351 VCFRONT2_a397_offsetError "VCFRONT2 ECU: a397 offset error";
CM_ SG_ 1351 VCFRONT2_a397_runTimeOffSetDetec "VCFRONT2 ECU: a397 run time off set detected";
CM_ SG_ 1351 VCFRONT2_a409_brushlessMotorConf "VCFRONT2 ECU: a409 brushless motor configuration invalid";
CM_ SG_ 1351 VCFRONT2_a446_compFaultRefrigera "VCFRONT2 ECU: a446 comp fault refrigerant";
CM_ SG_ 1351 VCFRONT2_a446_compFaultTdHigh "VCFRONT2 ECU: a446 comp fault td high";
CM_ SG_ 1351 VCFRONT2_a446_compFaultPdLow "VCFRONT2 ECU: a446 comp fault pd low";
CM_ SG_ 1351 VCFRONT2_a446_compFaultPdHigh "VCFRONT2 ECU: a446 comp fault pd high";
CM_ SG_ 1351 VCFRONT2_a446_compFaultPsLow "VCFRONT2 ECU: a446 comp fault ps low";
CM_ SG_ 1351 VCFRONT2_a446_compStandbyLowAmbi "VCFRONT2 ECU: a446 comp standby low ambient";
CM_ SG_ 1351 VCFRONT2_a446_compStandbyLowDisc "VCFRONT2 ECU: a446 comp standby low disch press";
CM_ SG_ 1351 VCFRONT2_a446_compStandbyHVNotRe "VCFRONT2 ECU: a446 comp standby HV not ready";
CM_ SG_ 1351 VCFRONT2_a446_compStandbyCommuni "VCFRONT2 ECU: a446 comp standby communication";
CM_ SG_ 1351 VCFRONT2_a446_compStandbySelfNot "VCFRONT2 ECU: a446 comp standby self not ready";
CM_ SG_ 1351 VCFRONT2_a446_compStandbyRefrigN "VCFRONT2 ECU: a446 comp standby refrig not ok";
CM_ SG_ 1351 VCFRONT2_a446_compStandbyCoastDo "VCFRONT2 ECU: a446 comp standby coast down mode";
CM_ SG_ 1351 VCFRONT2_a446_compStandbyMultipl "VCFRONT2 ECU: a446 comp standby multiple pd cutouts";
CM_ SG_ 1351 VCFRONT2_a446_compStandbyShowroo "VCFRONT2 ECU: a446 comp standby showroom mode";
CM_ SG_ 1351 VCFRONT2_a446_compStandbyMu_0001 "VCFRONT2 ECU: a446 comp standby multiple td cutouts";
CM_ SG_ 1351 VCFRONT2_a446_hpCabinLoadType "VCFRONT2 ECU: a446 hp cabin load type";
CM_ SG_ 1351 VCFRONT2_a446_hpBatteryLoadType "VCFRONT2 ECU: a446 hp battery load type";
CM_ SG_ 1351 VCFRONT2_a446_usingModeledPs "VCFRONT2 ECU: a446 using modeled ps";
CM_ SG_ 1351 VCFRONT2_a446_usingModeledPd "VCFRONT2 ECU: a446 using modeled pd";
CM_ SG_ 1351 VCFRONT2_a446_usingModeledPl "VCFRONT2 ECU: a446 using modeled pl";
CM_ SG_ 1351 VCFRONT2_a446_usingModeledTs "VCFRONT2 ECU: a446 using modeled ts";
CM_ SG_ 1351 VCFRONT2_a446_usingModeledTd "VCFRONT2 ECU: a446 using modeled td";
CM_ SG_ 1351 VCFRONT2_a446_usingModeledTl "VCFRONT2 ECU: a446 using modeled tl";
CM_ SG_ 1351 VCFRONT2_a446_sensorHasOffsetTd "VCFRONT2 ECU: a446 sensor has offset td";
CM_ SG_ 1351 VCFRONT2_a446_sensorHasOffsetPd "VCFRONT2 ECU: a446 sensor has offset pd";
CM_ SG_ 1351 VCFRONT2_a446_sensorDroopPd "VCFRONT2 ECU: a446 sensor droop pd";
CM_ SG_ 1351 VCFRONT2_a446_sensorHasOffsetTl "VCFRONT2 ECU: a446 sensor has offset tl";
CM_ SG_ 1351 VCFRONT2_a446_sensorIntermi_0002 "VCFRONT2 ECU: a446 sensor intermittent ps";
CM_ SG_ 1351 VCFRONT2_a446_sensorIntermittent "VCFRONT2 ECU: a446 sensor intermittent pd";
CM_ SG_ 1351 VCFRONT2_a446_sensorIntermi_0001 "VCFRONT2 ECU: a446 sensor intermittent pl";
CM_ SG_ 1351 VCFRONT2_a446_sensorIntermi_0005 "VCFRONT2 ECU: a446 sensor intermittent ts";
CM_ SG_ 1351 VCFRONT2_a446_sensorIntermi_0003 "VCFRONT2 ECU: a446 sensor intermittent td";
CM_ SG_ 1351 VCFRONT2_a446_sensorIntermi_0004 "VCFRONT2 ECU: a446 sensor intermittent tl";
CM_ SG_ 1351 VCFRONT2_a446_highSuctionSuperhe "VCFRONT2 ECU: a446 high suction superheat";
CM_ SG_ 1351 VCFRONT2_a446_evapLowPsCutout "VCFRONT2 ECU: a446 evap low ps cutout";
CM_ SG_ 1351 VCFRONT2_a446_batteryOverTemp "VCFRONT2 ECU: a446 battery over temp";
CM_ SG_ 1351 VCFRONT2_a446_hvacSystemFault "VCFRONT2 ECU: a446 hvac system fault";
CM_ SG_ 1351 VCFRONT2_a446_coolantSysLockedOu "VCFRONT2 ECU: a446 coolant sys locked out";
CM_ SG_ 1351 VCFRONT2_a446_refSysLockedOut "VCFRONT2 ECU: a446 ref sys locked out";
CM_ SG_ 1351 VCFRONT2_a446_chillerEXVNotReady "VCFRONT2 ECU: a446 chiller EXV not ready";
CM_ SG_ 1351 VCFRONT2_a446_CCLEXVNotReady "VCFRONT2 ECU: a446 CCLEXV not ready";
CM_ SG_ 1351 VCFRONT2_a446_CCREXVNotReady "VCFRONT2 ECU: a446 CCREXV not ready";
CM_ SG_ 1351 VCFRONT2_a446_LCCEXVNotReady "VCFRONT2 ECU: a446 LCCEXV not ready";
CM_ SG_ 1351 VCFRONT2_a446_evapEXVNotReady "VCFRONT2 ECU: a446 evap EXV not ready";
CM_ SG_ 1351 VCFRONT2_a446_recircEXVNotReady "VCFRONT2 ECU: a446 recirc EXV not ready";
CM_ SG_ 1351 VCFRONT2_a446_checkA447Alert "VCFRONT2 ECU: a446 check A447 alert";
CM_ SG_ 1351 VCFRONT2_a447_caseHVACUnavailabl "VCFRONT2 ECU: a447 case HVAC unavailable";
CM_ SG_ 1351 VCFRONT2_a447_heatPumpHVACUnavai "VCFRONT2 ECU: a447 heat pump HVAC unavailable";
CM_ SG_ 1351 VCFRONT2_a447_activeLouverCompro "VCFRONT2 ECU: a447 active louver compromised";
CM_ SG_ 1351 VCFRONT2_a447_coolantValveCompro "VCFRONT2 ECU: a447 coolant valve compromised";
CM_ SG_ 1351 VCFRONT2_a447_ambientSourcingCom "VCFRONT2 ECU: a447 ambient sourcing compromised";
CM_ SG_ 1351 VCFRONT2_a447_scavengeLoopCompro "VCFRONT2 ECU: a447 scavenge loop compromised";
CM_ SG_ 1351 VCFRONT2_a447_coolantSystemCompr "VCFRONT2 ECU: a447 coolant system compromised";
CM_ SG_ 1351 VCFRONT2_a447_hvBattActiveDischg "VCFRONT2 ECU: a447 hv batt active dischg compromised";
CM_ SG_ 1351 VCFRONT2_a447_hvBatteryDischargi "VCFRONT2 ECU: a447 hv battery discharging compromised";
CM_ SG_ 1351 VCFRONT2_a447_lccSolenoidComprom "VCFRONT2 ECU: a447 lcc solenoid compromised";
CM_ SG_ 1351 VCFRONT2_a447_refrigerantSystemC "VCFRONT2 ECU: a447 refrigerant system compromised";
CM_ SG_ 1351 VCFRONT2_a447_powertrainThermalF "VCFRONT2 ECU: a447 powertrain thermal fans compromised";
CM_ SG_ 1351 VCFRONT2_a447_refrigDischargePre "VCFRONT2 ECU: a447 refrig discharge press compromised";
CM_ SG_ 1351 VCFRONT2_a447_refrigeDischargeTe "VCFRONT2 ECU: a447 refrige discharge temp compromised";
CM_ SG_ 1351 VCFRONT2_a447_refrigSuctionPress "VCFRONT2 ECU: a447 refrig suction press compromised";
CM_ SG_ 1351 VCFRONT2_a447_refrigSuctionTempC "VCFRONT2 ECU: a447 refrig suction temp compromised";
CM_ SG_ 1351 VCFRONT2_a447_refrigLiquidPressC "VCFRONT2 ECU: a447 refrig liquid press compromised";
CM_ SG_ 1351 VCFRONT2_a447_refrigLiquidTempCo "VCFRONT2 ECU: a447 refrig liquid temp compromised";
CM_ SG_ 1351 VCFRONT2_a459_coolantFillActive "VCFRONT2 ECU: a459 coolant fill active";
CM_ SG_ 1351 VCFRONT2_a459_refrigerantFillAct "VCFRONT2 ECU: a459 refrigerant fill active";
CM_ SG_ 1351 VCFRONT2_a464_flowIndex "VCFRONT2 ECU: a464 flow index";
CM_ SG_ 1351 VCFRONT2_a464_flowIndexFiltered "VCFRONT2 ECU: a464 flow index filtered";
CM_ SG_ 1351 VCFRONT2_a464_subcool "VCFRONT2 ECU: a464 subcool";
CM_ SG_ 1351 VCFRONT2_a464_subcoolFiltered "VCFRONT2 ECU: a464 subcool filtered";
CM_ SG_ 1351 VCFRONT2_a465_flowIndex "VCFRONT2 ECU: a465 flow index";
CM_ SG_ 1351 VCFRONT2_a465_flowIndexFiltered "VCFRONT2 ECU: a465 flow index filtered";
CM_ SG_ 1351 VCFRONT2_a465_subcool "VCFRONT2 ECU: a465 subcool";
CM_ SG_ 1351 VCFRONT2_a465_subcoolFiltered "VCFRONT2 ECU: a465 subcool filtered";
CM_ SG_ 1351 VCFRONT2_a465_flaggedAtSteadySta "VCFRONT2 ECU: a465 flagged at steady state";
CM_ SG_ 1351 VCFRONT2_a465_flaggedAtUnsteadyS "VCFRONT2 ECU: a465 flagged at unsteady state";
CM_ SG_ 1351 VCFRONT2_a466_flowIndex "VCFRONT2 ECU: a466 flow index";
CM_ SG_ 1351 VCFRONT2_a466_flowIndexFiltered "VCFRONT2 ECU: a466 flow index filtered";
CM_ SG_ 1351 VCFRONT2_a466_subcool "VCFRONT2 ECU: a466 subcool";
CM_ SG_ 1351 VCFRONT2_a466_subcoolFiltered "VCFRONT2 ECU: a466 subcool filtered";
CM_ SG_ 1351 VCFRONT2_a467_powerIndexFiltered "VCFRONT2 ECU: a467 power index filtered";
CM_ SG_ 1351 VCFRONT2_a470_pressureLiquid "VCFRONT2 ECU: a470 pressure liquid";
CM_ SG_ 1351 VCFRONT2_a470_pressureDischarge "VCFRONT2 ECU: a470 pressure discharge";
CM_ SG_ 1351 VCFRONT2_a490_coolantPumpType "VCFRONT2 ECU: a490 coolant pump type";
CM_ SG_ 1351 VCFRONT2_a511_PCSEFuseCurrent "VCFRONT2 ECU: a511 PCSE fuse current";
CM_ SG_ 1351 VCFRONT2_a511_DCDCMaxOutputCurre "VCFRONT2 ECU: a511 DCDC max output current allowed";
CM_ SG_ 1351 VCFRONT2_a511_hvState "VCFRONT2 ECU: a511 hv state";
CM_ SG_ 1351 VCFRONT2_a511_DCDCOutputIsLimite "VCFRONT2 ECU: a511 DCDC output is limited";
CM_ SG_ 1351 VCFRONT2_a511_PCSSignalsAreValid "VCFRONT2 ECU: a511 PCS signals are valid";
CM_ SG_ 1351 VCFRONT2_a511_factoryGated "VCFRONT2 ECU: a511 factory gated";
CM_ SG_ 1351 VCFRONT2_a511_vehicleIsUpdating "VCFRONT2 ECU: a511 vehicle is updating";
CM_ SG_ 1351 VCFRONT2_a511_serviceMode "Signal reported by VCFRONT2 ECU";
CM_ SG_ 1351 VCFRONT2_a511_frunkOpen "VCFRONT2 ECU: a511 frunk open";
CM_ SG_ 1351 VCFRONT2_a531_powerIndexFiltered "VCFRONT2 ECU: a531 power index filtered";
CM_ SG_ 1351 VCFRONT2_a560_highSHCOP1 "VCFRONT2 ECU: a560 high SHCOP1";
CM_ SG_ 1351 VCFRONT2_a560_highSHBattConditio "VCFRONT2 ECU: a560 high SH batt conditioning";
CM_ SG_ 1351 VCFRONT2_a560_highSHCabinReheatC "VCFRONT2 ECU: a560 high SH cabin reheat CD";
CM_ SG_ 1351 VCFRONT2_a560_highSHCabinReheatH "VCFRONT2 ECU: a560 high SH cabin reheat HD";
CM_ SG_ 1351 VCFRONT2_a560_highSHCabinCooling "VCFRONT2 ECU: a560 high SH cabin cooling";
CM_ SG_ 1351 VCFRONT2_a560_highSHCabinHeating "VCFRONT2 ECU: a560 high SH cabin heating";
CM_ SG_ 1351 VCFRONT2_a560_highSHCatchAll "VCFRONT2 ECU: a560 high SH catch all";
CM_ SG_ 1351 VCFRONT2_a615_FRONTIPC_switchSta "VCFRONT2 ECU: a615 FRONTIPC switch status";
CM_ SG_ 1351 VCFRONT2_a616_FRONTIPC_switchSta "VCFRONT2 ECU: a616 FRONTIPC switch status";
CM_ SG_ 1351 VCFRONT2_a667_hcmRegionAndSide "VCFRONT2 ECU: a667 hcm region and side; raw 0 = signal not available (SNA)";
CM_ SG_ 1351 VCFRONT2_a667_country "VCFRONT2 ECU: a667 country";
CM_ SG_ 1351 VCFRONT2_a667_homologationRegion "VCFRONT2 ECU: a667 homologation region override";
CM_ SG_ 1351 VCFRONT2_a667_isRightHandDrive "VCFRONT2 ECU: a667 is right hand drive";
CM_ SG_ 1351 VCFRONT2_a697_isGlobalHeadlamps "VCFRONT2 ECU: a697 is global headlamps";
CM_ SG_ 1351 VCFRONT2_a697_isVirtualPitchSens "VCFRONT2 ECU: a697 is virtual pitch sensor";
CM_ SG_ 1351 VCFRONT2_a697_calibratedVertical "VCFRONT2 ECU: a697 calibrated vertical position HCML; raw 1023 = signal not available (SNA)";
CM_ SG_ 1351 VCFRONT2_a697_calibratedHorizont "VCFRONT2 ECU: a697 calibrated horizontal position HCML; raw 1023 = signal not available (SNA)";
CM_ BO_ 834 "VCFRONT2 ECU message: alert matrix; frame length from the layout, not yet observed on a vehicle bus";
CM_ SG_ 834 VCFRONT2_matrixIndex "VCFRONT2 ECU: matrix index";
CM_ SG_ 834 VCFRONT2_a001_WatchdogReset "VCFRONT2 ECU: a001 watchdog reset";
CM_ SG_ 834 VCFRONT2_a002_PowerLossReset "VCFRONT2 ECU: a002 power loss reset";
CM_ SG_ 834 VCFRONT2_a003_SWAssertion "VCFRONT2 ECU: a003 SW assertion";
CM_ SG_ 834 VCFRONT2_a004_adaptiveHeadlights "VCFRONT2 ECU: a004 adaptive headlights unavailable";
CM_ SG_ 834 VCFRONT2_a005_CANTXError "VCFRONT2 ECU: a005 CANTX error";
CM_ SG_ 834 VCFRONT2_a006_CANTX_cyclicError "VCFRONT2 ECU: a006 CANTX cyclic error";
CM_ SG_ 834 VCFRONT2_a008_adaptiveHeadlights "VCFRONT2 ECU: a008 adaptive headlights unavailable stalk";
CM_ SG_ 834 VCFRONT2_a009_LCCPurgeAttempted "VCFRONT2 ECU: a009 LCC purge attempted";
CM_ SG_ 834 VCFRONT2_a012_CPUReset "VCFRONT2 ECU: a012 CPU reset";
CM_ SG_ 834 VCFRONT2_a013_AlertManagerFault "VCFRONT2 ECU: a013 alert manager fault";
CM_ SG_ 834 VCFRONT2_a015_NVMMError "VCFRONT2 ECU: a015 NVMM error";
CM_ SG_ 834 VCFRONT2_a016_NVMMRecordError "VCFRONT2 ECU: a016 NVMM record error";
CM_ SG_ 834 VCFRONT2_a017_NVMMStatusDbg "VCFRONT2 ECU: a017 NVMM status dbg";
CM_ SG_ 834 VCFRONT2_a018_HardFault "VCFRONT2 ECU: a018 hard fault";
CM_ SG_ 834 VCFRONT2_a019_BusFault "VCFRONT2 ECU: a019 bus fault";
CM_ SG_ 834 VCFRONT2_a021_TaskSchedulerError "VCFRONT2 ECU: a021 task scheduler error";
CM_ SG_ 834 VCFRONT2_a022_TaskInitError "VCFRONT2 ECU: a022 task init error";
CM_ SG_ 834 VCFRONT2_a028_UsageFault "VCFRONT2 ECU: a028 usage fault";
CM_ SG_ 834 VCFRONT2_a029_CoreDump "VCFRONT2 ECU: a029 core dump";
CM_ SG_ 834 VCFRONT2_a030_ECULogUploadReques "VCFRONT2 ECU: a030 ECU log upload request";
CM_ SG_ 834 VCFRONT2_a031_UDSActive "VCFRONT2 ECU: a031 UDS active";
CM_ SG_ 834 VCFRONT2_a036_UnknownIrq "VCFRONT2 ECU: a036 unknown irq";
CM_ SG_ 834 VCFRONT2_a037_MemManageFault "VCFRONT2 ECU: a037 mem manage fault";
CM_ SG_ 834 VCFRONT2_a038_ProtFaultInfo "VCFRONT2 ECU: a038 prot fault info";
CM_ SG_ 834 VCFRONT2_a039_ProtFaultAddress "VCFRONT2 ECU: a039 prot fault address";
CM_ SG_ 834 VCFRONT2_a040_Backtrace "VCFRONT2 ECU: a040 backtrace";
CM_ SG_ 834 VCFRONT2_a041_HighCPULoad "VCFRONT2 ECU: a041 high CPU load";
CM_ SG_ 834 VCFRONT2_a042_HighStackUsage "VCFRONT2 ECU: a042 high stack usage";
CM_ SG_ 834 VCFRONT2_a043_Task1msError "VCFRONT2 ECU: a043 task1ms error";
CM_ SG_ 834 VCFRONT2_a044_Task10msError "VCFRONT2 ECU: a044 task10ms error";
CM_ SG_ 834 VCFRONT2_a045_Task100msError "VCFRONT2 ECU: a045 task100ms error";
CM_ SG_ 834 VCFRONT2_a046_Task1000msError "VCFRONT2 ECU: a046 task1000ms error";
CM_ SG_ 834 VCFRONT2_a053_wiperCommErrorUser "VCFRONT2 ECU: a053 wiper comm error user";
CM_ SG_ 834 VCFRONT2_a054_compressorLowFlowU "VCFRONT2 ECU: a054 compressor low flow user facing";
CM_ SG_ 834 VCFRONT2_a058_inputRHighSyncDebu "VCFRONT2 ECU: a058 input r high sync debug";
CM_ SG_ 834 VCFRONT2_a059_inputResistanceHig "VCFRONT2 ECU: a059 input resistance high";
CM_ SG_ 834 VCFRONT2_a060_engineeringBuild "VCFRONT2 ECU: a060 engineering build";
CM_ SG_ 834 VCFRONT2_a061_XCPConnected "VCFRONT2 ECU: a061 XCP connected";
CM_ SG_ 834 VCFRONT2_a062_XCPWasConnected "VCFRONT2 ECU: a062 XCP was connected";
CM_ SG_ 834 VCFRONT2_a063_SwitchFault "VCFRONT2 ECU: a063 switch fault";
CM_ SG_ 834 VCFRONT2_a064_busSleepReqTimeout "VCFRONT2 ECU: a064 bus sleep req timeout";
CM_ SG_ 834 VCFRONT2_a077_VCBATT0_MIA "VCFRONT2 ECU: a077 VCBATT0 MIA";
CM_ SG_ 834 VCFRONT2_a078_VCBATT1_MIA "VCFRONT2 ECU: a078 VCBATT1 MIA";
CM_ SG_ 834 VCFRONT2_a079_VCBATT2_MIA "VCFRONT2 ECU: a079 VCBATT2 MIA";
CM_ SG_ 834 VCFRONT2_a080_VCFRONT0_MIA "VCFRONT2 ECU: a080 VCFRONT0 MIA";
CM_ SG_ 834 VCFRONT2_a081_VCFRONT1_MIA "VCFRONT2 ECU: a081 VCFRONT1 MIA";
CM_ SG_ 834 VCFRONT2_a082_VCFRONT2_MIA "VCFRONT2 ECU: a082 VCFRONT2 MIA";
CM_ SG_ 834 VCFRONT2_a086_VCBATT_MIA "VCFRONT2 ECU: a086 VCBATT MIA";
CM_ SG_ 834 VCFRONT2_a090_APS_MIA "VCFRONT2 ECU: a090 APS MIA";
CM_ SG_ 834 VCFRONT2_a091_CMPD_MIA "VCFRONT2 ECU: a091 CMPD MIA";
CM_ SG_ 834 VCFRONT2_a096_OCS1P_MIA "VCFRONT2 ECU: a096 OCS1 p MIA";
CM_ SG_ 834 VCFRONT2_a098_DIR_MIA "VCFRONT2 ECU: a098 DIR MIA";
CM_ SG_ 834 VCFRONT2_a100_CANbus_MIA "VCFRONT2 ECU: a100 CA nbus MIA";
CM_ SG_ 834 VCFRONT2_a103_CP_MIA "VCFRONT2 ECU: a103 CP MIA";
CM_ SG_ 834 VCFRONT2_a104_DAS_MIA "VCFRONT2 ECU: a104 DAS MIA";
CM_ SG_ 834 VCFRONT2_a105_TAS_MIA "VCFRONT2 ECU: a105 TAS MIA";
CM_ SG_ 834 VCFRONT2_a106_PCS_MIA "VCFRONT2 ECU: a106 PCS MIA";
CM_ SG_ 834 VCFRONT2_a107_BMS_MIA "VCFRONT2 ECU: a107 BMS MIA";
CM_ SG_ 834 VCFRONT2_a108_DIF_MIA "VCFRONT2 ECU: a108 DIF MIA";
CM_ SG_ 834 VCFRONT2_a109_RCM_MIA "VCFRONT2 ECU: a109 RCM MIA";
CM_ SG_ 834 VCFRONT2_a110_GTW_MIA "VCFRONT2 ECU: a110 GTW MIA";
CM_ SG_ 834 VCFRONT2_a111_EPBR_MIA "VCFRONT2 ECU: a111 EPBR MIA";
CM_ SG_ 834 VCFRONT2_a112_EPBL_MIA "VCFRONT2 ECU: a112 EPBL MIA";
CM_ SG_ 834 VCFRONT2_a113_UI_MIA "VCFRONT2 ECU: a113 UI MIA";
CM_ SG_ 834 VCFRONT2_a114_ESP_MIA "VCFRONT2 ECU: a114 ESP MIA";
CM_ SG_ 834 VCFRONT2_a115_VCSEC_MIA "VCFRONT2 ECU: a115 VCSEC MIA";
CM_ SG_ 834 VCFRONT2_a116_VCRIGHT_MIA "VCFRONT2 ECU: a116 VCRIGHT MIA";
CM_ SG_ 834 VCFRONT2_a117_VCLEFT_MIA "VCFRONT2 ECU: a117 VCLEFT MIA";
CM_ SG_ 834 VCFRONT2_a118_VCFRONT_MIA "VCFRONT2 ECU: a118 VCFRONT MIA";
CM_ SG_ 834 VCFRONT2_a119_SCCM_MIA "VCFRONT2 ECU: a119 SCCM MIA";
CM_ SG_ 834 VCFRONT2_a120_DI_DRIVE_MIA "VCFRONT2 ECU: a120 DI DRIVE MIA";
CM_ SG_ 834 VCFRONT2_a122_ICR_MIA "VCFRONT2 ECU: a122 ICR MIA";
CM_ SG_ 834 VCFRONT2_a123_VC_SECONDARY_LIGHT "VCFRONT2 ECU: a123 VC SECONDARY LIGHTING LEADER MIA";
CM_ SG_ 834 VCFRONT2_a124_BB_MIA "VCFRONT2 ECU: a124 BB MIA";
CM_ SG_ 834 VCFRONT2_a125_SCCM_MIA "VCFRONT2 ECU: a125 SCCM MIA";
CM_ SG_ 834 VCFRONT2_a126_EPAS3P_MIA "VCFRONT2 ECU: a126 EPAS3 p MIA";
CM_ SG_ 834 VCFRONT2_a131_PCSCOMMON_MIA "VCFRONT2 ECU: a131 PCSCOMMON MIA";
CM_ SG_ 834 VCFRONT2_a133_BRAKE_MIA "VCFRONT2 ECU: a133 BRAKE MIA";
CM_ SG_ 834 VCFRONT2_a135_coolantLevelLow "VCFRONT2 ECU: a135 coolant level low";
CM_ SG_ 834 VCFRONT2_a136_refrigDischTempSns "VCFRONT2 ECU: a136 refrig disch temp sns";
CM_ SG_ 834 VCFRONT2_a137_refrigDischPresSns "VCFRONT2 ECU: a137 refrig disch pres sns";
CM_ SG_ 834 VCFRONT2_a138_refrigSuctTempSns "VCFRONT2 ECU: a138 refrig suct temp sns";
CM_ SG_ 834 VCFRONT2_a139_refrigSuctPresSns "VCFRONT2 ECU: a139 refrig suct pres sns";
CM_ SG_ 834 VCFRONT2_a140_coolantTempPtSns "VCFRONT2 ECU: a140 coolant temp pt sns";
CM_ SG_ 834 VCFRONT2_a141_coolantTempBatSns "VCFRONT2 ECU: a141 coolant temp bat sns";
CM_ SG_ 834 VCFRONT2_a142_exvMotorFault "VCFRONT2 ECU: a142 exv motor fault";
CM_ SG_ 834 VCFRONT2_a143_powerLossDuringSle "VCFRONT2 ECU: a143 power loss during sleep";
CM_ SG_ 834 VCFRONT2_a144_EPAS3S_MIA "VCFRONT2 ECU: a144 EPAS3 s MIA";
CM_ SG_ 834 VCFRONT2_a150_pumpBatLowRPMCBang "VCFRONT2 ECU: a150 pump bat low RPMC bang";
CM_ SG_ 834 VCFRONT2_a153_userPresenceDispla "VCFRONT2 ECU: a153 user presence display mismatch clrd";
CM_ SG_ 834 VCFRONT2_a155_autopilotDriveNotA "VCFRONT2 ECU: a155 autopilot drive not authed";
CM_ SG_ 834 VCFRONT2_a159_coolantValveFault "VCFRONT2 ECU: a159 coolant valve fault";
CM_ SG_ 834 VCFRONT2_a160_compressorInhibite "VCFRONT2 ECU: a160 compressor inhibited";
CM_ SG_ 834 VCFRONT2_a161_compressorSelfFaul "VCFRONT2 ECU: a161 compressor self fault";
CM_ SG_ 834 VCFRONT2_a162_compressorInhibite "VCFRONT2 ECU: a162 compressor inhibited context";
CM_ SG_ 834 VCFRONT2_a163_compressorDisabled "VCFRONT2 ECU: a163 compressor disabled FSR";
CM_ SG_ 834 VCFRONT2_a167_leftHCMMIA "VCFRONT2 ECU: a167 left HCMMIA";
CM_ SG_ 834 VCFRONT2_a171_driveBlckdByMsmtch "VCFRONT2 ECU: a171 drive blckd by msmtch";
CM_ SG_ 834 VCFRONT2_a172_wsteHtBlckdByMsmtc "VCFRONT2 ECU: a172 wste ht blckd by msmtch";
CM_ SG_ 834 VCFRONT2_a173_HVBlckdByMsmtch "VCFRONT2 ECU: a173 HV blckd by msmtch";
CM_ SG_ 834 VCFRONT2_a174_driveNotAuthed "VCFRONT2 ECU: a174 drive not authed";
CM_ SG_ 834 VCFRONT2_a176_vehicleInSelfTest "VCFRONT2 ECU: a176 vehicle in self test";
CM_ SG_ 834 VCFRONT2_a178_compLiquidPumpOut "VCFRONT2 ECU: a178 comp liquid pump out";
CM_ SG_ 834 VCFRONT2_a184_cabinCoolingPerfor "VCFRONT2 ECU: a184 cabin cooling performance abnormal";
CM_ SG_ 834 VCFRONT2_a186_noDriveChgCableCon "VCFRONT2 ECU: a186 no drive chg cable con";
CM_ SG_ 834 VCFRONT2_a187_busesNotSleeping "VCFRONT2 ECU: a187 buses not sleeping";
CM_ SG_ 834 VCFRONT2_a188_sleepFailed "VCFRONT2 ECU: a188 sleep failed";
CM_ SG_ 834 VCFRONT2_a195_drveBlckdVltgeTooH "VCFRONT2 ECU: a195 drve blckd vltge too hgh";
CM_ SG_ 834 VCFRONT2_a210_coolantValveCalib "VCFRONT2 ECU: a210 coolant valve calib";
CM_ SG_ 834 VCFRONT2_a214_ptPumpCompromised "VCFRONT2 ECU: a214 pt pump compromised";
CM_ SG_ 834 VCFRONT2_a215_ptPumpMIA "VCFRONT2 ECU: a215 pt pump MIA";
CM_ SG_ 834 VCFRONT2_a217_battPumpCompromise "VCFRONT2 ECU: a217 batt pump compromised";
CM_ SG_ 834 VCFRONT2_a218_socMonitorDetected "VCFRONT2 ECU: a218 soc monitor detected threshold soc";
CM_ SG_ 834 VCFRONT2_a225_driveBlckdByShowro "VCFRONT2 ECU: a225 drive blckd by showroom";
CM_ SG_ 834 VCFRONT2_a226_battPumpMIA "VCFRONT2 ECU: a226 batt pump MIA";
CM_ SG_ 834 VCFRONT2_a232_lowSideControllerH "VCFRONT2 ECU: a232 low side controller high fdbk";
CM_ SG_ 834 VCFRONT2_a235_ptTempSnsIrrationa "VCFRONT2 ECU: a235 pt temp sns irrational";
CM_ SG_ 834 VCFRONT2_a236_batTempSnsIrration "VCFRONT2 ECU: a236 bat temp sns irrational";
CM_ SG_ 834 VCFRONT2_a240_lowSideCompromised "VCFRONT2 ECU: a240 low side compromised";
CM_ SG_ 834 VCFRONT2_a247_evapSolenoidFault "VCFRONT2 ECU: a247 evap solenoid fault";
CM_ SG_ 834 VCFRONT2_a249_coolantValveBadMod "VCFRONT2 ECU: a249 coolant valve bad mode";
CM_ SG_ 834 VCFRONT2_a250_headlampsNotAimed "VCFRONT2 ECU: a250 headlamps not aimed";
CM_ SG_ 834 VCFRONT2_a251_UIWakeupTrigger "VCFRONT2 ECU: a251 UI wakeup trigger";
CM_ SG_ 834 VCFRONT2_a254_pumpBatStopped "VCFRONT2 ECU: a254 pump bat stopped";
CM_ SG_ 834 VCFRONT2_a273_wiperFrictionModel "VCFRONT2 ECU: a273 wiper friction model fault";
CM_ SG_ 834 VCFRONT2_a279_refrigLiquidTempSn "VCFRONT2 ECU: a279 refrig liquid temp sns";
CM_ SG_ 834 VCFRONT2_a280_refrigLiquidPresSn "VCFRONT2 ECU: a280 refrig liquid pres sns";
CM_ SG_ 834 VCFRONT2_a281_alcoholInterlockBl "VCFRONT2 ECU: a281 alcohol interlock blocking drive";
CM_ SG_ 834 VCFRONT2_a282_coolantLevelSensor "VCFRONT2 ECU: a282 coolant level sensor fault";
CM_ SG_ 834 VCFRONT2_a283_thmlFanLimitedByCu "VCFRONT2 ECU: a283 thml fan limited by current";
CM_ SG_ 834 VCFRONT2_a284_chillerExvFault "VCFRONT2 ECU: a284 chiller exv fault";
CM_ SG_ 834 VCFRONT2_a285_evaporatorExvFault "VCFRONT2 ECU: a285 evaporator exv fault";
CM_ SG_ 834 VCFRONT2_a286_recircExvFault "VCFRONT2 ECU: a286 recirc exv fault";
CM_ SG_ 834 VCFRONT2_a287_lccExvFault "VCFRONT2 ECU: a287 lcc exv fault";
CM_ SG_ 834 VCFRONT2_a288_ccLeftExvFault "VCFRONT2 ECU: a288 cc left exv fault";
CM_ SG_ 834 VCFRONT2_a289_ccRightExvFault "VCFRONT2 ECU: a289 cc right exv fault";
CM_ SG_ 834 VCFRONT2_a294_leftSideRepeaterLi "VCFRONT2 ECU: a294 left side repeater light fault";
CM_ SG_ 834 VCFRONT2_a298_radiatorLowAirFlow "VCFRONT2 ECU: a298 radiator low air flow detected";
CM_ SG_ 834 VCFRONT2_a301_wipersFactoryDisab "VCFRONT2 ECU: a301 wipers factory disabled";
CM_ SG_ 834 VCFRONT2_a302_wiperCommError "VCFRONT2 ECU: a302 wiper comm error";
CM_ SG_ 834 VCFRONT2_a355_coolantSysLockout "VCFRONT2 ECU: a355 coolant sys lockout";
CM_ SG_ 834 VCFRONT2_a356_refrigSysLockout "VCFRONT2 ECU: a356 refrig sys lockout";
CM_ SG_ 834 VCFRONT2_a360_ungracefulAccPlusE "VCFRONT2 ECU: a360 ungraceful acc plus exit";
CM_ SG_ 834 VCFRONT2_a365_burnInRoutineEnter "VCFRONT2 ECU: a365 burn in routine entered";
CM_ SG_ 834 VCFRONT2_a366_burnInRoutineExite "VCFRONT2 ECU: a366 burn in routine exited";
CM_ SG_ 834 VCFRONT2_a367_dischargeRoutineEn "VCFRONT2 ECU: a367 discharge routine entered";
CM_ SG_ 834 VCFRONT2_a368_dischargeRoutineEx "VCFRONT2 ECU: a368 discharge routine exited";
CM_ SG_ 834 VCFRONT2_a369_reducedPowerDischa "VCFRONT2 ECU: a369 reduced power discharge";
CM_ SG_ 834 VCFRONT2_a374_lccInletSolenoidFa "VCFRONT2 ECU: a374 lcc inlet solenoid fault";
CM_ SG_ 834 VCFRONT2_a377_wiperParkFault "VCFRONT2 ECU: a377 wiper park fault";
CM_ SG_ 834 VCFRONT2_a378_wiperECUDebug "VCFRONT2 ECU: a378 wiper ECU debug";
CM_ SG_ 834 VCFRONT2_a380_chillerExvWarning "VCFRONT2 ECU: a380 chiller exv warning";
CM_ SG_ 834 VCFRONT2_a381_evaporatorExvWarni "VCFRONT2 ECU: a381 evaporator exv warning";
CM_ SG_ 834 VCFRONT2_a382_recircExvWarning "VCFRONT2 ECU: a382 recirc exv warning";
CM_ SG_ 834 VCFRONT2_a383_lccExvWarning "VCFRONT2 ECU: a383 lcc exv warning";
CM_ SG_ 834 VCFRONT2_a384_ccLeftExvWarning "VCFRONT2 ECU: a384 cc left exv warning";
CM_ SG_ 834 VCFRONT2_a385_ccRightExvWarning "VCFRONT2 ECU: a385 cc right exv warning";
CM_ SG_ 834 VCFRONT2_a386_exvMotorWarning "VCFRONT2 ECU: a386 exv motor warning";
CM_ SG_ 834 VCFRONT2_a393_ambientTempNetwork "VCFRONT2 ECU: a393 ambient temp network sna";
CM_ SG_ 834 VCFRONT2_a394_pressureSensorChec "VCFRONT2 ECU: a394 pressure sensor check fault";
CM_ SG_ 834 VCFRONT2_a395_pressureSensorChec "VCFRONT2 ECU: a395 pressure sensor check inconclusive";
CM_ SG_ 834 VCFRONT2_a396_coolantLevelLowUse "VCFRONT2 ECU: a396 coolant level low user facing";
CM_ SG_ 834 VCFRONT2_a397_temperatureSensorC "VCFRONT2 ECU: a397 temperature sensor check fault";
CM_ SG_ 834 VCFRONT2_a398_tempSensorCheckInc "VCFRONT2 ECU: a398 temp sensor check inconclusive";
CM_ SG_ 834 VCFRONT2_a409_invalidConfigurati "VCFRONT2 ECU: a409 invalid configuration";
CM_ SG_ 834 VCFRONT2_a420_holidayParty "VCFRONT2 ECU: a420 holiday party";
CM_ SG_ 834 VCFRONT2_a421_leftHeadlampUartCo "VCFRONT2 ECU: a421 left headlamp uart condition";
CM_ SG_ 834 VCFRONT2_a423_rtosSleepFailed "VCFRONT2 ECU: a423 rtos sleep failed";
CM_ SG_ 834 VCFRONT2_a446_cabinHVACUnavailab "VCFRONT2 ECU: a446 cabin HVAC unavailable context";
CM_ SG_ 834 VCFRONT2_a447_cabinHVACUnavailab "VCFRONT2 ECU: a447 cabin HVAC unavailable";
CM_ SG_ 834 VCFRONT2_a451_refrigerantNotComm "VCFRONT2 ECU: a451 refrigerant not commissioned";
CM_ SG_ 834 VCFRONT2_a452_dischargePresSensI "VCFRONT2 ECU: a452 discharge pres sens intermittent";
CM_ SG_ 834 VCFRONT2_a453_dischargeTempSensI "VCFRONT2 ECU: a453 discharge temp sens intermittent";
CM_ SG_ 834 VCFRONT2_a454_suctionPresSensInt "VCFRONT2 ECU: a454 suction pres sens intermittent";
CM_ SG_ 834 VCFRONT2_a455_suctionTempSensInt "VCFRONT2 ECU: a455 suction temp sens intermittent";
CM_ SG_ 834 VCFRONT2_a456_liquidPresSensInte "VCFRONT2 ECU: a456 liquid pres sens intermittent";
CM_ SG_ 834 VCFRONT2_a457_liquidTempSensInte "VCFRONT2 ECU: a457 liquid temp sens intermittent";
CM_ SG_ 834 VCFRONT2_a458_grosslyLowRefriger "VCFRONT2 ECU: a458 grossly low refrigerant";
CM_ SG_ 834 VCFRONT2_a459_thermalFillAndDriv "VCFRONT2 ECU: a459 thermal fill and drive";
CM_ SG_ 834 VCFRONT2_a460_hardIsentropicTdFa "VCFRONT2 ECU: a460 hard isentropic td failed";
CM_ SG_ 834 VCFRONT2_a464_highFlowIndexHighS "VCFRONT2 ECU: a464 high flow index high subcool flagged";
CM_ SG_ 834 VCFRONT2_a465_lowFlowIndexHighSu "VCFRONT2 ECU: a465 low flow index high subcool flagged";
CM_ SG_ 834 VCFRONT2_a466_highFlowIndexLowSu "VCFRONT2 ECU: a466 high flow index low subcool flagged";
CM_ SG_ 834 VCFRONT2_a467_lowPowerIndexFlagg "VCFRONT2 ECU: a467 low power index flagged";
CM_ SG_ 834 VCFRONT2_a468_highPowerIndexFlag "VCFRONT2 ECU: a468 high power index flagged";
CM_ SG_ 834 VCFRONT2_a469_prvPopDetected "VCFRONT2 ECU: a469 prv pop detected";
CM_ SG_ 834 VCFRONT2_a470_implausiblePdPlDet "VCFRONT2 ECU: a470 implausible pd pl detected";
CM_ SG_ 834 VCFRONT2_a471_hcm5Debug "VCFRONT2 ECU: a471 hcm5 debug";
CM_ SG_ 834 VCFRONT2_a474_leftHeadlampIntern "VCFRONT2 ECU: a474 left headlamp internal error";
CM_ SG_ 834 VCFRONT2_a489_ValveStuckFlagged "VCFRONT2 ECU: a489 valve stuck flagged";
CM_ SG_ 834 VCFRONT2_a490_coolantPumpsNotIde "VCFRONT2 ECU: a490 coolant pumps not identified";
CM_ SG_ 834 VCFRONT2_a499_loadShedPumpFlowRe "VCFRONT2 ECU: a499 load shed pump flow request";
CM_ SG_ 834 VCFRONT2_a504_airInRefrigerantDe "VCFRONT2 ECU: a504 air in refrigerant detected";
CM_ SG_ 834 VCFRONT2_a506_invalidRefrigerant "VCFRONT2 ECU: a506 invalid refrigerant system config";
CM_ SG_ 834 VCFRONT2_a507_leftHeadlampAiming "VCFRONT2 ECU: a507 left headlamp aiming fault";
CM_ SG_ 834 VCFRONT2_a511_DCDCSaturationLoad "VCFRONT2 ECU: a511 DCDC saturation load shed";
CM_ SG_ 834 VCFRONT2_a519_leftHeadlampIntern "VCFRONT2 ECU: a519 left headlamp internal error V2";
CM_ SG_ 834 VCFRONT2_a531_lowPowerIndexFlagg "VCFRONT2 ECU: a531 low power index flagged user facing";
CM_ SG_ 834 VCFRONT2_a534_chillerExvCalibIni "VCFRONT2 ECU: a534 chiller exv calib init debug";
CM_ SG_ 834 VCFRONT2_a535_evapExvCalibInitDe "VCFRONT2 ECU: a535 evap exv calib init debug";
CM_ SG_ 834 VCFRONT2_a536_recircExvCalibInit "VCFRONT2 ECU: a536 recirc exv calib init debug";
CM_ SG_ 834 VCFRONT2_a537_lccExvCalibInitDeb "VCFRONT2 ECU: a537 lcc exv calib init debug";
CM_ SG_ 834 VCFRONT2_a538_cclExvCalibInitDeb "VCFRONT2 ECU: a538 ccl exv calib init debug";
CM_ SG_ 834 VCFRONT2_a539_ccrExvCalibInitDeb "VCFRONT2 ECU: a539 ccr exv calib init debug";
CM_ SG_ 834 VCFRONT2_a540_radiatorSteamDetec "VCFRONT2 ECU: a540 radiator steam detected";
CM_ SG_ 834 VCFRONT2_a542_refrigerantReclaim "VCFRONT2 ECU: a542 refrigerant reclaim";
CM_ SG_ 834 VCFRONT2_a543_compressorLowFlowD "VCFRONT2 ECU: a543 compressor low flow delivery detected";
CM_ SG_ 834 VCFRONT2_a546_leftLowOrHighBeamL "VCFRONT2 ECU: a546 left low or high beam light condition";
CM_ SG_ 834 VCFRONT2_a549_leftHeadlampIntern "VCFRONT2 ECU: a549 left headlamp internal error V3";
CM_ SG_ 834 VCFRONT2_a560_compressorHighSupe "VCFRONT2 ECU: a560 compressor high superheat";
CM_ SG_ 834 VCFRONT2_a563_chargePortDoorOpen "VCFRONT2 ECU: a563 charge port door open blocked by brake";
CM_ SG_ 834 VCFRONT2_a564_leftHeadlampAiming "VCFRONT2 ECU: a564 left headlamp aiming debug";
CM_ SG_ 834 VCFRONT2_a565_userPresenceDispla "VCFRONT2 ECU: a565 user presence display state mismatch";
CM_ SG_ 834 VCFRONT2_a566_leftFrontTurnLight "VCFRONT2 ECU: a566 left front turn light fault";
CM_ SG_ 834 VCFRONT2_a568_leftDaytimeRunning "VCFRONT2 ECU: a568 left daytime running light fault";
CM_ SG_ 834 VCFRONT2_a570_headlampsAdaptedTo "VCFRONT2 ECU: a570 headlamps adapted to left hand traffic";
CM_ SG_ 834 VCFRONT2_a571_headlampsAdaptedTo "VCFRONT2 ECU: a571 headlamps adapted to right hand traffic";
CM_ SG_ 834 VCFRONT2_a572_hvacCompressorEFus "VCFRONT2 ECU: a572 hvac compressor e fuse trip";
CM_ SG_ 834 VCFRONT2_a578_vbusFusedLowCurren "VCFRONT2 ECU: a578 vbus fused low current feed e fuse trip";
CM_ SG_ 834 VCFRONT2_a585_bothHeadlampsInter "VCFRONT2 ECU: a585 both headlamps internal error";
CM_ SG_ 834 VCFRONT2_a601_autopilotAirPurgeL "VCFRONT2 ECU: a601 autopilot air purge limit reached";
CM_ SG_ 834 VCFRONT2_a602_unknownTurnIndicat "VCFRONT2 ECU: a602 unknown turn indicator config";
CM_ SG_ 834 VCFRONT2_a603_unexpectedTurnIndi "VCFRONT2 ECU: a603 unexpected turn indicator config change";
CM_ SG_ 834 VCFRONT2_a604_turnIndicatorConfi "VCFRONT2 ECU: a604 turn indicator config input mismatch";
CM_ SG_ 834 VCFRONT2_a606_chillerBattHeating "VCFRONT2 ECU: a606 chiller batt heating exit";
CM_ SG_ 834 VCFRONT2_a610_driveEntryDelayed "VCFRONT2 ECU: a610 drive entry delayed";
CM_ SG_ 834 VCFRONT2_a611_poorRadiatorHeatRe "VCFRONT2 ECU: a611 poor radiator heat rejection";
CM_ SG_ 834 VCFRONT2_a612_selfTestsBlockingD "VCFRONT2 ECU: a612 self tests blocking drive";
CM_ SG_ 834 VCFRONT2_a614_coolantSysDriverle "VCFRONT2 ECU: a614 coolant sys driverless self test";
CM_ SG_ 834 VCFRONT2_a615_VCSEAT2L_MIA "VCFRONT2 ECU: a615 VCSEAT2 l MIA";
CM_ SG_ 834 VCFRONT2_a616_VCSEAT2R_MIA "VCFRONT2 ECU: a616 VCSEAT2 r MIA";
CM_ SG_ 834 VCFRONT2_a617_APP_MIA "VCFRONT2 ECU: a617 APP MIA";
CM_ SG_ 834 VCFRONT2_a618_cabinCoolingCapaci "VCFRONT2 ECU: a618 cabin cooling capacity limited";
CM_ SG_ 834 VCFRONT2_a620_pumpAirLock "VCFRONT2 ECU: a620 pump air lock";
CM_ SG_ 834 VCFRONT2_a621_coolantAirPurgeInc "VCFRONT2 ECU: a621 coolant air purge incomplete";
CM_ SG_ 834 VCFRONT2_a622_pumpDetectsLowCool "VCFRONT2 ECU: a622 pump detects low coolant flow";
CM_ SG_ 834 VCFRONT2_a625_leftHeadlampIntern "VCFRONT2 ECU: a625 left headlamp internal error V4";
CM_ SG_ 834 VCFRONT2_a630_leftHeadlampFactor "VCFRONT2 ECU: a630 left headlamp factory fault";
CM_ SG_ 834 VCFRONT2_d636_ptCoolantPumpDetec "VCFRONT2 ECU: d636 pt coolant pump detects air in system";
CM_ SG_ 834 VCFRONT2_d637_battCoolantPumpDet "VCFRONT2 ECU: d637 batt coolant pump detects air in system";
CM_ SG_ 834 VCFRONT2_d638_ptCoolantTempSenso "VCFRONT2 ECU: d638 pt coolant temp sensor issue";
CM_ SG_ 834 VCFRONT2_d639_batteryCoolantTemp "VCFRONT2 ECU: d639 battery coolant temp sensor issue";
CM_ SG_ 834 VCFRONT2_d640_firmwareVersionMis "VCFRONT2 ECU: d640 firmware version mismatch";
CM_ SG_ 834 VCFRONT2_d641_ptCoolantPumpCircu "VCFRONT2 ECU: d641 pt coolant pump circuit open";
CM_ SG_ 834 VCFRONT2_d642_batteryCoolantPump "VCFRONT2 ECU: d642 battery coolant pump circuit open";
CM_ SG_ 834 VCFRONT2_d647_louverCommLost "VCFRONT2 ECU: d647 louver comm lost";
CM_ SG_ 834 VCFRONT2_d648_louverBlocked "VCFRONT2 ECU: d648 louver blocked";
CM_ SG_ 834 VCFRONT2_d650_lowCoolantLevel "VCFRONT2 ECU: d650 low coolant level";
CM_ SG_ 834 VCFRONT2_d651_ptCoolantPumpStall "VCFRONT2 ECU: d651 pt coolant pump stall";
CM_ SG_ 834 VCFRONT2_d652_ptCoolantPumpCircu "VCFRONT2 ECU: d652 pt coolant pump circuit issue";
CM_ SG_ 834 VCFRONT2_d653_ptCoolantPumpCommL "VCFRONT2 ECU: d653 pt coolant pump comm lost";
CM_ SG_ 834 VCFRONT2_d654_batteryCoolantPump "VCFRONT2 ECU: d654 battery coolant pump stall";
CM_ SG_ 834 VCFRONT2_d655_batteryCoolantPump "VCFRONT2 ECU: d655 battery coolant pump circuit issue";
CM_ SG_ 834 VCFRONT2_d656_batteryCoolantPump "VCFRONT2 ECU: d656 battery coolant pump comm lost";
CM_ SG_ 834 VCFRONT2_d657_radiatorFanOperati "VCFRONT2 ECU: d657 radiator fan operation issue";
CM_ SG_ 834 VCFRONT2_d658_radiatorFanCircuit "VCFRONT2 ECU: d658 radiator fan circuit issue";
CM_ SG_ 834 VCFRONT2_d659_radiatorFanCommLos "VCFRONT2 ECU: d659 radiator fan comm lost";
CM_ SG_ 834 VCFRONT2_d660_coolantValveCircui "VCFRONT2 ECU: d660 coolant valve circuit issue";
CM_ SG_ 834 VCFRONT2_a661_mculessLeftHeadlam "VCFRONT2 ECU: a661 mculess left headlamp current alert dbg";
CM_ SG_ 834 VCFRONT2_a662_driveExitBlockedIn "VCFRONT2 ECU: a662 drive exit blocked indefinitely by self test request";
CM_ SG_ 834 VCFRONT2_a663_leftHeadlampUartWa "VCFRONT2 ECU: a663 left headlamp uart water mark warning";
CM_ SG_ 834 VCFRONT2_a665_leftHeadlampRetryI "VCFRONT2 ECU: a665 left headlamp retry info";
CM_ SG_ 834 VCFRONT2_a667_leftHeadlampRegion "VCFRONT2 ECU: a667 left headlamp region or side mismatch";
CM_ SG_ 834 VCFRONT2_a669_thermalHVPowerBudg "VCFRONT2 ECU: a669 thermal HV power budget active";
CM_ SG_ 834 VCFRONT2_a697_leftHeadlampNotAim "VCFRONT2 ECU: a697 left headlamp not aimed";
CM_ SG_ 834 VCFRONT2_a702_dynamicHeadlightLe "VCFRONT2 ECU: a702 dynamic headlight leveling unavailable";
CM_ BO_ 1583 "VCFRONT2 ECU message: uds response; frame length from the layout, not yet observed on a vehicle bus";
CM_ SG_ 1583 VCFRONT2_udsResponseData "VCFRONT2 ECU: uds response data";
CM_ BO_ 609 "Front body controller message: 12 v battery status; frame length observed on a vehicle bus";
CM_ SG_ 609 VCFRONT_12VBatteryStatusIndex "Front body controller: 12 v battery status index";
CM_ SG_ 609 VCFRONT_good12VforUpdate "Indicates the Low Voltage (LV) battery health as it pertains to permitting an Over-The-Air (OTA) update.";
CM_ SG_ 609 VCFRONT_LVLoadRequest "Controls the loading of the Low Voltage (LV) battery for diagnostic purposes.";
CM_ SG_ 609 VCFRONT_12VBatteryStatusCounter "Front body controller: 12 v battery status counter";
CM_ SG_ 609 VCFRONT_12VBatteryStatusChecksum "Front body controller: 12 v battery status checksum";
CM_ SG_ 609 VCFRONT_batterySupportRequest "Reports the request to the Power Conversion System (PCS) to supply power to the Low Voltage (LV) battery.";
CM_ SG_ 609 VCFRONT_batterySMState "Reports the Low Voltage (LV) battery maintenance state machine state.";
CM_ SG_ 609 VCFRONT_eFuseRecoveryStateDBG "Reports the state of the Low Voltage (LV) battery eFuse recovery state machine.";
CM_ SG_ 609 VCFRONT_batteryLINScheduleDBG "Front body controller: battery LIN schedule DBG; raw 7 = signal not available (SNA)";
CM_ SG_ 609 VCFRONT_resistanceEstimationTest "Front body controller: resistance estimation test counter";
CM_ SG_ 609 VCFRONT_IBSCurrent "Electrical current into the 12V battery";
CM_ SG_ 609 VCFRONT_IBSVoltage "Voltage of the 12V battery; raw 4095 = signal not available (SNA)";
CM_ SG_ 609 VCFRONT_reverseBatteryFault "Indicates a fault on the reverse battery eFuse.";
CM_ SG_ 609 VCFRONT_LVBatterySupported "Indicates whether the Low Voltage (LV) battery is being supported.";
CM_ SG_ 609 VCFRONT_LVBatteryCannotSupportVe "Front body controller: LV battery cannot support vehicle";
CM_ SG_ 609 VCFRONT_goodTemp12VforUpdate "Front body controller: good temp12 vfor update";
CM_ SG_ 609 VCFRONT_12VBatteryTargetVoltage "Reports the target Low Voltage (LV) battery voltage.";
CM_ SG_ 609 VCFRONT_IBSTemperature "Front body controller: IBS temperature; raw 2047 = signal not available (SNA)";
CM_ SG_ 609 VCFRONT_currentSensorMismatchLea "Front body controller: current sensor mismatch leaky bkt pct DBG";
CM_ SG_ 609 VCFRONT_LVBatteryEnergyRemaining "Reports the percentage of energy remaining in the Low Voltage (LV) battery.";
CM_ SG_ 609 VCFRONT_LVBatteryStatusForDrive "Indicates the Low Voltage (LV) battery health status as it pertains to drive readiness. May trigger a Graceful Power Off (GPO) and block drive.";
CM_ SG_ 609 VCFRONT_LVBatteryType "Reports the type of Low Voltage (LV) battery that the firmware is configured for.";
CM_ SG_ 609 VCFRONT_resistanceEstimationNeed "Indication that the conditions which require a resistance estimation test to be performed have been met";
CM_ SG_ 609 VCFRONT_IBSVoltageFiltered "Measures the filtered voltage of the Low Voltage (LV) bus; raw 16383 = signal not available (SNA)";
CM_ SG_ 609 VCFRONT_LVBMS_LVBusVoltageSource "Reports the source of the Low Voltage (LV) bus voltage used for the Low Voltage Battery Management System (LVBMS).";
CM_ SG_ 609 VCFRONT_LVBMS_LVPackCurrentSourc "Reports the source of the Low Voltage (LV) pack current used for LV battery charge regulation.";
CM_ SG_ 609 VCFRONT_LVBatterySupportRqrdTrig "Reports what caused the Low Voltage (LV) battery support required trigger when the vehicle wakes to charge.";
CM_ SG_ 609 VCFRONT_goodForPCSPowerCycleLeak "Front body controller: good for PCS power cycle leaky bkt DBG";
CM_ SG_ 609 VCFRONT_LVBusControlsFutile "Indicates that a required condition is not met for the Low Voltage (LV) bus controllers to operate properly.";
CM_ SG_ 609 VCFRONT_resistanceEstimatio_0001 "Front body controller: resistance estimation test valid";
CM_ SG_ 609 VCFRONT_resistanceEstimatio_0002 "Front body controller: resistance estimation tests expended";
CM_ SG_ 609 VCFRONT_goodLVChargeForUpdate "Indicates that the Low Voltage (LV) battery charge is sufficient to permit an Over-The-Air (OTA) update.";
CM_ SG_ 609 VCFRONT_opportunisticDCRTestNeed "Front body controller: opportunistic DCR test needed";
CM_ SG_ 609 VCFRONT_voltageProfile "Indicates which voltage profile is used to support the 12V battery";
CM_ SG_ 609 VCFRONT_IBSAmpHours "Measures the energy state of the Low Voltage (LV) battery in amp hours.";
CM_ SG_ 609 VCFRONT_IBSVoltageRawDBG "Front body controller: IBS voltage raw DBG; raw 16383 = signal not available (SNA)";
CM_ SG_ 609 VCFRONT_LVBatteryLINCommsDetecte "Front body controller: LV battery LIN comms detected DBG";
CM_ SG_ 609 VCFRONT_voltageSensorMismatchLea "Front body controller: voltage sensor mismatch leaky bkt pct DBG";
CM_ SG_ 609 VCFRONT_LVBusControlMode "Front body controller: LV bus control mode";
CM_ SG_ 609 VCFRONT_resistanceEstimationExte "Front body controller: resistance estimation extended test enabled";
CM_ SG_ 609 VCFRONT_LVBatteryFctryLimOverrid "Front body controller: LV battery fctry lim override ok";
CM_ SG_ 609 VCFRONT_LVBatterySPICommsDetecte "Front body controller: LV battery SPI comms detected DBG";
CM_ SG_ 609 VCFRONT_targetCurrent "Reports the target current set by the Low Voltage Battery Management System (LVBMS).";
CM_ SG_ 609 VCFRONT_PCSMia "Indicates that the Power Conversion System (PCS) is not communicating on CAN.";
CM_ SG_ 609 VCFRONT_chargeNeeded "Indicates that the Low Voltage (LV) battery needs to be charged.";
CM_ SG_ 609 VCFRONT_voltageControlLoopIntegr "Front body controller: voltage control loop integration val";
CM_ SG_ 609 VCFRONT_currentControlLoopIntegr "Front body controller: current control loop integration val";
CM_ BO_ 1847 "Front body controller message: LVBMS info; frame length observed on a vehicle bus";
CM_ SG_ 1847 VCFRONT_LVBMS_InfoIndex "Front body controller: LVBMS info index";
CM_ SG_ 1847 VCFRONT_LVBMS_PcbaId "Front body controller: LVBMS pcba id";
CM_ SG_ 1847 VCFRONT_LVBMS_AssemblyId "Front body controller: LVBMS assembly id";
CM_ SG_ 1847 VCFRONT_LVBMS_SubUsageId "LVBMS Sub Usage ID; raw 65535 = signal not available (SNA)";
CM_ SG_ 1847 VCFRONT_LVBMS_UsageId "Front body controller: LVBMS usage id";
CM_ SG_ 1847 VCFRONT_LVBMS_AppCRC "LVBMS application cyclic redundancy check";
CM_ SG_ 1847 VCFRONT_LVBMS_FWBuildType "Front body controller: LVBMS FW build type";
CM_ BO_ 1140 "Front body controller message: LV health; frame length from the layout, not yet observed on a vehicle bus";
CM_ SG_ 1140 VCFRONT_LVHealthChecksum "Front body controller: LV health checksum";
CM_ SG_ 1140 VCFRONT_LVHealthCounter "Front body controller: LV health counter";
CM_ SG_ 1140 VCFRONT_LVHealthStatus "Health status of the LV system";
CM_ SG_ 1140 VCFRONT_LVStatusForDrive "Front body controller: LV status for drive";
CM_ SG_ 1140 VCFRONT_LVPowerSecondsToSafeHarb "Reports the amount of time (in seconds) the Low Voltage (LV) power system indicates the vehicle has to achieve safe harbor.";
CM_ SG_ 1140 VCFRONT_hardwareProtectionsArmed "Front body controller: hardware protections armed";
CM_ SG_ 1140 VCFRONT_lockoutStrategy "Front body controller: lockout strategy";
CM_ BO_ 1173 "Front body controller message: LV health debug; frame length from the layout, not yet observed on a vehicle bus";
CM_ SG_ 1173 VCFRONT_LVHealthDebugIndex "Front body controller: LV health debug index";
CM_ SG_ 1173 VCFRONT_LVHEALTH_placeholder "Whether the LV health has determined that the <placeholder>";
CM_ SG_ 1173 VCFRONT_LVHEALTH_activeDecelEner "Whether the VCFRONT cannot confirm that the battery has sufficient energy to support an active decel scenario";
CM_ SG_ 1173 VCFRONT_LVHEALTH_criticalPullove "Whether the VCFRONT cannot confirm that the battery has sufficient energy to support a critical pullover scenario";
CM_ SG_ 1173 VCFRONT_LVHEALTH_revBattEFuseOff "Whether the LV health has determined that the LVBMB EFuse has opened";
CM_ SG_ 1173 VCFRONT_LVHEALTH_LVBMBEFuseOpen "Whether the LV health has determined that the LVBMB EFuse has opened";
CM_ SG_ 1173 VCFRONT_LVHEALTH_lvBatteryCommsM "Whether the LV health has determined that LV battery communications are missing";
CM_ SG_ 1173 VCFRONT_LVHEALTH_pcsEFuseOff "Whether VCFRONT has determined that the PCS eFuse is off or faulted when it's needed to be on";
CM_ SG_ 1173 VCFRONT_LVHEALTH_pcsNotActive "Whether the LV health has determined that the PCS is not actively providing LV support";
CM_ SG_ 1173 VCFRONT_LVHEALTH_pcsMIA "Whether the LV health has determined that messages are missing from PCS critical for determining health";
CM_ SG_ 1173 VCFRONT_LVHEALTH_IBSMIA "Whether the LV health has determined that the INA228 LV battery sensor signals are invalid or not yet configured";
CM_ SG_ 1173 VCFRONT_LVHEALTH_LVBatteryElecDi "Whether the VCFRONT has determined that the LV battery is electrically disconnected";
CM_ SG_ 1173 VCFRONT_LVHEALTH_LVBatteryE_0001 "Whether the VCFRONT has determined that the LV battery electrical connection status has been unknown for too long";
CM_ SG_ 1173 VCFRONT_LVHEALTH_pcsOpenCircuit "Whether VCFRONT has determined that the electrical connection between the PCS and VCFRONT is disconnected";
CM_ SG_ 1173 VCFRONT_LVHEALTH_activeDecelPowe "Whether the VCFRONT cannot confirm that the battery has sufficient power to support a active decel scenario";
CM_ SG_ 1173 VCFRONT_LVHEALTH_lvBatteryCapabi "Whether the LV health has determined that LV battery power/energy capability estimation accuracy is too low";
CM_ SG_ 1173 VCFRONT_LVHEALTH_lvBatteryConfig "Whether the LV health has determined that LV battery configuration is incorrect";
CM_ SG_ 1173 VCFRONT_LVHEALTH_lvBatteryImpeda "Whether the LV health has determined that LV battery impedance is too high";
CM_ SG_ 1173 VCFRONT_LVHEALTH_lvBatteryExtend "Whether the LV health has determined that an extended over voltage event has occurred";
BA_DEF_ BO_ "GenMsgCycleTime" INT 0 3600000;
BA_DEF_ BO_ "GenMsgSendType" ENUM "Cyclic","NotUsed","NotUsed","NotUsed","NotUsed","NotUsed","NotUsed","IfActive","NoMsgSendType","NotUsed";
BA_DEF_ BO_ "VFrameFormat" ENUM "StandardCAN","ExtendedCAN","reserved","J1939PG","reserved","reserved","reserved","reserved","reserved","reserved","reserved","reserved","reserved","reserved","StandardCAN_FD","ExtendedCAN_FD";
BA_DEF_ BO_ "CANFD_BRS" ENUM "0","1";
BA_DEF_ SG_ "GenSigSNA" STRING;
BA_DEF_ SG_ "SystemSignalLongSymbol" STRING;
BA_DEF_ SG_ "Confidence" ENUM "validated","plausible","layout-only","contradicted";
BA_DEF_DEF_ "GenMsgCycleTime" 0;
BA_DEF_DEF_ "GenMsgSendType" "NoMsgSendType";
BA_DEF_DEF_ "VFrameFormat" "StandardCAN";
BA_DEF_DEF_ "CANFD_BRS" "1";
BA_DEF_DEF_ "GenSigSNA" "";
BA_DEF_DEF_ "SystemSignalLongSymbol" "";
BA_DEF_DEF_ "Confidence" "layout-only";
BA_ "GenMsgCycleTime" BO_ 834 100;
BA_ "GenMsgSendType" BO_ 834 0;
BA_ "GenMsgCycleTime" BO_ 609 16;
BA_ "GenMsgSendType" BO_ 609 0;
BA_ "GenMsgCycleTime" BO_ 1847 1000;
BA_ "GenMsgSendType" BO_ 1847 0;
BA_ "GenMsgCycleTime" BO_ 1140 100;
BA_ "GenMsgSendType" BO_ 1140 0;
BA_ "GenMsgCycleTime" BO_ 1173 1000;
BA_ "GenMsgSendType" BO_ 1173 0;
BA_ "Confidence" SG_ 1351 VCFRONT2_alertID 1;
BA_ "Confidence" SG_ 1351 VCFRONT2_alertState 1;
BA_ "SystemSignalLongSymbol" SG_ 1351 VCFRONT2_a015_NVMMFilesystemErro "VCFRONT2_a015_NVMMFilesystemError";
BA_ "Confidence" SG_ 1351 VCFRONT2_a059_voltageDrop 1;
BA_ "Confidence" SG_ 1351 VCFRONT2_a059_resistanceEstimate 1;
BA_ "Confidence" SG_ 1351 VCFRONT2_a059_current 1;
BA_ "Confidence" SG_ 1351 VCFRONT2_a063_ADCVoltage 1;
BA_ "SystemSignalLongSymbol" SG_ 1351 VCFRONT2_a091_FRONTIPC_faultsAnd "VCFRONT2_a091_FRONTIPC_faultsAndExtras";
BA_ "SystemSignalLongSymbol" SG_ 1351 VCFRONT2_a098_FRONTIPC_temperatu "VCFRONT2_a098_FRONTIPC_temperature";
BA_ "SystemSignalLongSymbol" SG_ 1351 VCFRONT2_a098_FRONTIPC_thermalCo "VCFRONT2_a098_FRONTIPC_thermalControl";
BA_ "SystemSignalLongSymbol" SG_ 1351 VCFRONT2_a106_BATTIPC_dcdcRailSt "VCFRONT2_a106_BATTIPC_dcdcRailStatus";
BA_ "SystemSignalLongSymbol" SG_ 1351 VCFRONT2_a106_FRONTIPC_thermalCo "VCFRONT2_a106_FRONTIPC_thermalControl";
BA_ "SystemSignalLongSymbol" SG_ 1351 VCFRONT2_a106_FRONTIPC_dcdcRailS "VCFRONT2_a106_FRONTIPC_dcdcRailStatus";
BA_ "SystemSignalLongSymbol" SG_ 1351 VCFRONT2_a106_FRONTIPC_dcdcStatu "VCFRONT2_a106_FRONTIPC_dcdcStatus";
BA_ "SystemSignalLongSymbol" SG_ 1351 VCFRONT2_a108_FRONTIPC_temperatu "VCFRONT2_a108_FRONTIPC_temperature";
BA_ "SystemSignalLongSymbol" SG_ 1351 VCFRONT2_a108_FRONTIPC_thermalCo "VCFRONT2_a108_FRONTIPC_thermalControl";
BA_ "SystemSignalLongSymbol" SG_ 1351 VCFRONT2_a108_FRONTIPC_motorStat "VCFRONT2_a108_FRONTIPC_motorStatus";
BA_ "SystemSignalLongSymbol" SG_ 1351 VCFRONT2_a120_FRONTIPC_systemSta "VCFRONT2_a120_FRONTIPC_systemStatus";
BA_ "SystemSignalLongSymbol" SG_ 1351 VCFRONT2_a120_BATTIPC_systemStat "VCFRONT2_a120_BATTIPC_systemStatus";
BA_ "SystemSignalLongSymbol" SG_ 1351 VCFRONT2_a120_FRONTIPC_systemPow "VCFRONT2_a120_FRONTIPC_systemPower";
BA_ "SystemSignalLongSymbol" SG_ 1351 VCFRONT2_a120_FRONTIPC_autonomyH "VCFRONT2_a120_FRONTIPC_autonomyHealth";
BA_ "SystemSignalLongSymbol" SG_ 1351 VCFRONT2_a120_BATTIPC_chassisCon "VCFRONT2_a120_BATTIPC_chassisControl2";
BA_ "SystemSignalLongSymbol" SG_ 1351 VCFRONT2_a120_FRONTIPC_chassisCo "VCFRONT2_a120_FRONTIPC_chassisControl2";
BA_ "SystemSignalLongSymbol" SG_ 1351 VCFRONT2_a120_FRONTIPC_odometerS "VCFRONT2_a120_FRONTIPC_odometerStatus";
BA_ "SystemSignalLongSymbol" SG_ 1351 VCFRONT2_a125_FRONTIPC_steerAngl "VCFRONT2_a125_FRONTIPC_steerAngle";
BA_ "SystemSignalLongSymbol" SG_ 1351 VCFRONT2_a133_BATTIPC_primaryAct "VCFRONT2_a133_BATTIPC_primaryActuator";
BA_ "SystemSignalLongSymbol" SG_ 1351 VCFRONT2_a133_FRONTIPC_secondary "VCFRONT2_a133_FRONTIPC_secondaryActuator";
BA_ "Confidence" SG_ 1351 VCFRONT2_a142_driverState 1;
BA_ "SystemSignalLongSymbol" SG_ 1351 VCFRONT2_a142_driverThermShutdow "VCFRONT2_a142_driverThermShutdown";
BA_ "SystemSignalLongSymbol" SG_ 1351 VCFRONT2_a142_chargePumpUndervol "VCFRONT2_a142_chargePumpUndervoltage";
BA_ "Confidence" SG_ 1351 VCFRONT2_a150_RPMActual 1;
BA_ "Confidence" SG_ 1351 VCFRONT2_a150_RPMTarget 1;
BA_ "Confidence" SG_ 1351 VCFRONT2_a159_angleActual 1;
BA_ "Confidence" SG_ 1351 VCFRONT2_a159_angleTarget 1;
BA_ "Confidence" SG_ 1351 VCFRONT2_a176_vehicleState 1;
BA_ "SystemSignalLongSymbol" SG_ 1351 VCFRONT2_a186_noDriveChgCableCon "VCFRONT2_a186_noDriveChgCableConX";
BA_ "Confidence" SG_ 1351 VCFRONT2_a195_LVVoltage 1;
BA_ "SystemSignalLongSymbol" SG_ 1351 VCFRONT2_a214_hardwareOvercurren "VCFRONT2_a214_hardwareOvercurrent";
BA_ "Confidence" SG_ 1351 VCFRONT2_a214_selfTestResult 1;
BA_ "SystemSignalLongSymbol" SG_ 1351 VCFRONT2_a214_busVoltageIrration "VCFRONT2_a214_busVoltageIrrational";
BA_ "SystemSignalLongSymbol" SG_ 1351 VCFRONT2_a214_dcCurrentIrrationa "VCFRONT2_a214_dcCurrentIrrational";
BA_ "SystemSignalLongSymbol" SG_ 1351 VCFRONT2_a214_motorSpeedIrration "VCFRONT2_a214_motorSpeedIrrational";
BA_ "SystemSignalLongSymbol" SG_ 1351 VCFRONT2_a214_supplyVoltageIrrat "VCFRONT2_a214_supplyVoltageIrrational";
BA_ "SystemSignalLongSymbol" SG_ 1351 VCFRONT2_a214_motorPhaseCurrentI "VCFRONT2_a214_motorPhaseCurrentIrrational";
BA_ "SystemSignalLongSymbol" SG_ 1351 VCFRONT2_a214_busVoltageUnhealth "VCFRONT2_a214_busVoltageUnhealthy";
BA_ "SystemSignalLongSymbol" SG_ 1351 VCFRONT2_a214_hsVdsOvervoltageMa "VCFRONT2_a214_hsVdsOvervoltageMask";
BA_ "SystemSignalLongSymbol" SG_ 1351 VCFRONT2_a214_lsVdsOvervoltageMa "VCFRONT2_a214_lsVdsOvervoltageMask";
BA_ "SystemSignalLongSymbol" SG_ 1351 VCFRONT2_a217_hardwareOvercurren "VCFRONT2_a217_hardwareOvercurrent";
BA_ "Confidence" SG_ 1351 VCFRONT2_a217_selfTestResult 1;
BA_ "SystemSignalLongSymbol" SG_ 1351 VCFRONT2_a217_busVoltageIrration "VCFRONT2_a217_busVoltageIrrational";
BA_ "SystemSignalLongSymbol" SG_ 1351 VCFRONT2_a217_dcCurrentIrrationa "VCFRONT2_a217_dcCurrentIrrational";
BA_ "SystemSignalLongSymbol" SG_ 1351 VCFRONT2_a217_motorSpeedIrration "VCFRONT2_a217_motorSpeedIrrational";
BA_ "SystemSignalLongSymbol" SG_ 1351 VCFRONT2_a217_supplyVoltageIrrat "VCFRONT2_a217_supplyVoltageIrrational";
BA_ "SystemSignalLongSymbol" SG_ 1351 VCFRONT2_a217_motorPhaseCurrentI "VCFRONT2_a217_motorPhaseCurrentIrrational";
BA_ "SystemSignalLongSymbol" SG_ 1351 VCFRONT2_a217_busVoltageUnhealth "VCFRONT2_a217_busVoltageUnhealthy";
BA_ "SystemSignalLongSymbol" SG_ 1351 VCFRONT2_a217_hsVdsOvervoltageMa "VCFRONT2_a217_hsVdsOvervoltageMask";
BA_ "SystemSignalLongSymbol" SG_ 1351 VCFRONT2_a217_lsVdsOvervoltageMa "VCFRONT2_a217_lsVdsOvervoltageMask";
BA_ "Confidence" SG_ 1351 VCFRONT2_a235_ptSensorTemp 1;
BA_ "Confidence" SG_ 1351 VCFRONT2_a236_batSensorTemp 1;
BA_ "Confidence" SG_ 1351 VCFRONT2_a247_solenoidISense 1;
BA_ "Confidence" SG_ 1351 VCFRONT2_a249_tempCoolantBatInle 1;
BA_ "SystemSignalLongSymbol" SG_ 1351 VCFRONT2_a249_tempCoolantBatInle "VCFRONT2_a249_tempCoolantBatInlet";
BA_ "Confidence" SG_ 1351 VCFRONT2_a249_tempCoolantPTInlet 1;
BA_ "Confidence" SG_ 1351 VCFRONT2_a254_RPMActual 1;
BA_ "Confidence" SG_ 1351 VCFRONT2_a254_RPMTarget 1;
BA_ "Confidence" SG_ 1351 VCFRONT2_a283_thmlFanDemand 1;
BA_ "Confidence" SG_ 1351 VCFRONT2_a283_thmlFanDemandLimit 1;
BA_ "Confidence" SG_ 1351 VCFRONT2_a283_thmlFanPhaseI 1;
BA_ "Confidence" SG_ 1351 VCFRONT2_a283_thmlFanPhaseILimit 1;
BA_ "Confidence" SG_ 1351 VCFRONT2_a284_driverState 1;
BA_ "SystemSignalLongSymbol" SG_ 1351 VCFRONT2_a284_driverThermShutdow "VCFRONT2_a284_driverThermShutdown";
BA_ "SystemSignalLongSymbol" SG_ 1351 VCFRONT2_a284_chargePumpUndervol "VCFRONT2_a284_chargePumpUndervoltage";
BA_ "Confidence" SG_ 1351 VCFRONT2_a285_driverState 1;
BA_ "SystemSignalLongSymbol" SG_ 1351 VCFRONT2_a285_driverThermShutdow "VCFRONT2_a285_driverThermShutdown";
BA_ "SystemSignalLongSymbol" SG_ 1351 VCFRONT2_a285_chargePumpUndervol "VCFRONT2_a285_chargePumpUndervoltage";
BA_ "Confidence" SG_ 1351 VCFRONT2_a286_driverState 1;
BA_ "SystemSignalLongSymbol" SG_ 1351 VCFRONT2_a286_driverThermShutdow "VCFRONT2_a286_driverThermShutdown";
BA_ "SystemSignalLongSymbol" SG_ 1351 VCFRONT2_a286_chargePumpUndervol "VCFRONT2_a286_chargePumpUndervoltage";
BA_ "Confidence" SG_ 1351 VCFRONT2_a287_driverState 1;
BA_ "SystemSignalLongSymbol" SG_ 1351 VCFRONT2_a287_driverThermShutdow "VCFRONT2_a287_driverThermShutdown";
BA_ "SystemSignalLongSymbol" SG_ 1351 VCFRONT2_a287_chargePumpUndervol "VCFRONT2_a287_chargePumpUndervoltage";
BA_ "Confidence" SG_ 1351 VCFRONT2_a288_driverState 1;
BA_ "SystemSignalLongSymbol" SG_ 1351 VCFRONT2_a288_driverThermShutdow "VCFRONT2_a288_driverThermShutdown";
BA_ "SystemSignalLongSymbol" SG_ 1351 VCFRONT2_a288_chargePumpUndervol "VCFRONT2_a288_chargePumpUndervoltage";
BA_ "Confidence" SG_ 1351 VCFRONT2_a289_driverState 1;
BA_ "SystemSignalLongSymbol" SG_ 1351 VCFRONT2_a289_driverThermShutdow "VCFRONT2_a289_driverThermShutdown";
BA_ "SystemSignalLongSymbol" SG_ 1351 VCFRONT2_a289_chargePumpUndervol "VCFRONT2_a289_chargePumpUndervoltage";
BA_ "Confidence" SG_ 1351 VCFRONT2_a302_LINFrameStatus 1;
BA_ "SystemSignalLongSymbol" SG_ 1351 VCFRONT2_a355_systemNotCommissio "VCFRONT2_a355_systemNotCommissioned";
BA_ "SystemSignalLongSymbol" SG_ 1351 VCFRONT2_a356_systemNotCommissio "VCFRONT2_a356_systemNotCommissioned";
BA_ "SystemSignalLongSymbol" SG_ 1351 VCFRONT2_a356_refCommissionStatu "VCFRONT2_a356_refCommissionStatus";
BA_ "SystemSignalLongSymbol" SG_ 1351 VCFRONT2_a360_vehicleLoadShedAct "VCFRONT2_a360_vehicleLoadShedActive";
BA_ "SystemSignalLongSymbol" SG_ 1351 VCFRONT2_a360_notEnoughPowerForS "VCFRONT2_a360_notEnoughPowerForSupport";
BA_ "Confidence" SG_ 1351 VCFRONT2_a367_bmsSoc 1;
BA_ "Confidence" SG_ 1351 VCFRONT2_a368_enteringState 1;
BA_ "Confidence" SG_ 1351 VCFRONT2_a368_exitingState 1;
BA_ "Confidence" SG_ 1351 VCFRONT2_a368_bmsSoc 1;
BA_ "SystemSignalLongSymbol" SG_ 1351 VCFRONT2_a368_coolantTempSensors "VCFRONT2_a368_coolantTempSensorsFaulted";
BA_ "SystemSignalLongSymbol" SG_ 1351 VCFRONT2_a368_coolantValveFaulte "VCFRONT2_a368_coolantValveFaulted";
BA_ "SystemSignalLongSymbol" SG_ 1351 VCFRONT2_a368_coolantPumpsFaulte "VCFRONT2_a368_coolantPumpsFaulted";
BA_ "SystemSignalLongSymbol" SG_ 1351 VCFRONT2_a368_preconditionsNotMe "VCFRONT2_a368_preconditionsNotMet";
BA_ "SystemSignalLongSymbol" SG_ 1351 VCFRONT2_a369_powerGenerationLim "VCFRONT2_a369_powerGenerationLimited";
BA_ "SystemSignalLongSymbol" SG_ 1351 VCFRONT2_a369_heatRejectionLimit "VCFRONT2_a369_heatRejectionLimited";
BA_ "Confidence" SG_ 1351 VCFRONT2_a369_bmsSoc 1;
BA_ "Confidence" SG_ 1351 VCFRONT2_a369_wasteHeatPower 1;
BA_ "Confidence" SG_ 1351 VCFRONT2_a374_lccInletSolenoidIS 1;
BA_ "SystemSignalLongSymbol" SG_ 1351 VCFRONT2_a374_lccInletSolenoidIS "VCFRONT2_a374_lccInletSolenoidISense";
BA_ "SystemSignalLongSymbol" SG_ 1351 VCFRONT2_a377_wiperStuckOutOfPar "VCFRONT2_a377_wiperStuckOutOfPark";
BA_ "Confidence" SG_ 1351 VCFRONT2_a397_offsetError 1;
BA_ "SystemSignalLongSymbol" SG_ 1351 VCFRONT2_a397_runTimeOffSetDetec "VCFRONT2_a397_runTimeOffSetDetected";
BA_ "SystemSignalLongSymbol" SG_ 1351 VCFRONT2_a409_brushlessMotorConf "VCFRONT2_a409_brushlessMotorConfigurationInvalid";
BA_ "SystemSignalLongSymbol" SG_ 1351 VCFRONT2_a446_compFaultRefrigera "VCFRONT2_a446_compFaultRefrigerant";
BA_ "SystemSignalLongSymbol" SG_ 1351 VCFRONT2_a446_compStandbyLowAmbi "VCFRONT2_a446_compStandbyLowAmbient";
BA_ "SystemSignalLongSymbol" SG_ 1351 VCFRONT2_a446_compStandbyLowDisc "VCFRONT2_a446_compStandbyLowDischPress";
BA_ "SystemSignalLongSymbol" SG_ 1351 VCFRONT2_a446_compStandbyHVNotRe "VCFRONT2_a446_compStandbyHVNotReady";
BA_ "SystemSignalLongSymbol" SG_ 1351 VCFRONT2_a446_compStandbyCommuni "VCFRONT2_a446_compStandbyCommunication";
BA_ "SystemSignalLongSymbol" SG_ 1351 VCFRONT2_a446_compStandbySelfNot "VCFRONT2_a446_compStandbySelfNotReady";
BA_ "SystemSignalLongSymbol" SG_ 1351 VCFRONT2_a446_compStandbyRefrigN "VCFRONT2_a446_compStandbyRefrigNotOk";
BA_ "SystemSignalLongSymbol" SG_ 1351 VCFRONT2_a446_compStandbyCoastDo "VCFRONT2_a446_compStandbyCoastDownMode";
BA_ "SystemSignalLongSymbol" SG_ 1351 VCFRONT2_a446_compStandbyMultipl "VCFRONT2_a446_compStandbyMultiplePdCutouts";
BA_ "SystemSignalLongSymbol" SG_ 1351 VCFRONT2_a446_compStandbyShowroo "VCFRONT2_a446_compStandbyShowroomMode";
BA_ "SystemSignalLongSymbol" SG_ 1351 VCFRONT2_a446_compStandbyMu_0001 "VCFRONT2_a446_compStandbyMultipleTdCutouts";
BA_ "Confidence" SG_ 1351 VCFRONT2_a446_hpCabinLoadType 1;
BA_ "Confidence" SG_ 1351 VCFRONT2_a446_hpBatteryLoadType 1;
BA_ "SystemSignalLongSymbol" SG_ 1351 VCFRONT2_a446_sensorIntermi_0002 "VCFRONT2_a446_sensorIntermittentPs";
BA_ "SystemSignalLongSymbol" SG_ 1351 VCFRONT2_a446_sensorIntermittent "VCFRONT2_a446_sensorIntermittentPd";
BA_ "SystemSignalLongSymbol" SG_ 1351 VCFRONT2_a446_sensorIntermi_0001 "VCFRONT2_a446_sensorIntermittentPl";
BA_ "SystemSignalLongSymbol" SG_ 1351 VCFRONT2_a446_sensorIntermi_0005 "VCFRONT2_a446_sensorIntermittentTs";
BA_ "SystemSignalLongSymbol" SG_ 1351 VCFRONT2_a446_sensorIntermi_0003 "VCFRONT2_a446_sensorIntermittentTd";
BA_ "SystemSignalLongSymbol" SG_ 1351 VCFRONT2_a446_sensorIntermi_0004 "VCFRONT2_a446_sensorIntermittentTl";
BA_ "SystemSignalLongSymbol" SG_ 1351 VCFRONT2_a446_highSuctionSuperhe "VCFRONT2_a446_highSuctionSuperheat";
BA_ "SystemSignalLongSymbol" SG_ 1351 VCFRONT2_a446_coolantSysLockedOu "VCFRONT2_a446_coolantSysLockedOut";
BA_ "SystemSignalLongSymbol" SG_ 1351 VCFRONT2_a447_caseHVACUnavailabl "VCFRONT2_a447_caseHVACUnavailable";
BA_ "SystemSignalLongSymbol" SG_ 1351 VCFRONT2_a447_heatPumpHVACUnavai "VCFRONT2_a447_heatPumpHVACUnavailable";
BA_ "SystemSignalLongSymbol" SG_ 1351 VCFRONT2_a447_activeLouverCompro "VCFRONT2_a447_activeLouverCompromised";
BA_ "SystemSignalLongSymbol" SG_ 1351 VCFRONT2_a447_coolantValveCompro "VCFRONT2_a447_coolantValveCompromised";
BA_ "SystemSignalLongSymbol" SG_ 1351 VCFRONT2_a447_ambientSourcingCom "VCFRONT2_a447_ambientSourcingCompromised";
BA_ "SystemSignalLongSymbol" SG_ 1351 VCFRONT2_a447_scavengeLoopCompro "VCFRONT2_a447_scavengeLoopCompromised";
BA_ "SystemSignalLongSymbol" SG_ 1351 VCFRONT2_a447_coolantSystemCompr "VCFRONT2_a447_coolantSystemCompromised";
BA_ "SystemSignalLongSymbol" SG_ 1351 VCFRONT2_a447_hvBattActiveDischg "VCFRONT2_a447_hvBattActiveDischgCompromised";
BA_ "SystemSignalLongSymbol" SG_ 1351 VCFRONT2_a447_hvBatteryDischargi "VCFRONT2_a447_hvBatteryDischargingCompromised";
BA_ "SystemSignalLongSymbol" SG_ 1351 VCFRONT2_a447_lccSolenoidComprom "VCFRONT2_a447_lccSolenoidCompromised";
BA_ "SystemSignalLongSymbol" SG_ 1351 VCFRONT2_a447_refrigerantSystemC "VCFRONT2_a447_refrigerantSystemCompromised";
BA_ "SystemSignalLongSymbol" SG_ 1351 VCFRONT2_a447_powertrainThermalF "VCFRONT2_a447_powertrainThermalFansCompromised";
BA_ "SystemSignalLongSymbol" SG_ 1351 VCFRONT2_a447_refrigDischargePre "VCFRONT2_a447_refrigDischargePressCompromised";
BA_ "SystemSignalLongSymbol" SG_ 1351 VCFRONT2_a447_refrigeDischargeTe "VCFRONT2_a447_refrigeDischargeTempCompromised";
BA_ "SystemSignalLongSymbol" SG_ 1351 VCFRONT2_a447_refrigSuctionPress "VCFRONT2_a447_refrigSuctionPressCompromised";
BA_ "SystemSignalLongSymbol" SG_ 1351 VCFRONT2_a447_refrigSuctionTempC "VCFRONT2_a447_refrigSuctionTempCompromised";
BA_ "SystemSignalLongSymbol" SG_ 1351 VCFRONT2_a447_refrigLiquidPressC "VCFRONT2_a447_refrigLiquidPressCompromised";
BA_ "SystemSignalLongSymbol" SG_ 1351 VCFRONT2_a447_refrigLiquidTempCo "VCFRONT2_a447_refrigLiquidTempCompromised";
BA_ "SystemSignalLongSymbol" SG_ 1351 VCFRONT2_a459_refrigerantFillAct "VCFRONT2_a459_refrigerantFillActive";
BA_ "Confidence" SG_ 1351 VCFRONT2_a464_flowIndex 1;
BA_ "Confidence" SG_ 1351 VCFRONT2_a464_flowIndexFiltered 1;
BA_ "Confidence" SG_ 1351 VCFRONT2_a464_subcool 1;
BA_ "Confidence" SG_ 1351 VCFRONT2_a464_subcoolFiltered 1;
BA_ "Confidence" SG_ 1351 VCFRONT2_a465_flowIndex 1;
BA_ "Confidence" SG_ 1351 VCFRONT2_a465_flowIndexFiltered 1;
BA_ "Confidence" SG_ 1351 VCFRONT2_a465_subcool 1;
BA_ "Confidence" SG_ 1351 VCFRONT2_a465_subcoolFiltered 1;
BA_ "SystemSignalLongSymbol" SG_ 1351 VCFRONT2_a465_flaggedAtSteadySta "VCFRONT2_a465_flaggedAtSteadyState";
BA_ "SystemSignalLongSymbol" SG_ 1351 VCFRONT2_a465_flaggedAtUnsteadyS "VCFRONT2_a465_flaggedAtUnsteadyState";
BA_ "Confidence" SG_ 1351 VCFRONT2_a466_flowIndex 1;
BA_ "Confidence" SG_ 1351 VCFRONT2_a466_flowIndexFiltered 1;
BA_ "Confidence" SG_ 1351 VCFRONT2_a466_subcool 1;
BA_ "Confidence" SG_ 1351 VCFRONT2_a466_subcoolFiltered 1;
BA_ "Confidence" SG_ 1351 VCFRONT2_a467_powerIndexFiltered 1;
BA_ "Confidence" SG_ 1351 VCFRONT2_a470_pressureLiquid 1;
BA_ "Confidence" SG_ 1351 VCFRONT2_a470_pressureDischarge 1;
BA_ "Confidence" SG_ 1351 VCFRONT2_a490_coolantPumpType 1;
BA_ "Confidence" SG_ 1351 VCFRONT2_a511_PCSEFuseCurrent 1;
BA_ "Confidence" SG_ 1351 VCFRONT2_a511_DCDCMaxOutputCurre 1;
BA_ "SystemSignalLongSymbol" SG_ 1351 VCFRONT2_a511_DCDCMaxOutputCurre "VCFRONT2_a511_DCDCMaxOutputCurrentAllowed";
BA_ "Confidence" SG_ 1351 VCFRONT2_a511_hvState 1;
BA_ "SystemSignalLongSymbol" SG_ 1351 VCFRONT2_a511_DCDCOutputIsLimite "VCFRONT2_a511_DCDCOutputIsLimited";
BA_ "Confidence" SG_ 1351 VCFRONT2_a531_powerIndexFiltered 1;
BA_ "SystemSignalLongSymbol" SG_ 1351 VCFRONT2_a560_highSHBattConditio "VCFRONT2_a560_highSHBattConditioning";
BA_ "SystemSignalLongSymbol" SG_ 1351 VCFRONT2_a560_highSHCabinReheatC "VCFRONT2_a560_highSHCabinReheatCD";
BA_ "SystemSignalLongSymbol" SG_ 1351 VCFRONT2_a560_highSHCabinReheatH "VCFRONT2_a560_highSHCabinReheatHD";
BA_ "SystemSignalLongSymbol" SG_ 1351 VCFRONT2_a615_FRONTIPC_switchSta "VCFRONT2_a615_FRONTIPC_switchStatus";
BA_ "SystemSignalLongSymbol" SG_ 1351 VCFRONT2_a616_FRONTIPC_switchSta "VCFRONT2_a616_FRONTIPC_switchStatus";
BA_ "Confidence" SG_ 1351 VCFRONT2_a667_hcmRegionAndSide 1;
BA_ "GenSigSNA" SG_ 1351 VCFRONT2_a667_hcmRegionAndSide "0";
BA_ "Confidence" SG_ 1351 VCFRONT2_a667_homologationRegion 1;
BA_ "SystemSignalLongSymbol" SG_ 1351 VCFRONT2_a667_homologationRegion "VCFRONT2_a667_homologationRegionOverride";
BA_ "SystemSignalLongSymbol" SG_ 1351 VCFRONT2_a697_isVirtualPitchSens "VCFRONT2_a697_isVirtualPitchSensor";
BA_ "Confidence" SG_ 1351 VCFRONT2_a697_calibratedVertical 1;
BA_ "GenSigSNA" SG_ 1351 VCFRONT2_a697_calibratedVertical "1023";
BA_ "SystemSignalLongSymbol" SG_ 1351 VCFRONT2_a697_calibratedVertical "VCFRONT2_a697_calibratedVerticalPositionHCML";
BA_ "Confidence" SG_ 1351 VCFRONT2_a697_calibratedHorizont 1;
BA_ "GenSigSNA" SG_ 1351 VCFRONT2_a697_calibratedHorizont "1023";
BA_ "SystemSignalLongSymbol" SG_ 1351 VCFRONT2_a697_calibratedHorizont "VCFRONT2_a697_calibratedHorizontalPositionHCML";
BA_ "Confidence" SG_ 834 VCFRONT2_matrixIndex 1;
BA_ "SystemSignalLongSymbol" SG_ 834 VCFRONT2_a004_adaptiveHeadlights "VCFRONT2_a004_adaptiveHeadlightsUnavailable";
BA_ "SystemSignalLongSymbol" SG_ 834 VCFRONT2_a008_adaptiveHeadlights "VCFRONT2_a008_adaptiveHeadlightsUnavailableStalk";
BA_ "SystemSignalLongSymbol" SG_ 834 VCFRONT2_a030_ECULogUploadReques "VCFRONT2_a030_ECULogUploadRequest";
BA_ "SystemSignalLongSymbol" SG_ 834 VCFRONT2_a054_compressorLowFlowU "VCFRONT2_a054_compressorLowFlowUserFacing";
BA_ "SystemSignalLongSymbol" SG_ 834 VCFRONT2_a058_inputRHighSyncDebu "VCFRONT2_a058_inputRHighSyncDebug";
BA_ "SystemSignalLongSymbol" SG_ 834 VCFRONT2_a059_inputResistanceHig "VCFRONT2_a059_inputResistanceHigh";
BA_ "SystemSignalLongSymbol" SG_ 834 VCFRONT2_a123_VC_SECONDARY_LIGHT "VCFRONT2_a123_VC_SECONDARY_LIGHTING_LEADER_MIA";
BA_ "SystemSignalLongSymbol" SG_ 834 VCFRONT2_a143_powerLossDuringSle "VCFRONT2_a143_powerLossDuringSleep";
BA_ "SystemSignalLongSymbol" SG_ 834 VCFRONT2_a153_userPresenceDispla "VCFRONT2_a153_userPresenceDisplayMismatchClrd";
BA_ "SystemSignalLongSymbol" SG_ 834 VCFRONT2_a155_autopilotDriveNotA "VCFRONT2_a155_autopilotDriveNotAuthed";
BA_ "SystemSignalLongSymbol" SG_ 834 VCFRONT2_a160_compressorInhibite "VCFRONT2_a160_compressorInhibited";
BA_ "SystemSignalLongSymbol" SG_ 834 VCFRONT2_a161_compressorSelfFaul "VCFRONT2_a161_compressorSelfFault";
BA_ "SystemSignalLongSymbol" SG_ 834 VCFRONT2_a162_compressorInhibite "VCFRONT2_a162_compressorInhibitedContext";
BA_ "SystemSignalLongSymbol" SG_ 834 VCFRONT2_a163_compressorDisabled "VCFRONT2_a163_compressorDisabledFSR";
BA_ "SystemSignalLongSymbol" SG_ 834 VCFRONT2_a172_wsteHtBlckdByMsmtc "VCFRONT2_a172_wsteHtBlckdByMsmtch";
BA_ "SystemSignalLongSymbol" SG_ 834 VCFRONT2_a184_cabinCoolingPerfor "VCFRONT2_a184_cabinCoolingPerformanceAbnormal";
BA_ "SystemSignalLongSymbol" SG_ 834 VCFRONT2_a195_drveBlckdVltgeTooH "VCFRONT2_a195_drveBlckdVltgeTooHgh";
BA_ "SystemSignalLongSymbol" SG_ 834 VCFRONT2_a217_battPumpCompromise "VCFRONT2_a217_battPumpCompromised";
BA_ "SystemSignalLongSymbol" SG_ 834 VCFRONT2_a218_socMonitorDetected "VCFRONT2_a218_socMonitorDetectedThresholdSoc";
BA_ "SystemSignalLongSymbol" SG_ 834 VCFRONT2_a225_driveBlckdByShowro "VCFRONT2_a225_driveBlckdByShowroom";
BA_ "SystemSignalLongSymbol" SG_ 834 VCFRONT2_a232_lowSideControllerH "VCFRONT2_a232_lowSideControllerHighFdbk";
BA_ "SystemSignalLongSymbol" SG_ 834 VCFRONT2_a235_ptTempSnsIrrationa "VCFRONT2_a235_ptTempSnsIrrational";
BA_ "SystemSignalLongSymbol" SG_ 834 VCFRONT2_a236_batTempSnsIrration "VCFRONT2_a236_batTempSnsIrrational";
BA_ "SystemSignalLongSymbol" SG_ 834 VCFRONT2_a249_coolantValveBadMod "VCFRONT2_a249_coolantValveBadMode";
BA_ "SystemSignalLongSymbol" SG_ 834 VCFRONT2_a273_wiperFrictionModel "VCFRONT2_a273_wiperFrictionModelFault";
BA_ "SystemSignalLongSymbol" SG_ 834 VCFRONT2_a279_refrigLiquidTempSn "VCFRONT2_a279_refrigLiquidTempSns";
BA_ "SystemSignalLongSymbol" SG_ 834 VCFRONT2_a280_refrigLiquidPresSn "VCFRONT2_a280_refrigLiquidPresSns";
BA_ "SystemSignalLongSymbol" SG_ 834 VCFRONT2_a281_alcoholInterlockBl "VCFRONT2_a281_alcoholInterlockBlockingDrive";
BA_ "SystemSignalLongSymbol" SG_ 834 VCFRONT2_a282_coolantLevelSensor "VCFRONT2_a282_coolantLevelSensorFault";
BA_ "SystemSignalLongSymbol" SG_ 834 VCFRONT2_a283_thmlFanLimitedByCu "VCFRONT2_a283_thmlFanLimitedByCurrent";
BA_ "SystemSignalLongSymbol" SG_ 834 VCFRONT2_a294_leftSideRepeaterLi "VCFRONT2_a294_leftSideRepeaterLightFault";
BA_ "SystemSignalLongSymbol" SG_ 834 VCFRONT2_a298_radiatorLowAirFlow "VCFRONT2_a298_radiatorLowAirFlowDetected";
BA_ "SystemSignalLongSymbol" SG_ 834 VCFRONT2_a301_wipersFactoryDisab "VCFRONT2_a301_wipersFactoryDisabled";
BA_ "SystemSignalLongSymbol" SG_ 834 VCFRONT2_a360_ungracefulAccPlusE "VCFRONT2_a360_ungracefulAccPlusExit";
BA_ "SystemSignalLongSymbol" SG_ 834 VCFRONT2_a365_burnInRoutineEnter "VCFRONT2_a365_burnInRoutineEntered";
BA_ "SystemSignalLongSymbol" SG_ 834 VCFRONT2_a366_burnInRoutineExite "VCFRONT2_a366_burnInRoutineExited";
BA_ "SystemSignalLongSymbol" SG_ 834 VCFRONT2_a367_dischargeRoutineEn "VCFRONT2_a367_dischargeRoutineEntered";
BA_ "SystemSignalLongSymbol" SG_ 834 VCFRONT2_a368_dischargeRoutineEx "VCFRONT2_a368_dischargeRoutineExited";
BA_ "SystemSignalLongSymbol" SG_ 834 VCFRONT2_a369_reducedPowerDischa "VCFRONT2_a369_reducedPowerDischarge";
BA_ "SystemSignalLongSymbol" SG_ 834 VCFRONT2_a374_lccInletSolenoidFa "VCFRONT2_a374_lccInletSolenoidFault";
BA_ "SystemSignalLongSymbol" SG_ 834 VCFRONT2_a381_evaporatorExvWarni "VCFRONT2_a381_evaporatorExvWarning";
BA_ "SystemSignalLongSymbol" SG_ 834 VCFRONT2_a393_ambientTempNetwork "VCFRONT2_a393_ambientTempNetworkSna";
BA_ "SystemSignalLongSymbol" SG_ 834 VCFRONT2_a394_pressureSensorChec "VCFRONT2_a394_pressureSensorCheckFault";
BA_ "SystemSignalLongSymbol" SG_ 834 VCFRONT2_a395_pressureSensorChec "VCFRONT2_a395_pressureSensorCheckInconclusive";
BA_ "SystemSignalLongSymbol" SG_ 834 VCFRONT2_a396_coolantLevelLowUse "VCFRONT2_a396_coolantLevelLowUserFacing";
BA_ "SystemSignalLongSymbol" SG_ 834 VCFRONT2_a397_temperatureSensorC "VCFRONT2_a397_temperatureSensorCheckFault";
BA_ "SystemSignalLongSymbol" SG_ 834 VCFRONT2_a398_tempSensorCheckInc "VCFRONT2_a398_tempSensorCheckInconclusive";
BA_ "SystemSignalLongSymbol" SG_ 834 VCFRONT2_a409_invalidConfigurati "VCFRONT2_a409_invalidConfiguration";
BA_ "SystemSignalLongSymbol" SG_ 834 VCFRONT2_a421_leftHeadlampUartCo "VCFRONT2_a421_leftHeadlampUartCondition";
BA_ "SystemSignalLongSymbol" SG_ 834 VCFRONT2_a446_cabinHVACUnavailab "VCFRONT2_a446_cabinHVACUnavailableContext";
BA_ "SystemSignalLongSymbol" SG_ 834 VCFRONT2_a447_cabinHVACUnavailab "VCFRONT2_a447_cabinHVACUnavailable";
BA_ "SystemSignalLongSymbol" SG_ 834 VCFRONT2_a451_refrigerantNotComm "VCFRONT2_a451_refrigerantNotCommissioned";
BA_ "SystemSignalLongSymbol" SG_ 834 VCFRONT2_a452_dischargePresSensI "VCFRONT2_a452_dischargePresSensIntermittent";
BA_ "SystemSignalLongSymbol" SG_ 834 VCFRONT2_a453_dischargeTempSensI "VCFRONT2_a453_dischargeTempSensIntermittent";
BA_ "SystemSignalLongSymbol" SG_ 834 VCFRONT2_a454_suctionPresSensInt "VCFRONT2_a454_suctionPresSensIntermittent";
BA_ "SystemSignalLongSymbol" SG_ 834 VCFRONT2_a455_suctionTempSensInt "VCFRONT2_a455_suctionTempSensIntermittent";
BA_ "SystemSignalLongSymbol" SG_ 834 VCFRONT2_a456_liquidPresSensInte "VCFRONT2_a456_liquidPresSensIntermittent";
BA_ "SystemSignalLongSymbol" SG_ 834 VCFRONT2_a457_liquidTempSensInte "VCFRONT2_a457_liquidTempSensIntermittent";
BA_ "SystemSignalLongSymbol" SG_ 834 VCFRONT2_a458_grosslyLowRefriger "VCFRONT2_a458_grosslyLowRefrigerant";
BA_ "SystemSignalLongSymbol" SG_ 834 VCFRONT2_a459_thermalFillAndDriv "VCFRONT2_a459_thermalFillAndDrive";
BA_ "SystemSignalLongSymbol" SG_ 834 VCFRONT2_a460_hardIsentropicTdFa "VCFRONT2_a460_hardIsentropicTdFailed";
BA_ "SystemSignalLongSymbol" SG_ 834 VCFRONT2_a464_highFlowIndexHighS "VCFRONT2_a464_highFlowIndexHighSubcoolFlagged";
BA_ "SystemSignalLongSymbol" SG_ 834 VCFRONT2_a465_lowFlowIndexHighSu "VCFRONT2_a465_lowFlowIndexHighSubcoolFlagged";
BA_ "SystemSignalLongSymbol" SG_ 834 VCFRONT2_a466_highFlowIndexLowSu "VCFRONT2_a466_highFlowIndexLowSubcoolFlagged";
BA_ "SystemSignalLongSymbol" SG_ 834 VCFRONT2_a467_lowPowerIndexFlagg "VCFRONT2_a467_lowPowerIndexFlagged";
BA_ "SystemSignalLongSymbol" SG_ 834 VCFRONT2_a468_highPowerIndexFlag "VCFRONT2_a468_highPowerIndexFlagged";
BA_ "SystemSignalLongSymbol" SG_ 834 VCFRONT2_a470_implausiblePdPlDet "VCFRONT2_a470_implausiblePdPlDetected";
BA_ "SystemSignalLongSymbol" SG_ 834 VCFRONT2_a474_leftHeadlampIntern "VCFRONT2_a474_leftHeadlampInternalError";
BA_ "SystemSignalLongSymbol" SG_ 834 VCFRONT2_a490_coolantPumpsNotIde "VCFRONT2_a490_coolantPumpsNotIdentified";
BA_ "SystemSignalLongSymbol" SG_ 834 VCFRONT2_a499_loadShedPumpFlowRe "VCFRONT2_a499_loadShedPumpFlowRequest";
BA_ "SystemSignalLongSymbol" SG_ 834 VCFRONT2_a504_airInRefrigerantDe "VCFRONT2_a504_airInRefrigerantDetected";
BA_ "SystemSignalLongSymbol" SG_ 834 VCFRONT2_a506_invalidRefrigerant "VCFRONT2_a506_invalidRefrigerantSystemConfig";
BA_ "SystemSignalLongSymbol" SG_ 834 VCFRONT2_a507_leftHeadlampAiming "VCFRONT2_a507_leftHeadlampAimingFault";
BA_ "SystemSignalLongSymbol" SG_ 834 VCFRONT2_a511_DCDCSaturationLoad "VCFRONT2_a511_DCDCSaturationLoadShed";
BA_ "SystemSignalLongSymbol" SG_ 834 VCFRONT2_a519_leftHeadlampIntern "VCFRONT2_a519_leftHeadlampInternalErrorV2";
BA_ "SystemSignalLongSymbol" SG_ 834 VCFRONT2_a531_lowPowerIndexFlagg "VCFRONT2_a531_lowPowerIndexFlaggedUserFacing";
BA_ "SystemSignalLongSymbol" SG_ 834 VCFRONT2_a534_chillerExvCalibIni "VCFRONT2_a534_chillerExvCalibInitDebug";
BA_ "SystemSignalLongSymbol" SG_ 834 VCFRONT2_a535_evapExvCalibInitDe "VCFRONT2_a535_evapExvCalibInitDebug";
BA_ "SystemSignalLongSymbol" SG_ 834 VCFRONT2_a536_recircExvCalibInit "VCFRONT2_a536_recircExvCalibInitDebug";
BA_ "SystemSignalLongSymbol" SG_ 834 VCFRONT2_a537_lccExvCalibInitDeb "VCFRONT2_a537_lccExvCalibInitDebug";
BA_ "SystemSignalLongSymbol" SG_ 834 VCFRONT2_a538_cclExvCalibInitDeb "VCFRONT2_a538_cclExvCalibInitDebug";
BA_ "SystemSignalLongSymbol" SG_ 834 VCFRONT2_a539_ccrExvCalibInitDeb "VCFRONT2_a539_ccrExvCalibInitDebug";
BA_ "SystemSignalLongSymbol" SG_ 834 VCFRONT2_a540_radiatorSteamDetec "VCFRONT2_a540_radiatorSteamDetected";
BA_ "SystemSignalLongSymbol" SG_ 834 VCFRONT2_a543_compressorLowFlowD "VCFRONT2_a543_compressorLowFlowDeliveryDetected";
BA_ "SystemSignalLongSymbol" SG_ 834 VCFRONT2_a546_leftLowOrHighBeamL "VCFRONT2_a546_leftLowOrHighBeamLightCondition";
BA_ "SystemSignalLongSymbol" SG_ 834 VCFRONT2_a549_leftHeadlampIntern "VCFRONT2_a549_leftHeadlampInternalErrorV3";
BA_ "SystemSignalLongSymbol" SG_ 834 VCFRONT2_a560_compressorHighSupe "VCFRONT2_a560_compressorHighSuperheat";
BA_ "SystemSignalLongSymbol" SG_ 834 VCFRONT2_a563_chargePortDoorOpen "VCFRONT2_a563_chargePortDoorOpenBlockedByBrake";
BA_ "SystemSignalLongSymbol" SG_ 834 VCFRONT2_a564_leftHeadlampAiming "VCFRONT2_a564_leftHeadlampAimingDebug";
BA_ "SystemSignalLongSymbol" SG_ 834 VCFRONT2_a565_userPresenceDispla "VCFRONT2_a565_userPresenceDisplayStateMismatch";
BA_ "SystemSignalLongSymbol" SG_ 834 VCFRONT2_a566_leftFrontTurnLight "VCFRONT2_a566_leftFrontTurnLightFault";
BA_ "SystemSignalLongSymbol" SG_ 834 VCFRONT2_a568_leftDaytimeRunning "VCFRONT2_a568_leftDaytimeRunningLightFault";
BA_ "SystemSignalLongSymbol" SG_ 834 VCFRONT2_a570_headlampsAdaptedTo "VCFRONT2_a570_headlampsAdaptedToLeftHandTraffic";
BA_ "SystemSignalLongSymbol" SG_ 834 VCFRONT2_a571_headlampsAdaptedTo "VCFRONT2_a571_headlampsAdaptedToRightHandTraffic";
BA_ "SystemSignalLongSymbol" SG_ 834 VCFRONT2_a572_hvacCompressorEFus "VCFRONT2_a572_hvacCompressorEFuseTrip";
BA_ "SystemSignalLongSymbol" SG_ 834 VCFRONT2_a578_vbusFusedLowCurren "VCFRONT2_a578_vbusFusedLowCurrentFeedEFuseTrip";
BA_ "SystemSignalLongSymbol" SG_ 834 VCFRONT2_a585_bothHeadlampsInter "VCFRONT2_a585_bothHeadlampsInternalError";
BA_ "SystemSignalLongSymbol" SG_ 834 VCFRONT2_a601_autopilotAirPurgeL "VCFRONT2_a601_autopilotAirPurgeLimitReached";
BA_ "SystemSignalLongSymbol" SG_ 834 VCFRONT2_a602_unknownTurnIndicat "VCFRONT2_a602_unknownTurnIndicatorConfig";
BA_ "SystemSignalLongSymbol" SG_ 834 VCFRONT2_a603_unexpectedTurnIndi "VCFRONT2_a603_unexpectedTurnIndicatorConfigChange";
BA_ "SystemSignalLongSymbol" SG_ 834 VCFRONT2_a604_turnIndicatorConfi "VCFRONT2_a604_turnIndicatorConfigInputMismatch";
BA_ "SystemSignalLongSymbol" SG_ 834 VCFRONT2_a606_chillerBattHeating "VCFRONT2_a606_chillerBattHeatingExit";
BA_ "SystemSignalLongSymbol" SG_ 834 VCFRONT2_a611_poorRadiatorHeatRe "VCFRONT2_a611_poorRadiatorHeatRejection";
BA_ "SystemSignalLongSymbol" SG_ 834 VCFRONT2_a612_selfTestsBlockingD "VCFRONT2_a612_selfTestsBlockingDrive";
BA_ "SystemSignalLongSymbol" SG_ 834 VCFRONT2_a614_coolantSysDriverle "VCFRONT2_a614_coolantSysDriverlessSelfTest";
BA_ "SystemSignalLongSymbol" SG_ 834 VCFRONT2_a618_cabinCoolingCapaci "VCFRONT2_a618_cabinCoolingCapacityLimited";
BA_ "SystemSignalLongSymbol" SG_ 834 VCFRONT2_a621_coolantAirPurgeInc "VCFRONT2_a621_coolantAirPurgeIncomplete";
BA_ "SystemSignalLongSymbol" SG_ 834 VCFRONT2_a622_pumpDetectsLowCool "VCFRONT2_a622_pumpDetectsLowCoolantFlow";
BA_ "SystemSignalLongSymbol" SG_ 834 VCFRONT2_a625_leftHeadlampIntern "VCFRONT2_a625_leftHeadlampInternalErrorV4";
BA_ "SystemSignalLongSymbol" SG_ 834 VCFRONT2_a630_leftHeadlampFactor "VCFRONT2_a630_leftHeadlampFactoryFault";
BA_ "SystemSignalLongSymbol" SG_ 834 VCFRONT2_d636_ptCoolantPumpDetec "VCFRONT2_d636_ptCoolantPumpDetectsAirInSystem";
BA_ "SystemSignalLongSymbol" SG_ 834 VCFRONT2_d637_battCoolantPumpDet "VCFRONT2_d637_battCoolantPumpDetectsAirInSystem";
BA_ "SystemSignalLongSymbol" SG_ 834 VCFRONT2_d638_ptCoolantTempSenso "VCFRONT2_d638_ptCoolantTempSensorIssue";
BA_ "SystemSignalLongSymbol" SG_ 834 VCFRONT2_d639_batteryCoolantTemp "VCFRONT2_d639_batteryCoolantTempSensorIssue";
BA_ "SystemSignalLongSymbol" SG_ 834 VCFRONT2_d640_firmwareVersionMis "VCFRONT2_d640_firmwareVersionMismatch";
BA_ "SystemSignalLongSymbol" SG_ 834 VCFRONT2_d641_ptCoolantPumpCircu "VCFRONT2_d641_ptCoolantPumpCircuitOpen";
BA_ "SystemSignalLongSymbol" SG_ 834 VCFRONT2_d642_batteryCoolantPump "VCFRONT2_d642_batteryCoolantPumpCircuitOpen";
BA_ "SystemSignalLongSymbol" SG_ 834 VCFRONT2_d652_ptCoolantPumpCircu "VCFRONT2_d652_ptCoolantPumpCircuitIssue";
BA_ "SystemSignalLongSymbol" SG_ 834 VCFRONT2_d653_ptCoolantPumpCommL "VCFRONT2_d653_ptCoolantPumpCommLost";
BA_ "SystemSignalLongSymbol" SG_ 834 VCFRONT2_d654_batteryCoolantPump "VCFRONT2_d654_batteryCoolantPumpStall";
BA_ "SystemSignalLongSymbol" SG_ 834 VCFRONT2_d655_batteryCoolantPump "VCFRONT2_d655_batteryCoolantPumpCircuitIssue";
BA_ "SystemSignalLongSymbol" SG_ 834 VCFRONT2_d656_batteryCoolantPump "VCFRONT2_d656_batteryCoolantPumpCommLost";
BA_ "SystemSignalLongSymbol" SG_ 834 VCFRONT2_d657_radiatorFanOperati "VCFRONT2_d657_radiatorFanOperationIssue";
BA_ "SystemSignalLongSymbol" SG_ 834 VCFRONT2_d658_radiatorFanCircuit "VCFRONT2_d658_radiatorFanCircuitIssue";
BA_ "SystemSignalLongSymbol" SG_ 834 VCFRONT2_d659_radiatorFanCommLos "VCFRONT2_d659_radiatorFanCommLost";
BA_ "SystemSignalLongSymbol" SG_ 834 VCFRONT2_d660_coolantValveCircui "VCFRONT2_d660_coolantValveCircuitIssue";
BA_ "SystemSignalLongSymbol" SG_ 834 VCFRONT2_a661_mculessLeftHeadlam "VCFRONT2_a661_mculessLeftHeadlampCurrentAlertDbg";
BA_ "SystemSignalLongSymbol" SG_ 834 VCFRONT2_a662_driveExitBlockedIn "VCFRONT2_a662_driveExitBlockedIndefinitelyBySelfTestRequest";
BA_ "SystemSignalLongSymbol" SG_ 834 VCFRONT2_a663_leftHeadlampUartWa "VCFRONT2_a663_leftHeadlampUartWaterMarkWarning";
BA_ "SystemSignalLongSymbol" SG_ 834 VCFRONT2_a665_leftHeadlampRetryI "VCFRONT2_a665_leftHeadlampRetryInfo";
BA_ "SystemSignalLongSymbol" SG_ 834 VCFRONT2_a667_leftHeadlampRegion "VCFRONT2_a667_leftHeadlampRegionOrSideMismatch";
BA_ "SystemSignalLongSymbol" SG_ 834 VCFRONT2_a669_thermalHVPowerBudg "VCFRONT2_a669_thermalHVPowerBudgetActive";
BA_ "SystemSignalLongSymbol" SG_ 834 VCFRONT2_a697_leftHeadlampNotAim "VCFRONT2_a697_leftHeadlampNotAimed";
BA_ "SystemSignalLongSymbol" SG_ 834 VCFRONT2_a702_dynamicHeadlightLe "VCFRONT2_a702_dynamicHeadlightLevelingUnavailable";
BA_ "Confidence" SG_ 1583 VCFRONT2_udsResponseData 1;
BA_ "Confidence" SG_ 609 VCFRONT_12VBatteryStatusIndex 1;
BA_ "Confidence" SG_ 609 VCFRONT_good12VforUpdate 0;
BA_ "Confidence" SG_ 609 VCFRONT_LVLoadRequest 0;
BA_ "Confidence" SG_ 609 VCFRONT_12VBatteryStatusCounter 0;
BA_ "Confidence" SG_ 609 VCFRONT_12VBatteryStatusChecksum 0;
BA_ "Confidence" SG_ 609 VCFRONT_batterySupportRequest 0;
BA_ "Confidence" SG_ 609 VCFRONT_batterySMState 0;
BA_ "Confidence" SG_ 609 VCFRONT_eFuseRecoveryStateDBG 0;
BA_ "Confidence" SG_ 609 VCFRONT_batteryLINScheduleDBG 0;
BA_ "GenSigSNA" SG_ 609 VCFRONT_batteryLINScheduleDBG "7";
BA_ "Confidence" SG_ 609 VCFRONT_resistanceEstimationTest 3;
BA_ "SystemSignalLongSymbol" SG_ 609 VCFRONT_resistanceEstimationTest "VCFRONT_resistanceEstimationTestCounter";
BA_ "Confidence" SG_ 609 VCFRONT_IBSCurrent 0;
BA_ "Confidence" SG_ 609 VCFRONT_IBSVoltage 0;
BA_ "GenSigSNA" SG_ 609 VCFRONT_IBSVoltage "4095";
BA_ "Confidence" SG_ 609 VCFRONT_reverseBatteryFault 0;
BA_ "Confidence" SG_ 609 VCFRONT_LVBatterySupported 0;
BA_ "Confidence" SG_ 609 VCFRONT_LVBatteryCannotSupportVe 0;
BA_ "SystemSignalLongSymbol" SG_ 609 VCFRONT_LVBatteryCannotSupportVe "VCFRONT_LVBatteryCannotSupportVehicle";
BA_ "Confidence" SG_ 609 VCFRONT_goodTemp12VforUpdate 0;
BA_ "Confidence" SG_ 609 VCFRONT_12VBatteryTargetVoltage 0;
BA_ "Confidence" SG_ 609 VCFRONT_IBSTemperature 0;
BA_ "GenSigSNA" SG_ 609 VCFRONT_IBSTemperature "2047";
BA_ "Confidence" SG_ 609 VCFRONT_currentSensorMismatchLea 0;
BA_ "SystemSignalLongSymbol" SG_ 609 VCFRONT_currentSensorMismatchLea "VCFRONT_currentSensorMismatchLeakyBktPctDBG";
BA_ "Confidence" SG_ 609 VCFRONT_LVBatteryEnergyRemaining 0;
BA_ "SystemSignalLongSymbol" SG_ 609 VCFRONT_LVBatteryEnergyRemaining "VCFRONT_LVBatteryEnergyRemainingPCT";
BA_ "Confidence" SG_ 609 VCFRONT_LVBatteryStatusForDrive 0;
BA_ "Confidence" SG_ 609 VCFRONT_LVBatteryType 0;
BA_ "Confidence" SG_ 609 VCFRONT_resistanceEstimationNeed 0;
BA_ "SystemSignalLongSymbol" SG_ 609 VCFRONT_resistanceEstimationNeed "VCFRONT_resistanceEstimationNeeded";
BA_ "Confidence" SG_ 609 VCFRONT_IBSVoltageFiltered 0;
BA_ "GenSigSNA" SG_ 609 VCFRONT_IBSVoltageFiltered "16383";
BA_ "Confidence" SG_ 609 VCFRONT_LVBMS_LVBusVoltageSource 0;
BA_ "SystemSignalLongSymbol" SG_ 609 VCFRONT_LVBMS_LVBusVoltageSource "VCFRONT_LVBMS_LVBusVoltageSourceDBG";
BA_ "Confidence" SG_ 609 VCFRONT_LVBMS_LVPackCurrentSourc 0;
BA_ "SystemSignalLongSymbol" SG_ 609 VCFRONT_LVBMS_LVPackCurrentSourc "VCFRONT_LVBMS_LVPackCurrentSourceDBG";
BA_ "Confidence" SG_ 609 VCFRONT_LVBatterySupportRqrdTrig 0;
BA_ "SystemSignalLongSymbol" SG_ 609 VCFRONT_LVBatterySupportRqrdTrig "VCFRONT_LVBatterySupportRqrdTrigger";
BA_ "Confidence" SG_ 609 VCFRONT_goodForPCSPowerCycleLeak 0;
BA_ "SystemSignalLongSymbol" SG_ 609 VCFRONT_goodForPCSPowerCycleLeak "VCFRONT_goodForPCSPowerCycleLeakyBktDBG";
BA_ "Confidence" SG_ 609 VCFRONT_LVBusControlsFutile 0;
BA_ "Confidence" SG_ 609 VCFRONT_resistanceEstimatio_0001 0;
BA_ "SystemSignalLongSymbol" SG_ 609 VCFRONT_resistanceEstimatio_0001 "VCFRONT_resistanceEstimationTestValid";
BA_ "Confidence" SG_ 609 VCFRONT_resistanceEstimatio_0002 0;
BA_ "SystemSignalLongSymbol" SG_ 609 VCFRONT_resistanceEstimatio_0002 "VCFRONT_resistanceEstimationTestsExpended";
BA_ "Confidence" SG_ 609 VCFRONT_goodLVChargeForUpdate 0;
BA_ "Confidence" SG_ 609 VCFRONT_opportunisticDCRTestNeed 0;
BA_ "SystemSignalLongSymbol" SG_ 609 VCFRONT_opportunisticDCRTestNeed "VCFRONT_opportunisticDCRTestNeeded";
BA_ "Confidence" SG_ 609 VCFRONT_voltageProfile 0;
BA_ "Confidence" SG_ 609 VCFRONT_IBSAmpHours 0;
BA_ "Confidence" SG_ 609 VCFRONT_IBSVoltageRawDBG 0;
BA_ "GenSigSNA" SG_ 609 VCFRONT_IBSVoltageRawDBG "16383";
BA_ "Confidence" SG_ 609 VCFRONT_LVBatteryLINCommsDetecte 0;
BA_ "SystemSignalLongSymbol" SG_ 609 VCFRONT_LVBatteryLINCommsDetecte "VCFRONT_LVBatteryLINCommsDetectedDBG";
BA_ "Confidence" SG_ 609 VCFRONT_voltageSensorMismatchLea 0;
BA_ "SystemSignalLongSymbol" SG_ 609 VCFRONT_voltageSensorMismatchLea "VCFRONT_voltageSensorMismatchLeakyBktPctDBG";
BA_ "Confidence" SG_ 609 VCFRONT_LVBusControlMode 0;
BA_ "Confidence" SG_ 609 VCFRONT_resistanceEstimationExte 0;
BA_ "SystemSignalLongSymbol" SG_ 609 VCFRONT_resistanceEstimationExte "VCFRONT_resistanceEstimationExtendedTestEnabled";
BA_ "Confidence" SG_ 609 VCFRONT_LVBatteryFctryLimOverrid 0;
BA_ "SystemSignalLongSymbol" SG_ 609 VCFRONT_LVBatteryFctryLimOverrid "VCFRONT_LVBatteryFctryLimOverrideOk";
BA_ "Confidence" SG_ 609 VCFRONT_LVBatterySPICommsDetecte 0;
BA_ "SystemSignalLongSymbol" SG_ 609 VCFRONT_LVBatterySPICommsDetecte "VCFRONT_LVBatterySPICommsDetectedDBG";
BA_ "Confidence" SG_ 609 VCFRONT_targetCurrent 0;
BA_ "Confidence" SG_ 609 VCFRONT_PCSMia 0;
BA_ "Confidence" SG_ 609 VCFRONT_chargeNeeded 0;
BA_ "Confidence" SG_ 609 VCFRONT_voltageControlLoopIntegr 0;
BA_ "SystemSignalLongSymbol" SG_ 609 VCFRONT_voltageControlLoopIntegr "VCFRONT_voltageControlLoopIntegrationVal";
BA_ "Confidence" SG_ 609 VCFRONT_currentControlLoopIntegr 0;
BA_ "SystemSignalLongSymbol" SG_ 609 VCFRONT_currentControlLoopIntegr "VCFRONT_currentControlLoopIntegrationVal";
BA_ "Confidence" SG_ 1847 VCFRONT_LVBMS_InfoIndex 1;
BA_ "Confidence" SG_ 1847 VCFRONT_LVBMS_PcbaId 0;
BA_ "Confidence" SG_ 1847 VCFRONT_LVBMS_AssemblyId 0;
BA_ "Confidence" SG_ 1847 VCFRONT_LVBMS_SubUsageId 0;
BA_ "GenSigSNA" SG_ 1847 VCFRONT_LVBMS_SubUsageId "65535";
BA_ "Confidence" SG_ 1847 VCFRONT_LVBMS_UsageId 0;
BA_ "Confidence" SG_ 1847 VCFRONT_LVBMS_AppCRC 0;
BA_ "Confidence" SG_ 1847 VCFRONT_LVBMS_FWBuildType 0;
BA_ "Confidence" SG_ 1140 VCFRONT_LVHealthChecksum 0;
BA_ "Confidence" SG_ 1140 VCFRONT_LVHealthCounter 0;
BA_ "Confidence" SG_ 1140 VCFRONT_LVHealthStatus 0;
BA_ "Confidence" SG_ 1140 VCFRONT_LVStatusForDrive 0;
BA_ "Confidence" SG_ 1140 VCFRONT_LVPowerSecondsToSafeHarb 0;
BA_ "SystemSignalLongSymbol" SG_ 1140 VCFRONT_LVPowerSecondsToSafeHarb "VCFRONT_LVPowerSecondsToSafeHarbor";
BA_ "Confidence" SG_ 1140 VCFRONT_hardwareProtectionsArmed 0;
BA_ "Confidence" SG_ 1140 VCFRONT_lockoutStrategy 0;
BA_ "Confidence" SG_ 1173 VCFRONT_LVHealthDebugIndex 1;
BA_ "Confidence" SG_ 1173 VCFRONT_LVHEALTH_placeholder 0;
BA_ "Confidence" SG_ 1173 VCFRONT_LVHEALTH_activeDecelEner 0;
BA_ "SystemSignalLongSymbol" SG_ 1173 VCFRONT_LVHEALTH_activeDecelEner "VCFRONT_LVHEALTH_activeDecelEnergyWarning";
BA_ "Confidence" SG_ 1173 VCFRONT_LVHEALTH_criticalPullove 0;
BA_ "SystemSignalLongSymbol" SG_ 1173 VCFRONT_LVHEALTH_criticalPullove "VCFRONT_LVHEALTH_criticalPulloverEnergyWarning";
BA_ "Confidence" SG_ 1173 VCFRONT_LVHEALTH_revBattEFuseOff 0;
BA_ "Confidence" SG_ 1173 VCFRONT_LVHEALTH_LVBMBEFuseOpen 0;
BA_ "Confidence" SG_ 1173 VCFRONT_LVHEALTH_lvBatteryCommsM 0;
BA_ "SystemSignalLongSymbol" SG_ 1173 VCFRONT_LVHEALTH_lvBatteryCommsM "VCFRONT_LVHEALTH_lvBatteryCommsMia";
BA_ "Confidence" SG_ 1173 VCFRONT_LVHEALTH_pcsEFuseOff 0;
BA_ "Confidence" SG_ 1173 VCFRONT_LVHEALTH_pcsNotActive 0;
BA_ "Confidence" SG_ 1173 VCFRONT_LVHEALTH_pcsMIA 0;
BA_ "Confidence" SG_ 1173 VCFRONT_LVHEALTH_IBSMIA 0;
BA_ "Confidence" SG_ 1173 VCFRONT_LVHEALTH_LVBatteryElecDi 0;
BA_ "SystemSignalLongSymbol" SG_ 1173 VCFRONT_LVHEALTH_LVBatteryElecDi "VCFRONT_LVHEALTH_LVBatteryElecDisc";
BA_ "Confidence" SG_ 1173 VCFRONT_LVHEALTH_LVBatteryE_0001 0;
BA_ "SystemSignalLongSymbol" SG_ 1173 VCFRONT_LVHEALTH_LVBatteryE_0001 "VCFRONT_LVHEALTH_LVBatteryElecDiscUnknown";
BA_ "Confidence" SG_ 1173 VCFRONT_LVHEALTH_pcsOpenCircuit 0;
BA_ "Confidence" SG_ 1173 VCFRONT_LVHEALTH_activeDecelPowe 0;
BA_ "SystemSignalLongSymbol" SG_ 1173 VCFRONT_LVHEALTH_activeDecelPowe "VCFRONT_LVHEALTH_activeDecelPowerWarning";
BA_ "Confidence" SG_ 1173 VCFRONT_LVHEALTH_lvBatteryCapabi 0;
BA_ "SystemSignalLongSymbol" SG_ 1173 VCFRONT_LVHEALTH_lvBatteryCapabi "VCFRONT_LVHEALTH_lvBatteryCapabilityLowAccuracy";
BA_ "Confidence" SG_ 1173 VCFRONT_LVHEALTH_lvBatteryConfig 0;
BA_ "SystemSignalLongSymbol" SG_ 1173 VCFRONT_LVHEALTH_lvBatteryConfig "VCFRONT_LVHEALTH_lvBatteryConfiguration";
BA_ "Confidence" SG_ 1173 VCFRONT_LVHEALTH_lvBatteryImpeda 0;
BA_ "SystemSignalLongSymbol" SG_ 1173 VCFRONT_LVHEALTH_lvBatteryImpeda "VCFRONT_LVHEALTH_lvBatteryImpedance";
BA_ "Confidence" SG_ 1173 VCFRONT_LVHEALTH_lvBatteryExtend 0;
BA_ "SystemSignalLongSymbol" SG_ 1173 VCFRONT_LVHEALTH_lvBatteryExtend "VCFRONT_LVHEALTH_lvBatteryExtendedOverVoltage";
VAL_ 1351 VCFRONT2_alertID 702 "a702_dynamicHeadlightLevelingUnavailable" 697 "a697_leftHeadlampNotAimed" 669 "a669_thermalHVPowerBudgetActive" 667 "a667_leftHeadlampRegionOrSideMismatch" 665 "a665_leftHeadlampRetryInfo" 663 "a663_leftHeadlampUartWaterMarkWarning" 662 "a662_driveExitBlockedIndefinitelyBySelfTestRequest" 661 "a661_mculessLeftHeadlampCurrentAlertDbg" 660 "d660_coolantValveCircuitIssue" 659 "d659_radiatorFanCommLost" 658 "d658_radiatorFanCircuitIssue" 657 "d657_radiatorFanOperationIssue" 656 "d656_batteryCoolantPumpCommLost" 655 "d655_batteryCoolantPumpCircuitIssue" 654 "d654_batteryCoolantPumpStall" 653 "d653_ptCoolantPumpCommLost" 652 "d652_ptCoolantPumpCircuitIssue" 651 "d651_ptCoolantPumpStall" 650 "d650_lowCoolantLevel" 648 "d648_louverBlocked" 647 "d647_louverCommLost" 642 "d642_batteryCoolantPumpCircuitOpen" 641 "d641_ptCoolantPumpCircuitOpen" 640 "d640_firmwareVersionMismatch" 639 "d639_batteryCoolantTempSensorIssue" 638 "d638_ptCoolantTempSensorIssue" 637 "d637_battCoolantPumpDetectsAirInSystem" 636 "d636_ptCoolantPumpDetectsAirInSystem" 630 "a630_leftHeadlampFactoryFault" 625 "a625_leftHeadlampInternalErrorV4" 622 "a622_pumpDetectsLowCoolantFlow" 621 "a621_coolantAirPurgeIncomplete" 620 "a620_pumpAirLock" 618 "a618_cabinCoolingCapacityLimited" 617 "a617_APP_MIA" 616 "a616_VCSEAT2R_MIA" 615 "a615_VCSEAT2L_MIA" 614 "a614_coolantSysDriverlessSelfTest" 612 "a612_selfTestsBlockingDrive" 611 "a611_poorRadiatorHeatRejection" 610 "a610_driveEntryDelayed" 606 "a606_chillerBattHeatingExit" 604 "a604_turnIndicatorConfigInputMismatch" 603 "a603_unexpectedTurnIndicatorConfigChange" 602 "a602_unknownTurnIndicatorConfig" 601 "a601_autopilotAirPurgeLimitReached" 585 "a585_bothHeadlampsInternalError" 578 "a578_vbusFusedLowCurrentFeedEFuseTrip" 572 "a572_hvacCompressorEFuseTrip" 571 "a571_headlampsAdaptedToRightHandTraffic" 570 "a570_headlampsAdaptedToLeftHandTraffic" 568 "a568_leftDaytimeRunningLightFault" 566 "a566_leftFrontTurnLightFault" 565 "a565_userPresenceDisplayStateMismatch" 564 "a564_leftHeadlampAimingDebug" 563 "a563_chargePortDoorOpenBlockedByBrake" 560 "a560_compressorHighSuperheat" 549 "a549_leftHeadlampInternalErrorV3" 546 "a546_leftLowOrHighBeamLightCondition" 543 "a543_compressorLowFlowDeliveryDetected" 542 "a542_refrigerantReclaim" 540 "a540_radiatorSteamDetected" 539 "a539_ccrExvCalibInitDebug" 538 "a538_cclExvCalibInitDebug" 537 "a537_lccExvCalibInitDebug" 536 "a536_recircExvCalibInitDebug" 535 "a535_evapExvCalibInitDebug" 534 "a534_chillerExvCalibInitDebug" 531 "a531_lowPowerIndexFlaggedUserFacing" 519 "a519_leftHeadlampInternalErrorV2" 511 "a511_DCDCSaturationLoadShed" 507 "a507_leftHeadlampAimingFault" 506 "a506_invalidRefrigerantSystemConfig" 504 "a504_airInRefrigerantDetected" 499 "a499_loadShedPumpFlowRequest" 490 "a490_coolantPumpsNotIdentified" 489 "a489_ValveStuckFlagged" 474 "a474_leftHeadlampInternalError" 471 "a471_hcm5Debug" 470 "a470_implausiblePdPlDetected" 469 "a469_prvPopDetected" 468 "a468_highPowerIndexFlagged" 467 "a467_lowPowerIndexFlagged" 466 "a466_highFlowIndexLowSubcoolFlagged" 465 "a465_lowFlowIndexHighSubcoolFlagged" 464 "a464_highFlowIndexHighSubcoolFlagged" 460 "a460_hardIsentropicTdFailed" 459 "a459_thermalFillAndDrive" 458 "a458_grosslyLowRefrigerant" 457 "a457_liquidTempSensIntermittent" 456 "a456_liquidPresSensIntermittent" 455 "a455_suctionTempSensIntermittent" 454 "a454_suctionPresSensIntermittent" 453 "a453_dischargeTempSensIntermittent" 452 "a452_dischargePresSensIntermittent" 451 "a451_refrigerantNotCommissioned" 447 "a447_cabinHVACUnavailable" 446 "a446_cabinHVACUnavailableContext" 423 "a423_rtosSleepFailed" 421 "a421_leftHeadlampUartCondition" 420 "a420_holidayParty" 409 "a409_invalidConfiguration" 398 "a398_tempSensorCheckInconclusive" 397 "a397_temperatureSensorCheckFault" 396 "a396_coolantLevelLowUserFacing" 395 "a395_pressureSensorCheckInconclusive" 394 "a394_pressureSensorCheckFault" 393 "a393_ambientTempNetworkSna" 386 "a386_exvMotorWarning" 385 "a385_ccRightExvWarning" 384 "a384_ccLeftExvWarning" 383 "a383_lccExvWarning" 382 "a382_recircExvWarning" 381 "a381_evaporatorExvWarning" 380 "a380_chillerExvWarning" 378 "a378_wiperECUDebug" 377 "a377_wiperParkFault" 374 "a374_lccInletSolenoidFault" 369 "a369_reducedPowerDischarge" 368 "a368_dischargeRoutineExited" 367 "a367_dischargeRoutineEntered" 366 "a366_burnInRoutineExited" 365 "a365_burnInRoutineEntered" 360 "a360_ungracefulAccPlusExit" 356 "a356_refrigSysLockout" 355 "a355_coolantSysLockout" 302 "a302_wiperCommError" 301 "a301_wipersFactoryDisabled" 298 "a298_radiatorLowAirFlowDetected" 294 "a294_leftSideRepeaterLightFault" 289 "a289_ccRightExvFault" 288 "a288_ccLeftExvFault" 287 "a287_lccExvFault" 286 "a286_recircExvFault" 285 "a285_evaporatorExvFault" 284 "a284_chillerExvFault" 283 "a283_thmlFanLimitedByCurrent" 282 "a282_coolantLevelSensorFault" 281 "a281_alcoholInterlockBlockingDrive" 280 "a280_refrigLiquidPresSns" 279 "a279_refrigLiquidTempSns" 273 "a273_wiperFrictionModelFault" 254 "a254_pumpBatStopped" 251 "a251_UIWakeupTrigger" 250 "a250_headlampsNotAimed" 249 "a249_coolantValveBadMode" 247 "a247_evapSolenoidFault" 240 "a240_lowSideCompromised" 236 "a236_batTempSnsIrrational" 235 "a235_ptTempSnsIrrational" 232 "a232_lowSideControllerHighFdbk" 226 "a226_battPumpMIA" 225 "a225_driveBlckdByShowroom" 218 "a218_socMonitorDetectedThresholdSoc" 217 "a217_battPumpCompromised" 215 "a215_ptPumpMIA" 214 "a214_ptPumpCompromised" 210 "a210_coolantValveCalib" 195 "a195_drveBlckdVltgeTooHgh" 188 "a188_sleepFailed" 187 "a187_busesNotSleeping" 186 "a186_noDriveChgCableCon" 184 "a184_cabinCoolingPerformanceAbnormal" 178 "a178_compLiquidPumpOut" 176 "a176_vehicleInSelfTest" 174 "a174_driveNotAuthed" 173 "a173_HVBlckdByMsmtch" 172 "a172_wsteHtBlckdByMsmtch" 171 "a171_driveBlckdByMsmtch" 167 "a167_leftHCMMIA" 163 "a163_compressorDisabledFSR" 162 "a162_compressorInhibitedContext" 161 "a161_compressorSelfFault" 160 "a160_compressorInhibited" 159 "a159_coolantValveFault" 155 "a155_autopilotDriveNotAuthed" 153 "a153_userPresenceDisplayMismatchClrd" 150 "a150_pumpBatLowRPMCBang" 144 "a144_EPAS3S_MIA" 143 "a143_powerLossDuringSleep" 142 "a142_exvMotorFault" 141 "a141_coolantTempBatSns" 140 "a140_coolantTempPtSns" 139 "a139_refrigSuctPresSns" 138 "a138_refrigSuctTempSns" 137 "a137_refrigDischPresSns" 136 "a136_refrigDischTempSns" 135 "a135_coolantLevelLow" 133 "a133_BRAKE_MIA" 131 "a131_PCSCOMMON_MIA" 126 "a126_EPAS3P_MIA" 125 "a125_SCCM_MIA" 124 "a124_BB_MIA" 123 "a123_VC_SECONDARY_LIGHTING_LEADER_MIA" 122 "a122_ICR_MIA" 120 "a120_DI_DRIVE_MIA" 119 "a119_SCCM_MIA" 118 "a118_VCFRONT_MIA" 117 "a117_VCLEFT_MIA" 116 "a116_VCRIGHT_MIA" 115 "a115_VCSEC_MIA" 114 "a114_ESP_MIA" 113 "a113_UI_MIA" 112 "a112_EPBL_MIA" 111 "a111_EPBR_MIA" 110 "a110_GTW_MIA" 109 "a109_RCM_MIA" 108 "a108_DIF_MIA" 107 "a107_BMS_MIA" 106 "a106_PCS_MIA" 105 "a105_TAS_MIA" 104 "a104_DAS_MIA" 103 "a103_CP_MIA" 100 "a100_CANbus_MIA" 98 "a098_DIR_MIA" 96 "a096_OCS1P_MIA" 91 "a091_CMPD_MIA" 90 "a090_APS_MIA" 86 "a086_VCBATT_MIA" 82 "a082_VCFRONT2_MIA" 81 "a081_VCFRONT1_MIA" 80 "a080_VCFRONT0_MIA" 79 "a079_VCBATT2_MIA" 78 "a078_VCBATT1_MIA" 77 "a077_VCBATT0_MIA" 64 "a064_busSleepReqTimeout" 63 "a063_SwitchFault" 62 "a062_XCPWasConnected" 61 "a061_XCPConnected" 60 "a060_engineeringBuild" 59 "a059_inputResistanceHigh" 58 "a058_inputRHighSyncDebug" 54 "a054_compressorLowFlowUserFacing" 53 "a053_wiperCommErrorUser" 46 "a046_Task1000msError" 45 "a045_Task100msError" 44 "a044_Task10msError" 43 "a043_Task1msError" 42 "a042_HighStackUsage" 41 "a041_HighCPULoad" 40 "a040_Backtrace" 39 "a039_ProtFaultAddress" 38 "a038_ProtFaultInfo" 37 "a037_MemManageFault" 36 "a036_UnknownIrq" 31 "a031_UDSActive" 30 "a030_ECULogUploadRequest" 29 "a029_CoreDump" 28 "a028_UsageFault" 22 "a022_TaskInitError" 21 "a021_TaskSchedulerError" 19 "a019_BusFault" 18 "a018_HardFault" 17 "a017_NVMMStatusDbg" 16 "a016_NVMMRecordError" 15 "a015_NVMMError" 13 "a013_AlertManagerFault" 12 "a012_CPUReset" 9 "a009_LCCPurgeAttempted" 8 "a008_adaptiveHeadlightsUnavailableStalk" 6 "a006_CANTX_cyclicError" 5 "a005_CANTXError" 4 "a004_adaptiveHeadlightsUnavailable" 3 "a003_SWAssertion" 2 "a002_PowerLossReset" 1 "a001_WatchdogReset" 0 "ALERT_DO_NOT_USE_ZERO" ;
VAL_ 1351 VCFRONT2_alertState 1 "SET" 0 "CLEARED" ;
VAL_ 1351 VCFRONT2_a142_driverState 10 "DRIVER_FAULT" 9 "FAULT_OPEN_COIL" 8 "FAULT_SHORT_COIL" 7 "STALL" 6 "READY" 5 "ENABLE_MOTOR" 4 "COMM_ERROR" 3 "INIT_COMM" 2 "RESET" 1 "UNPOWERED" 0 "UNKNOWN" ;
VAL_ 1351 VCFRONT2_a176_vehicleState 16 "RESET" 15 "LOW_POWER_STANDBY" 14 "SLEEP_SHUTDOWN" 13 "GO_QUIET" 12 "LV_SHUTDOWN" 11 "JUMP_START" 10 "LV_ON" 9 "SYSTEM_CHECKS" 8 "TURN_ON_LV" 7 "WAIT_FOR_HIGH_POWER" 6 "OTA" 5 "DRIVE" 4 "ACCESSORY_PLUS" 3 "ACCESSORY" 2 "CONDITIONING" 1 "LOW_POWER_AWAKE" 0 "INIT" ;
VAL_ 1351 VCFRONT2_a214_selfTestResult 7 "PASSED" 6 "UNKNOWN" 5 "OPEN_PHASE_W" 4 "OPEN_PHASE_V" 3 "OPEN_PHASE_U" 2 "SHORT_GROUND" 1 "SHORT_SUPPLY" 0 "NOT_TESTED" ;
VAL_ 1351 VCFRONT2_a217_selfTestResult 7 "PASSED" 6 "UNKNOWN" 5 "OPEN_PHASE_W" 4 "OPEN_PHASE_V" 3 "OPEN_PHASE_U" 2 "SHORT_GROUND" 1 "SHORT_SUPPLY" 0 "NOT_TESTED" ;
VAL_ 1351 VCFRONT2_a284_driverState 10 "DRIVER_FAULT" 9 "FAULT_OPEN_COIL" 8 "FAULT_SHORT_COIL" 7 "STALL" 6 "READY" 5 "ENABLE_MOTOR" 4 "COMM_ERROR" 3 "INIT_COMM" 2 "RESET" 1 "UNPOWERED" 0 "UNKNOWN" ;
VAL_ 1351 VCFRONT2_a285_driverState 10 "DRIVER_FAULT" 9 "FAULT_OPEN_COIL" 8 "FAULT_SHORT_COIL" 7 "STALL" 6 "READY" 5 "ENABLE_MOTOR" 4 "COMM_ERROR" 3 "INIT_COMM" 2 "RESET" 1 "UNPOWERED" 0 "UNKNOWN" ;
VAL_ 1351 VCFRONT2_a286_driverState 10 "DRIVER_FAULT" 9 "FAULT_OPEN_COIL" 8 "FAULT_SHORT_COIL" 7 "STALL" 6 "READY" 5 "ENABLE_MOTOR" 4 "COMM_ERROR" 3 "INIT_COMM" 2 "RESET" 1 "UNPOWERED" 0 "UNKNOWN" ;
VAL_ 1351 VCFRONT2_a287_driverState 10 "DRIVER_FAULT" 9 "FAULT_OPEN_COIL" 8 "FAULT_SHORT_COIL" 7 "STALL" 6 "READY" 5 "ENABLE_MOTOR" 4 "COMM_ERROR" 3 "INIT_COMM" 2 "RESET" 1 "UNPOWERED" 0 "UNKNOWN" ;
VAL_ 1351 VCFRONT2_a288_driverState 10 "DRIVER_FAULT" 9 "FAULT_OPEN_COIL" 8 "FAULT_SHORT_COIL" 7 "STALL" 6 "READY" 5 "ENABLE_MOTOR" 4 "COMM_ERROR" 3 "INIT_COMM" 2 "RESET" 1 "UNPOWERED" 0 "UNKNOWN" ;
VAL_ 1351 VCFRONT2_a289_driverState 10 "DRIVER_FAULT" 9 "FAULT_OPEN_COIL" 8 "FAULT_SHORT_COIL" 7 "STALL" 6 "READY" 5 "ENABLE_MOTOR" 4 "COMM_ERROR" 3 "INIT_COMM" 2 "RESET" 1 "UNPOWERED" 0 "UNKNOWN" ;
VAL_ 1351 VCFRONT2_a302_LINFrameStatus 4 "NA" 3 "ERROR" 2 "TIMEOUT" 1 "OK" 0 "UNKNOWN" ;
VAL_ 1351 VCFRONT2_a368_enteringState 5 "FAULTED" 4 "INHIBIT_FOR_REST" 3 "BATTERY_DISCHARGE" 2 "BATTERY_HEATING" 1 "READY" 0 "NOT_READY" ;
VAL_ 1351 VCFRONT2_a368_exitingState 5 "FAULTED" 4 "INHIBIT_FOR_REST" 3 "BATTERY_DISCHARGE" 2 "BATTERY_HEATING" 1 "READY" 0 "NOT_READY" ;
VAL_ 1351 VCFRONT2_a446_hpCabinLoadType 3 "EVAP" 2 "REHEAT" 1 "CC" 0 "NONE" ;
VAL_ 1351 VCFRONT2_a446_hpBatteryLoadType 2 "BATT_COOL" 1 "BATT_HEAT" 0 "NONE" ;
VAL_ 1351 VCFRONT2_a490_coolantPumpType 5 "DUAL_MIX" 4 "DUAL_SAN_P4_LUB" 2 "DUAL_SAN_P4" 1 "SINGLE_PUMP_BATT" 0 "DUAL" ;
VAL_ 1351 VCFRONT2_a511_hvState 6 "UP" 5 "UP_FOR_DC_CHARGE" 4 "UP_FOR_CHARGE" 3 "UP_FOR_DRIVE" 2 "GOING_DOWN" 1 "COMING_UP" 0 "DOWN" ;
VAL_ 1351 VCFRONT2_a667_hcmRegionAndSide 6 "ECE_RHD_RIGHT" 5 "ECE_RHD_LEFT" 4 "ECE_LHD_RIGHT" 3 "ECE_LHD_LEFT" 2 "SAE_RIGHT" 1 "SAE_LEFT" 0 "SNA" ;
VAL_ 1351 VCFRONT2_a667_homologationRegion 2 "MX_UNECE" 1 "KR_UNECE" 0 "DEFAULT_FOR_COUNTRY_CODE" ;
VAL_ 1351 VCFRONT2_a697_calibratedVertical 1023 "SNA" 1022 "INVALID_POSITION" ;
VAL_ 1351 VCFRONT2_a697_calibratedHorizont 1023 "SNA" 1022 "INVALID_POSITION" ;
VAL_ 834 VCFRONT2_matrixIndex 11 "AlertMatrix11" 10 "AlertMatrix10" 9 "AlertMatrix9" 8 "AlertMatrix8" 7 "AlertMatrix7" 6 "AlertMatrix6" 5 "AlertMatrix5" 4 "AlertMatrix4" 3 "AlertMatrix3" 2 "AlertMatrix2" 1 "AlertMatrix1" 0 "AlertMatrix0" ;
VAL_ 609 VCFRONT_12VBatteryStatusIndex 5 "Mux5" 4 "Mux4" 3 "Mux3" 2 "Mux2" 1 "Mux1" 0 "Mux0" ;
VAL_ 609 VCFRONT_batterySMState 10 "BATTERY_SM_STATE_EXTERNAL_LV_BUS_CONTROL" 9 "BATTERY_SM_STATE_RECOVERY" 8 "BATTERY_SM_STATE_FAULT" 7 "BATTERY_SM_STATE_SHORTED_CELL_TEST" 6 "BATTERY_SM_STATE_DISCONNECTED_BATTERY_TEST" 5 "BATTERY_SM_STATE_OTA_STANDBY" 4 "BATTERY_SM_STATE_RESISTANCE_ESTIMATION" 3 "BATTERY_SM_STATE_STANDBY" 2 "BATTERY_SM_STATE_DISCHARGE" 1 "BATTERY_SM_STATE_CHARGE" 0 "BATTERY_SM_STATE_INIT" ;
VAL_ 609 VCFRONT_eFuseRecoveryStateDBG 4 "VC_LVBMB_EFUSE_RECOVERY_STATE_BLOCKED" 3 "VC_LVBMB_EFUSE_RECOVERY_STATE_FINISH" 2 "VC_LVBMB_EFUSE_RECOVERY_STATE_CONNECT" 1 "VC_LVBMB_EFUSE_RECOVERY_STATE_SETUP" 0 "VC_LVBMB_EFUSE_RECOVERY_STATE_INACTIVE" ;
VAL_ 609 VCFRONT_batteryLINScheduleDBG 7 "VC_LVBMS_LIN_SCHEDULE_SNA" 6 "VC_LVBMS_LIN_SCHEDULE_OTHER" 4 "VC_LVBMS_LIN_SCHEDULE_DEFAULT_2" 3 "VC_LVBMS_LIN_SCHEDULE_DEFAULT_1" 2 "VC_LVBMS_LIN_SCHEDULE_DIAGNOSTIC" 1 "VC_LVBMS_LIN_SCHEDULE_RESET" 0 "VC_LVBMS_LIN_SCHEDULE_OFF" ;
VAL_ 609 VCFRONT_IBSVoltage 4095 "SNA" ;
VAL_ 609 VCFRONT_IBSTemperature 2047 "IBS_TEMPERATURE_SNA" ;
VAL_ 609 VCFRONT_LVBatteryStatusForDrive 2 "LV_BATTERY_EXIT_DRIVE_REQUESTED" 1 "LV_BATTERY_READY_FOR_DRIVE" 0 "LV_BATTERY_NOT_READY_FOR_DRIVE" ;
VAL_ 609 VCFRONT_LVBatteryType 5 "LV_BATTERY_TYPE_TESLA_48V_LI_ION" 4 "LV_BATTERY_TYPE_TESLA_16V_LI_ION" 3 "LV_BATTERY_TYPE_CATL_LI_ION" 2 "LV_BATTERY_TYPE_CLARIOS_B24_FLOODED" 1 "LV_BATTERY_TYPE_ATLASBX_B24_FLOODED" 0 "LV_BATTERY_TYPE_UNKNOWN" ;
VAL_ 609 VCFRONT_IBSVoltageFiltered 16383 "SNA" 16382 "MAX" 16381 "MIN" ;
VAL_ 609 VCFRONT_LVBMS_LVBusVoltageSource 3 "VC_LVBMS_VOLTAGE_SOURCE_LVBMS" 2 "VC_LVBMS_VOLTAGE_SOURCE_VBAT_MONITOR" 1 "VC_LVBMS_VOLTAGE_SOURCE_IBS" 0 "VC_LVBMS_VOLTAGE_SOURCE_NONE" ;
VAL_ 609 VCFRONT_LVBMS_LVPackCurrentSourc 2 "VC_LV_PACK_CURRENT_SOURCE_LVBMS" 1 "VC_LV_PACK_CURRENT_SOURCE_IBS" 0 "VC_LV_PACK_CURRENT_SOURCE_NONE" ;
VAL_ 609 VCFRONT_LVBatterySupportRqrdTrig 14336 "LV_BATTERY_SUPPORT_REQUIRED_TRIGGER_SOC_IMBALANCE_AND_CORRECTION" 12288 "LV_BATTERY_SUPPORT_REQUIRED_TRIGGER_IMBALANCE_AND_CORRECTION" 10240 "LV_BATTERY_SUPPORT_REQUIRED_TRIGGER_SOC_AND_CORRECTION" 8192 "LV_BATTERY_SUPPORT_REQUIRED_TRIGGER_CORRECTION" 6144 "LV_BATTERY_SUPPORT_REQUIRED_TRIGGER_SOC_AND_IMBALANCE" 4096 "LV_BATTERY_SUPPORT_REQUIRED_TRIGGER_IMBALANCE" 2048 "LV_BATTERY_SUPPORT_REQUIRED_TRIGGER_SOC" 1024 "LV_BATTERY_SUPPORT_REQUIRED_TRIGGER_POST_OTA" 512 "LV_BATTERY_SUPPORT_REQUIRED_TRIGGER_EXIT_TRANSPORT_MODE" 256 "LV_BATTERY_SUPPORT_REQUIRED_TRIGGER_POWER_ON_RESET" 128 "LV_BATTERY_SUPPORT_REQUIRED_TRIGGER_PERIODIC_CHARGE" 64 "LV_BATTERY_SUPPORT_REQUIRED_TRIGGER_AH_COUNT" 32 "LV_BATTERY_SUPPORT_REQUIRED_TRIGGER_UNKNOWN_VOLTAGE" 20 "LV_BATTERY_SUPPORT_REQUIRED_TRIGGER_RAW_VC_VOLTAGES" 16 "LV_BATTERY_SUPPORT_REQUIRED_TRIGGER_VBAT_RAW_VOLTAGE" 12 "LV_BATTERY_SUPPORT_REQUIRED_TRIGGER_RAW_BATTERY_VOLTAGES" 10 "LV_BATTERY_SUPPORT_REQUIRED_TRIGGER_PACK_VOLTAGES" 8 "LV_BATTERY_SUPPORT_REQUIRED_TRIGGER_PACK_RAW_VOLTAGE" 5 "LV_BATTERY_SUPPORT_REQUIRED_TRIGGER_IBS_VOLTAGES" 4 "LV_BATTERY_SUPPORT_REQUIRED_TRIGGER_IBS_RAW_VOLTAGE" 3 "LV_BATTERY_SUPPORT_REQUIRED_TRIGGER_FILTERED_VOLTAGES" 2 "LV_BATTERY_SUPPORT_REQUIRED_TRIGGER_PACK_FILTERED_VOLTAGE" 1 "LV_BATTERY_SUPPORT_REQUIRED_TRIGGER_IBS_FILTERED_VOLTAGE" 0 "LV_BATTERY_SUPPORT_REQUIRED_TRIGGER_NONE" ;
VAL_ 609 VCFRONT_voltageProfile 3 "VOLTAGE_PROFILE_ALWAYS_CLOSED_CONTACTORS" 2 "VOLTAGE_PROFILE_REDUCED_FLOAT" 1 "VOLTAGE_PROFILE_FLOAT" 0 "VOLTAGE_PROFILE_CHARGE" ;
VAL_ 609 VCFRONT_IBSVoltageRawDBG 16383 "SNA" 16382 "MAX" 16381 "MIN" ;
VAL_ 609 VCFRONT_LVBusControlMode 15 "MODE_RESERVED" 9 "JUMP_POST" 8 "DISCONNECTED_BATTERY_TEST" 7 "LVBMB_EFUSE_RECOVERY" 6 "BATTERY_IMPEDANCE_TEST" 5 "LVBMB_EFUSE_TEST" 4 "BATTERY_CAPACITY_TEST" 3 "BRIDGE_MANAGER" 2 "BLOCK_LV_BATT_CHARGING" 1 "HW_PROT_SELF_TESTS" 0 "LV_BUS_IDLE" ;
VAL_ 1847 VCFRONT_LVBMS_InfoIndex 5 "INVALID" 4 "SERIAL_NUMBER" 3 "BUILDTYPE" 2 "GITHASH" 1 "APP_USAGEID_CRC" 0 "PCBAID_ASSYID" ;
VAL_ 1847 VCFRONT_LVBMS_SubUsageId 65535 "SNA" ;
VAL_ 1847 VCFRONT_LVBMS_FWBuildType 4 "INFO_MFG_BUILD" 3 "INFO_TRACEABLE_CI_BUILD" 2 "INFO_LOCAL_BUILD" 1 "INFO_PLATFORM_BUILD" 0 "INFO_UNKNOWN_BUILD" ;
VAL_ 1140 VCFRONT_LVHealthStatus 6 "POWER_SUPPLY_COMPROMISED" 5 "ENERGY_RESERVE_CRITICAL" 4 "ENERGY_RESERVE_COMPROMISED" 3 "BACKUP_COMPROMISED" 2 "LATENT_FAULT" 1 "HEALTHY_LIMITED" 0 "DOMAIN_HEALTHY" ;
VAL_ 1140 VCFRONT_LVStatusForDrive 6 "STATUS_FOR_DRIVE_ACTIVE_DECEL" 5 "STATUS_FOR_DRIVE_PULL_TO_SHOULDER" 4 "STATUS_FOR_DRIVE_LIMP" 3 "STATUS_FOR_DRIVE_RETURN_TO_SERVICE" 2 "STATUS_FOR_DRIVE_READY_LIMITED" 1 "STATUS_FOR_DRIVE_READY" 0 "STATUS_FOR_DRIVE_NOT_READY" ;
VAL_ 1140 VCFRONT_LVPowerSecondsToSafeHarb 65535 "INDEFINITE" ;
VAL_ 1140 VCFRONT_lockoutStrategy 1 "PARK_STATUS" 0 "POWER_STATE" ;
VAL_ 1173 VCFRONT_LVHealthDebugIndex 1 "FRONT_CHECK_RESULTS_1" 0 "UNHEALTHY_REASONS" ;
